VERSION ""

NS_ :

BS_:

BU_:IC_MMI GW AC AVM BCM DSM_D DSM_P FSCM PSR CWC
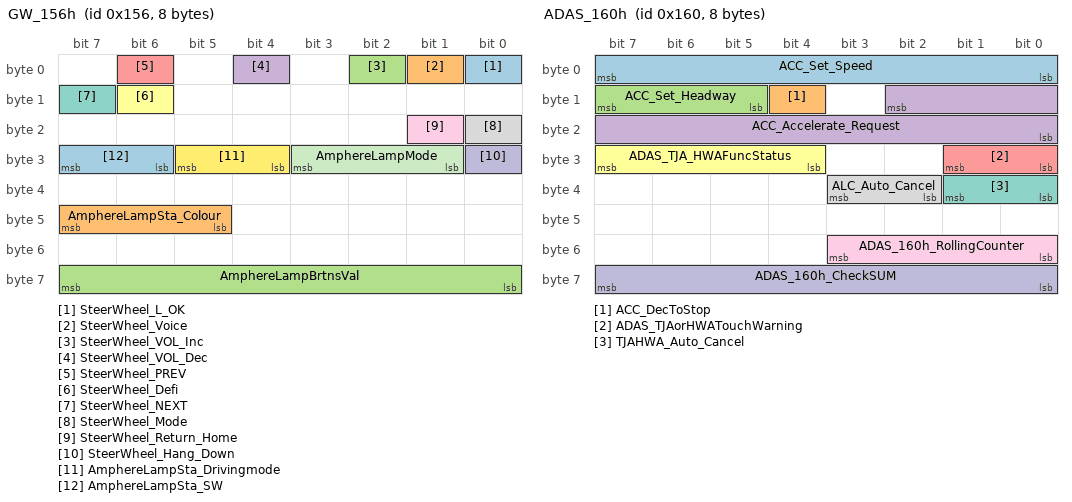
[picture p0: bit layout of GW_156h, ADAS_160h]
BO_ 342 GW_156h: 8 GW
 SG_ SteerWheel_L_OK : 0|1@0+ (1,0) [0|1] "" IC_MMI
 SG_ SteerWheel_Voice : 1|1@0+ (1,0) [0|1] "" IC_MMI
 SG_ SteerWheel_VOL_Inc : 2|1@0+ (1,0) [0|1] "" IC_MMI
 SG_ SteerWheel_VOL_Dec : 4|1@0+ (1,0) [0|1] "" IC_MMI
 SG_ SteerWheel_PREV : 6|1@0+ (1,0) [0|1] "" IC_MMI
 SG_ SteerWheel_Defi : 14|1@0+ (1,0) [0|1] "" IC_MMI
 SG_ SteerWheel_NEXT : 15|1@0+ (1,0) [0|1] "" IC_MMI
 SG_ SteerWheel_Mode : 16|1@0+ (1,0) [0|1] "" IC_MMI
 SG_ SteerWheel_Return_Home : 17|1@0+ (1,0) [0|1] "" IC_MMI
 SG_ SteerWheel_Hang_Down : 24|1@0+ (1,0) [0|1] "" IC_MMI
 SG_ AmphereLampMode : 27|3@0+ (1,0) [0|7] "" IC_MMI
 SG_ AmphereLampSta_Drivingmode : 29|2@0+ (1,0) [0|3] "" IC_MMI
 SG_ AmphereLampSta_SW : 31|2@0+ (1,0) [0|3] "" IC_MMI
 SG_ AmphereLampSta_Colour : 47|3@0+ (1,0) [0|7] "" IC_MMI
 SG_ AmphereLampBrtnsVal : 63|8@0+ (1,0) [0|100] "%" IC_MMI

BO_ 586 ACU_24Ah: 8 GW
 SG_ ACU_AirBagSysWrnLmpCmd : 4|1@0+ (1,0) [0|1] "" IC_MMI,BCM
 SG_ ACU_Crashinfo : 7|3@0+ (1,0) [0|7] "" IC_MMI,BCM
 SG_ ACU_24Ah_RollingCounter : 51|4@0+ (1,0) [0|15] "" IC_MMI,BCM
 SG_ ACU_24Ah_CheckSUM : 63|8@0+ (1,0) [0|255] "" IC_MMI,BCM

BO_ 352 ADAS_160h: 8 GW
 SG_ ACC_Set_Speed : 7|8@0+ (1,0) [0|255] "kph" IC_MMI
 SG_ ACC_DecToStop : 12|1@0+ (1,0) [0|1] "" Vector__XXX
 SG_ ACC_Set_Headway : 15|3@0+ (1,0) [0|7] "" IC_MMI
 SG_ ACC_Accelerate_Request : 10|11@0+ (0.005,-5) [-5|5] "m/s2" Vector__XXX
 SG_ ADAS_TJAorHWATouchWarning : 25|2@0+ (1,0) [0|3] "" IC_MMI
 SG_ ADAS_TJA_HWAFuncStatus : 31|4@0+ (1,0) [0|10] "" IC_MMI
 SG_ TJAHWA_Auto_Cancel : 33|2@0+ (1,0) [0|3] "" IC_MMI
 SG_ ALC_Auto_Cancel : 35|2@0+ (1,0) [0|3] "" IC_MMI
 SG_ ADAS_160h_RollingCounter : 51|4@0+ (1,0) [0|15] "" IC_MMI
 SG_ ADAS_160h_CheckSUM : 63|8@0+ (1,0) [0|255] "" IC_MMI

BO_ 354 ADAS_162h: 8 GW
 SG_ AEB_ABA_Level : 1|2@0+ (1,0) [0|3] "" AVM
 SG_ AEB_ABA_Req : 2|1@0+ (1,0) [0|1] "" AVM
 SG_ AEB_Prefill_Request : 3|1@0+ (1,0) [0|1] "" Vector__XXX
 SG_ AEB_AWB_Req : 4|1@0+ (1,0) [0|1] "" Vector__XXX
 SG_ AEB_State : 7|3@0+ (1,0) [0|7] "" IC_MMI
 SG_ AEB_DecCtlReq : 16|1@0+ (1,0) [0|1] "" AVM
 SG_ FCW_State : 19|3@0+ (1,0) [0|7] "" IC_MMI
 SG_ AEB_Decelerate_Request : 15|12@0+ (0.01,-20.47) [-20.47|20.47] "m/s2" Vector__XXX
 SG_ ACC_MinBraking : 24|1@0+ (1,0) [0|1] "" AVM
 SG_ ADAS_Sensorstatus : 27|3@0+ (1,0) [0|7] "" IC_MMI
 SG_ HW_Warning_Level : 29|2@0+ (1,0) [0|3] "" IC_MMI
 SG_ FCW_Warning_Level : 31|2@0+ (1,0) [0|3] "" IC_MMI
 SG_ ACC_CIPV_Indicator : 33|1@0+ (1,0) [0|1] "" IC_MMI
 SG_ ACC_Auto_Cancel : 35|2@0+ (1,0) [0|2] "" IC_MMI
 SG_ ACC_Driver_Cancel : 36|1@0+ (1,0) [0|1] "" IC_MMI
 SG_ ACC_ModeReq : 39|3@0+ (1,0) [0|7] "" IC_MMI,AVM
 SG_ AEB_AWB_Level : 41|2@0+ (1,0) [0|3] "" AVM
 SG_ ACC_ShutDownMode : 43|2@0+ (1,0) [0|3] "" AVM
 SG_ ACC_DriveOff : 44|1@0+ (1,0) [0|1] "" AVM
 SG_ ACC_BrkPreferred : 45|1@0+ (1,0) [0|1] "" AVM
 SG_ ACC_Go_Indicator : 46|1@0+ (1,0) [0|1] "" IC_MMI
 SG_ ACC_Takeover_Indicator : 47|1@0+ (1,0) [0|1] "" IC_MMI
 SG_ ADAS_162h_RollingCounter : 51|4@0+ (1,0) [0|15] "" IC_MMI,AVM
 SG_ ADAS_162h_CheckSUM : 63|8@0+ (1,0) [0|255] "" IC_MMI,AVM

BO_ 356 ADAS_164h: 8 GW
 SG_ TSR_State : 2|3@0+ (1,0) [0|4] "" IC_MMI
 SG_ DAS_TSR_Main_Switch : 3|1@0+ (1,0) [0|1] "" IC_MMI
 SG_ IHC_Mainbeam_Request : 4|1@0+ (1,0) [0|1] "" BCM
 SG_ IHC_State : 7|3@0+ (1,0) [0|7] "" IC_MMI,BCM
 SG_ LDW_Line_Detect_Status : 10|3@0+ (1,0) [0|3] "" IC_MMI
 SG_ LDW_Warning : 12|2@0+ (1,0) [0|3] "" IC_MMI
 SG_ LDW_State : 15|3@0+ (1,0) [0|4] "" IC_MMI
 SG_ TSR_Targetspeed_Request : 23|8@0+ (1,0) [0|254] "km/h" IC_MMI
 SG_ LKA_Takeover_Request : 27|1@0+ (1,0) [0|1] "" IC_MMI
 SG_ LKA_Torque_Request_Status : 28|1@0+ (1,0) [0|1] "" Vector__XXX
 SG_ LCK_State : 31|3@0+ (1,0) [0|7] "" IC_MMI
 SG_ LKA_Torque_Request : 26|11@0+ (0.01,-10.24) [-10.24|10.23] "Nm" Vector__XXX
 SG_ ADAS_164h_RollingCounter : 43|4@0+ (1,0) [0|15] "" Vector__XXX
 SG_ LKA_State : 46|3@0+ (1,0) [0|7] "" IC_MMI
 SG_ LKA_Hands_Off_Warning : 47|1@0+ (1,0) [0|1] "" IC_MMI
 SG_ DAS_LDW_Main_Switch : 48|1@0+ (1,0) [0|1] "" IC_MMI
 SG_ DAS_LDW_Sensitivity : 50|2@0+ (1,0) [0|3] "" IC_MMI
 SG_ DAS_FCW_Main_Switch : 51|1@0+ (1,0) [0|1] "" IC_MMI
 SG_ DAS_FCW_Sensitivity : 53|2@0+ (1,0) [0|3] "" IC_MMI
 SG_ DAS_AEB_Main_Switch : 54|1@0+ (1,0) [0|1] "" IC_MMI
 SG_ DAS_IHC_Main_Switch : 55|1@0+ (1,0) [0|1] "" IC_MMI
 SG_ ADAS_164h_CheckSUM : 63|8@0+ (1,0) [0|255] "" IC_MMI

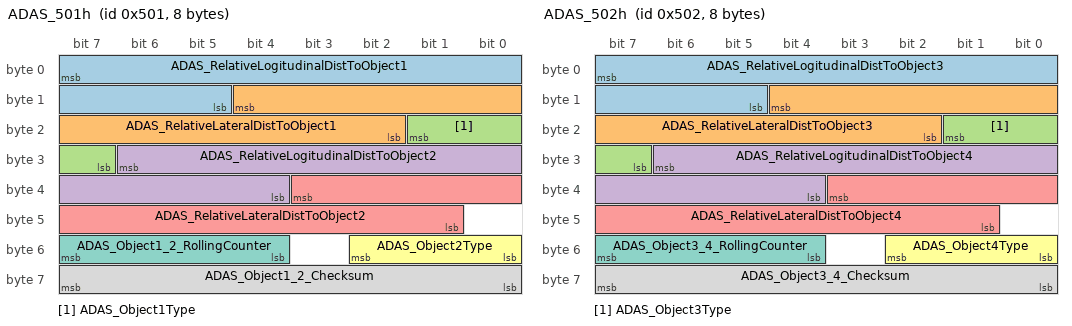
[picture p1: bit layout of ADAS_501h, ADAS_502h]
BO_ 1281 ADAS_501h: 8 GW
 SG_ ADAS_RelativeLogitudinalDistToObject1 : 7|11@0+ (0.1,0) [0|200] "m" IC_MMI
 SG_ ADAS_RelativeLateralDistToObject1 : 12|11@0+ (0.1,-102.4) [-102.4|102.2] "m" IC_MMI
 SG_ ADAS_Object1Type : 17|3@0+ (1,0) [0|7] "" IC_MMI
 SG_ ADAS_RelativeLogitudinalDistToObject2 : 30|11@0+ (0.1,0) [0|200] "m" IC_MMI
 SG_ ADAS_RelativeLateralDistToObject2 : 35|11@0+ (0.1,-102.4) [-102.4|102.2] "m" IC_MMI
 SG_ ADAS_Object2Type : 50|3@0+ (1,0) [0|7] "" IC_MMI
 SG_ ADAS_Object1_2_RollingCounter : 55|4@0+ (1,0) [0|15] "" IC_MMI
 SG_ ADAS_Object1_2_Checksum : 63|8@0+ (1,0) [0|255] "" IC_MMI

BO_ 1282 ADAS_502h: 8 GW
 SG_ ADAS_RelativeLogitudinalDistToObject3 : 7|11@0+ (0.1,0) [0|200] "m" IC_MMI
 SG_ ADAS_RelativeLateralDistToObject3 : 12|11@0+ (0.1,-102.4) [-102.4|102.2] "m" IC_MMI
 SG_ ADAS_Object3Type : 17|3@0+ (1,0) [0|7] "" IC_MMI
 SG_ ADAS_RelativeLogitudinalDistToObject4 : 30|11@0+ (0.1,0) [0|200] "m" IC_MMI
 SG_ ADAS_RelativeLateralDistToObject4 : 35|11@0+ (0.1,-102.4) [-102.4|102.2] "m" IC_MMI
 SG_ ADAS_Object4Type : 50|3@0+ (1,0) [0|7] "" IC_MMI
 SG_ ADAS_Object3_4_RollingCounter : 55|4@0+ (1,0) [0|15] "" IC_MMI
 SG_ ADAS_Object3_4_Checksum : 63|8@0+ (1,0) [0|255] "" IC_MMI

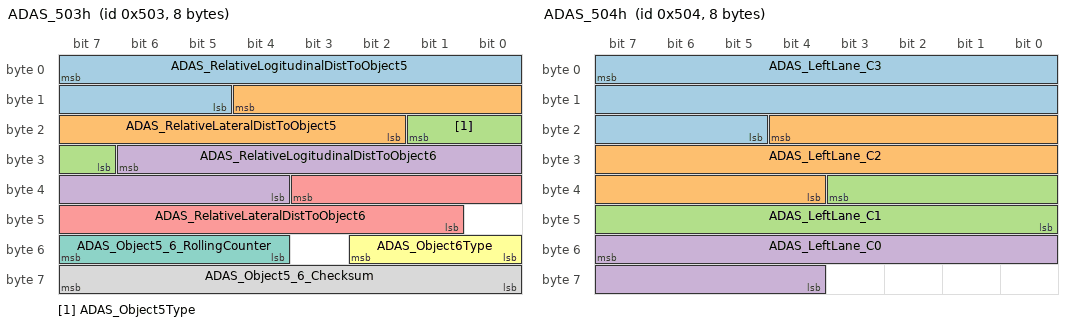
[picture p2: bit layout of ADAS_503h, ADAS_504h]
BO_ 1283 ADAS_503h: 8 GW
 SG_ ADAS_RelativeLogitudinalDistToObject5 : 7|11@0+ (0.1,0) [0|200] "m" IC_MMI
 SG_ ADAS_RelativeLateralDistToObject5 : 12|11@0+ (0.1,-102.4) [-102.4|102.2] "m" IC_MMI
 SG_ ADAS_Object5Type : 17|3@0+ (1,0) [0|7] "" IC_MMI
 SG_ ADAS_RelativeLogitudinalDistToObject6 : 30|11@0+ (0.1,0) [0|200] "m" IC_MMI
 SG_ ADAS_RelativeLateralDistToObject6 : 35|11@0+ (0.1,-102.4) [-102.4|102.2] "m" IC_MMI
 SG_ ADAS_Object6Type : 50|3@0+ (1,0) [0|7] "" IC_MMI
 SG_ ADAS_Object5_6_RollingCounter : 55|4@0+ (1,0) [0|15] "" IC_MMI
 SG_ ADAS_Object5_6_Checksum : 63|8@0+ (1,0) [0|255] "" IC_MMI

BO_ 1284 ADAS_504h: 8 GW
 SG_ ADAS_LeftLane_C3 : 7|19@0+ (5E-09,-0.001) [-0.001|0.001] "1/m2" IC_MMI
 SG_ ADAS_LeftLane_C2 : 20|17@0+ (0.000001,-0.05) [-0.05|0.05] "1/m" IC_MMI
 SG_ ADAS_LeftLane_C1 : 35|12@0+ (0.001,-1.1) [-1.1|1.1] "rad" IC_MMI
 SG_ ADAS_LeftLane_C0 : 55|12@0+ (0.01,-12) [-12|12] "m" IC_MMI

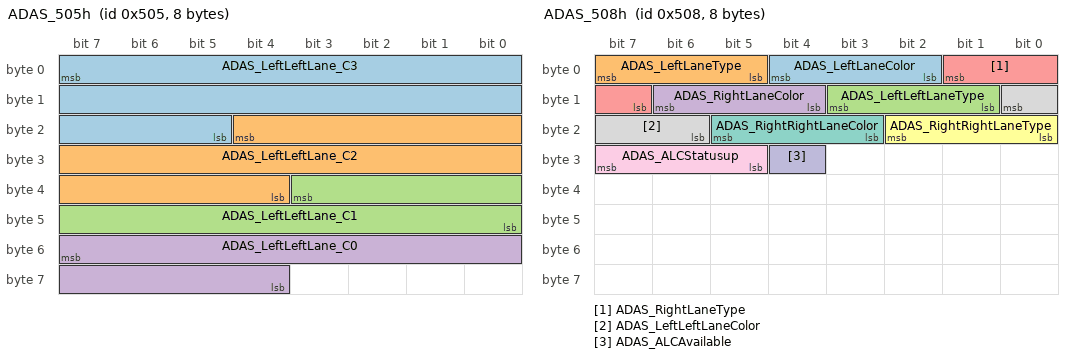
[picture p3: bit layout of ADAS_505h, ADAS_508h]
BO_ 1285 ADAS_505h: 8 GW
 SG_ ADAS_LeftLeftLane_C3 : 7|19@0+ (0.000000005,-0.001) [-0.001|0.001] "1/m2" IC_MMI
 SG_ ADAS_LeftLeftLane_C2 : 20|17@0+ (0.000001,-0.05) [-0.05|0.05] "1/m" IC_MMI
 SG_ ADAS_LeftLeftLane_C1 : 35|12@0+ (0.001,-1.1) [-1.1|1.1] "rad" IC_MMI
 SG_ ADAS_LeftLeftLane_C0 : 55|12@0+ (0.01,-12) [-12|12] "m" IC_MMI

BO_ 1286 ADAS_506h: 8 GW
 SG_ ADAS_RightLane_C3 : 7|19@0+ (0.000000005,-0.001) [-0.001|0.001] "1/m2" IC_MMI
 SG_ ADAS_RightLane_C2 : 20|17@0+ (0.000001,-0.05) [-0.05|0.05] "1/m" IC_MMI
 SG_ ADAS_RightLane_C1 : 35|12@0+ (0.001,-1.1) [-1.1|1.1] "rad" IC_MMI
 SG_ ADAS_RightLane_C0 : 55|12@0+ (0.01,-12) [-12|12] "m" IC_MMI

BO_ 1287 ADAS_507h: 8 GW
 SG_ ADAS_RightRightLane_C3 : 7|19@0+ (0.000000005,-0.001) [-0.001|0.001] "1/m2" IC_MMI
 SG_ ADAS_RightRightLane_C2 : 20|17@0+ (0.000001,-0.05) [-0.05|0.05] "1/m" IC_MMI
 SG_ ADAS_RightRightLane_C1 : 35|12@0+ (0.001,-1.1) [-1.1|1.1] "rad" IC_MMI
 SG_ ADAS_RightRightLane_C0 : 55|12@0+ (0.01,-12) [-12|12] "m" IC_MMI

BO_ 1288 ADAS_508h: 8 GW
 SG_ ADAS_LeftLaneColor : 4|3@0+ (1,0) [0|7] "" IC_MMI
 SG_ ADAS_LeftLaneType : 7|3@0+ (1,0) [0|7] "" IC_MMI
 SG_ ADAS_LeftLeftLaneType : 11|3@0+ (1,0) [0|7] "" IC_MMI
 SG_ ADAS_RightLaneColor : 14|3@0+ (1,0) [0|7] "" IC_MMI
 SG_ ADAS_RightLaneType : 1|3@0+ (1,0) [0|7] "" IC_MMI
 SG_ ADAS_RightRightLaneType : 18|3@0+ (1,0) [0|7] "" IC_MMI
 SG_ ADAS_RightRightLaneColor : 21|3@0+ (1,0) [0|7] "" IC_MMI
 SG_ ADAS_LeftLeftLaneColor : 8|3@0+ (1,0) [0|7] "" IC_MMI
 SG_ ADAS_ALCStatusup : 31|3@0+ (1,0) [0|7] "" IC_MMI
 SG_ ADAS_ALCAvailable : 28|1@0+ (1,0) [0|1] "" IC_MMI

BO_ 384 APA_180h: 8 GW
 SG_ APA_MMI_ConnectStatus : 3|4@0+ (1,0) [0|7] "" IC_MMI
 SG_ APA_MMI_EcuStatus : 7|4@0+ (1,0) [0|3] "" IC_MMI
 SG_ APA_MMI_VideoOutputStatus : 9|2@0+ (1,0) [0|3] "" IC_MMI
 SG_ APA_MMI_3DViewModeStatus : 13|4@0+ (1,0) [0|15] "" IC_MMI
 SG_ APA_MMI_AVM3DViewSwitch : 23|8@0+ (1,0) [0|255] "" IC_MMI
 SG_ APA_Status : 26|3@0+ (1,0) [0|7] "" IC_MMI
 SG_ PAS_APA_Mode : 30|3@0+ (1,0) [0|7] "" IC_MMI
 SG_ PSA_APA_SensorStsLR_RL : 32|1@0+ (1,0) [0|1] "" IC_MMI
 SG_ PSA_APA_SensorStsLR_RR : 33|1@0+ (1,0) [0|1] "" IC_MMI
 SG_ PSA_APA_SensorStsSR_RL : 34|1@0+ (1,0) [0|1] "" IC_MMI
 SG_ PSA_APA_SensorStsSR_RML : 35|1@0+ (1,0) [0|1] "" IC_MMI
 SG_ PAS_APA_SensorStsSR_RMR : 36|1@0+ (1,0) [0|1] "" IC_MMI
 SG_ PAS_APA_SensorStsSR_RR : 37|1@0+ (1,0) [0|1] "" IC_MMI
 SG_ PSA_APA_SensorStsLR_FL : 38|1@0+ (1,0) [0|1] "" IC_MMI
 SG_ PSA_APA_SensorStsLR_FR : 39|1@0+ (1,0) [0|1] "" IC_MMI
 SG_ PSA_APA_SensorStsSR_FL : 40|1@0+ (1,0) [0|1] "" IC_MMI
 SG_ PSA_APA_SensorStsSR_FML : 41|1@0+ (1,0) [0|1] "" IC_MMI
 SG_ PAS_APA_SensorStsSR_FMR : 42|1@0+ (1,0) [0|1] "" IC_MMI
 SG_ PAS_APA_SensorStsSR_FR : 43|1@0+ (1,0) [0|1] "" IC_MMI

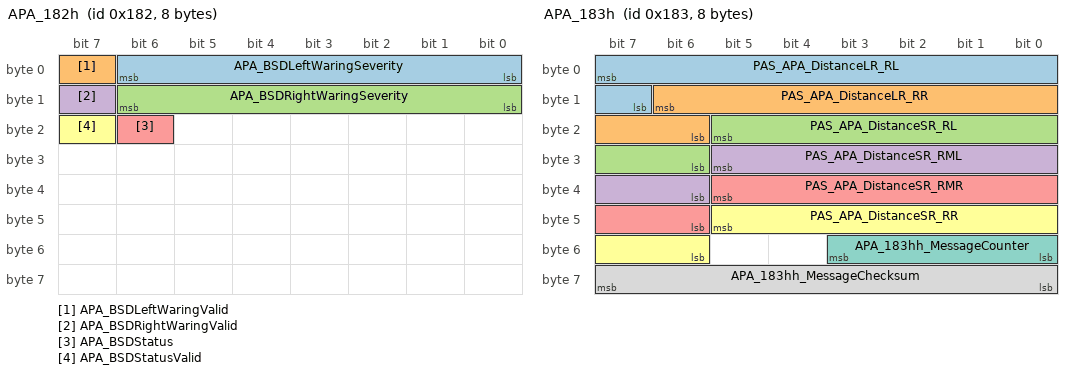
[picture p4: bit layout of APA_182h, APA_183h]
BO_ 386 APA_182h: 8 GW
 SG_ APA_BSDLeftWaringSeverity : 6|7@0+ (1,0) [0|126] "" IC_MMI
 SG_ APA_BSDLeftWaringValid : 7|1@0+ (1,0) [0|1] "" IC_MMI
 SG_ APA_BSDRightWaringSeverity : 14|7@0+ (1,0) [0|126] "" IC_MMI
 SG_ APA_BSDRightWaringValid : 15|1@0+ (1,0) [0|1] "" IC_MMI
 SG_ APA_BSDStatus : 22|1@0+ (1,0) [0|1] "" IC_MMI
 SG_ APA_BSDStatusValid : 23|1@0+ (1,0) [0|1] "" IC_MMI

BO_ 387 APA_183h: 8 GW
 SG_ PAS_APA_DistanceLR_RL : 7|9@0+ (0.01,0) [0|5] "m" IC_MMI
 SG_ PAS_APA_DistanceLR_RR : 14|9@0+ (0.01,0) [0|5] "m" IC_MMI
 SG_ PAS_APA_DistanceSR_RL : 21|8@0+ (0.01,0) [0|2.5] "m" IC_MMI
 SG_ PAS_APA_DistanceSR_RML : 29|8@0+ (0.01,0) [0|2.5] "m" IC_MMI
 SG_ PAS_APA_DistanceSR_RMR : 37|8@0+ (0.01,0) [0|2.5] "m" IC_MMI
 SG_ PAS_APA_DistanceSR_RR : 45|8@0+ (0.01,0) [0|2.5] "m" IC_MMI
 SG_ APA_183hh_MessageCounter : 51|4@0+ (1,0) [0|15] "" IC_MMI
 SG_ APA_183hh_MessageChecksum : 63|8@0+ (1,0) [0|255] "" IC_MMI

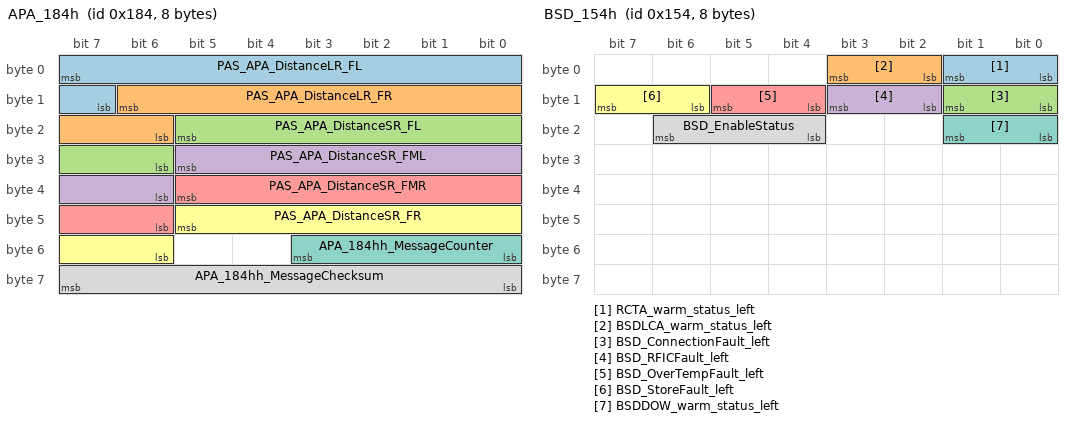
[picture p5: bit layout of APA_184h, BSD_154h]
BO_ 388 APA_184h: 8 GW
 SG_ PAS_APA_DistanceLR_FL : 7|9@0+ (0.01,0) [0|5] "m" IC_MMI
 SG_ PAS_APA_DistanceLR_FR : 14|9@0+ (0.01,0) [0|5] "m" IC_MMI
 SG_ PAS_APA_DistanceSR_FL : 21|8@0+ (0.01,0) [0|2.5] "m" IC_MMI
 SG_ PAS_APA_DistanceSR_FML : 29|8@0+ (0.01,0) [0|2.5] "m" IC_MMI
 SG_ PAS_APA_DistanceSR_FMR : 37|8@0+ (0.01,0) [0|2.5] "m" IC_MMI
 SG_ PAS_APA_DistanceSR_FR : 45|8@0+ (0.01,0) [0|2.5] "m" IC_MMI
 SG_ APA_184hh_MessageCounter : 51|4@0+ (1,0) [0|15] "" IC_MMI
 SG_ APA_184hh_MessageChecksum : 63|8@0+ (1,0) [0|255] "" IC_MMI

BO_ 784 APA_310h: 8 GW
 SG_ APA_AVM_MCU_Version : 15|24@0+ (1,0) [0|16777214] "" IC_MMI
 SG_ APA_AVM_BSP_Version : 39|24@0+ (1,0) [0|16777214] "" IC_MMI

BO_ 786 APA_312h: 8 GW
 SG_ APA_AVM_ZADAS_Version : 15|24@0+ (1,0) [0|16777214] "" IC_MMI
 SG_ APA_Avm3d_licenseStatus : 33|2@0+ (1,0) [0|3] "" IC_MMI
 SG_ APA_BSD_licenseStatus : 35|2@0+ (1,0) [0|3] "" IC_MMI

BO_ 512 BMS_200h: 8 GW
 SG_ BMS_Sys_SumVoltage : 7|16@0+ (0.1,0) [0|6000] "V" IC_MMI,AC
 SG_ BMS_Sys_SumCurrent : 23|16@0+ (0.1,-3000) [-3000|3000] "A" IC_MMI,AC
 SG_ BMS_battery_outside_Voltage : 39|16@0+ (0.1,0) [0|6000] "V" Vector__XXX

BO_ 514 BMS_202h: 8 GW
 SG_ BMS_Err_DischrgAnodeRelay : 1|2@0+ (1,0) [0|3] "" Vector__XXX
 SG_ BMS_DischargeAnodeRelay_status : 3|2@0+ (1,0) [0|3] "" Vector__XXX
 SG_ BMS_Boot_Detection : 4|1@0+ (1,0) [0|1] "" Vector__XXX
 SG_ BMS_A : 5|1@0+ (1,0) [0|1] "" Vector__XXX
 SG_ BMS_Relay_HEAT : 11|2@0+ (1,0) [0|3] "" Vector__XXX
 SG_ BMS_Err_PrechargeAnodeRelay : 13|2@0+ (1,0) [0|3] "" Vector__XXX
 SG_ BMS_Precharge_anode_Relay_status : 15|2@0+ (1,0) [0|3] "" Vector__XXX
 SG_ BMS_ChrgHeatColEnable : 26|3@0+ (1,0) [0|7] "" Vector__XXX
 SG_ BMS_Sys_ChgorDisChrgSts : 28|2@0+ (1,0) [0|3] "" IC_MMI,AC
 SG_ BMS_FastChrgSts : 31|3@0+ (1,0) [0|7] "" IC_MMI
 SG_ BMS_SlowChrgSts : 34|3@0+ (1,0) [0|7] "" IC_MMI
 SG_ BMS_ChrgCouplesSt : 38|2@0+ (1,0) [0|3] "" IC_MMI
 SG_ BMS_req_ConnectChargeRelay : 41|2@0+ (1,0) [0|3] "" Vector__XXX
 SG_ BMS_request_subscribe_allow : 47|1@0+ (1,0) [0|1] "" Vector__XXX
 SG_ BMS_CC2 : 52|3@0+ (1,0) [0|7] "" Vector__XXX
 SG_ BMS_PauseContinueChrgStus : 54|2@0+ (1,0) [0|3] "" IC_MMI
 SG_ BMS_AllowedChrgMaxPower : 62|7@0+ (1,0) [0|100] "%" IC_MMI

BO_ 518 BMS_206h: 8 GW
 SG_ BMS_battery_WaterTemp_in : 2|11@0+ (0.1,-40) [-40|100] "℃" AC
 SG_ BMS_battery_WaterTemp_out : 23|8@0+ (1,-40) [-40|100] "℃" AC
 SG_ BMS_FlowRateReq : 31|8@0+ (1,0) [0|100] "%" AC
 SG_ BMS_InletWaterTempTarget : 39|8@0+ (0.5,-40) [-40|87] "℃" AC
 SG_ BMS_ThermalManageReq : 43|2@0+ (1,0) [0|3] "" IC_MMI,AC

BO_ 524 BMS_20Ch: 8 GW
 SG_ BMS_Powertrain_System_fault : 1|2@0+ (1,0) [0|3] "" IC_MMI
 SG_ BMS_cell_Voltage_low : 5|2@0+ (1,0) [0|3] "" IC_MMI
 SG_ BMS_cell_Voltage_High : 7|2@0+ (1,0) [0|3] "" IC_MMI
 SG_ BMS_Battery_LowTemp_warning : 9|2@0+ (1,0) [0|3] "" IC_MMI
 SG_ BMS_Battery_HighTemp_warning : 11|2@0+ (1,0) [0|3] "" IC_MMI
 SG_ BMS_SOCHigh_Warning : 17|2@0+ (1,0) [0|3] "" IC_MMI
 SG_ BMS_SOCLow_Warning : 19|2@0+ (1,0) [0|3] "" IC_MMI
 SG_ BMS_Battery_SumVoltage_High : 21|2@0+ (1,0) [0|3] "" IC_MMI
 SG_ BMS_Battery_SumVoltage_Low : 23|2@0+ (1,0) [0|3] "" IC_MMI
 SG_ BMS_HVBatCellDiffFalt : 25|2@0+ (1,0) [0|3] "" IC_MMI
 SG_ BMS_SOCJump_Warning : 31|2@0+ (1,0) [0|3] "" IC_MMI
 SG_ BMS_BatNotMatchFlt : 39|2@0+ (1,0) [0|3] "" IC_MMI
 SG_ BMS_Err_ISO_LOW : 41|2@0+ (1,0) [0|3] "" IC_MMI
 SG_ BMS_Err_ChgCurrent_High : 43|2@0+ (1,0) [0|3] "" IC_MMI
 SG_ BMS_Err_DchCurrent_High : 45|2@0+ (1,0) [0|3] "" IC_MMI
 SG_ BMS_Err_DtT_High : 47|2@0+ (1,0) [0|3] "" IC_MMI
 SG_ ThermalManage_System_fault : 49|2@0+ (1,0) [0|3] "" Vector__XXX
 SG_ BMS_Err_comunicacion : 51|2@0+ (1,0) [0|3] "" IC_MMI
 SG_ BMS_Err_InterLock : 52|1@0+ (1,0) [0|1] "" IC_MMI
 SG_ BMS_Circuit_Protection : 53|1@0+ (1,0) [0|1] "" IC_MMI
 SG_ BMS_FeedFault : 55|2@0+ (1,0) [0|3] "" IC_MMI
 SG_ BMS_TotalErrNumber : 63|8@0+ (1,0) [0|254] "" IC_MMI

BO_ 528 BMS_210h: 8 GW
 SG_ BMS_Sys_MinCellV : 7|16@0+ (0.001,0) [0|5] "V" IC_MMI
 SG_ BMS_Sys_MaxCellV : 23|16@0+ (0.001,0) [0|5] "V" IC_MMI
 SG_ BMS_Sys_MinCellV_No : 39|8@0+ (1,0) [0|255] "" IC_MMI
 SG_ BMS_Sys_MaxCellV_No : 47|8@0+ (1,0) [0|255] "" IC_MMI

BO_ 530 BMS_212h: 8 GW
 SG_ BMS_Sys_MinCellT : 7|8@0+ (1,-50) [-50|204] "℃" IC_MMI
 SG_ BMS_Sys_MaxCellT : 15|8@0+ (1,-50) [-50|204] "℃" IC_MMI
 SG_ BMS_Sys_MinCellT_No : 23|8@0+ (1,0) [0|254] "℃" IC_MMI
 SG_ BMS_Sys_MaxCellT_No : 31|8@0+ (1,0) [0|254] "℃" IC_MMI
 SG_ BMS_FastChrgTemp : 39|8@0+ (1,-50) [-50|204] "℃" IC_MMI

BO_ 534 BMS_216h: 8 GW
 SG_ BMS_PosInsulationResistance : 7|16@0+ (1,0) [0|60000] "kΩ" Vector__XXX
 SG_ BMS_NegInsulationResistance : 23|16@0+ (1,0) [0|60000] "kΩ" Vector__XXX
 SG_ BMS_Sys_SOC : 39|8@0+ (1,0) [0|100] "%" IC_MMI
 SG_ BMS_Sys_SOH : 47|8@0+ (1,0) [0|100] "%" IC_MMI

BO_ 340 BSD_154h: 8 GW
 SG_ RCTA_warm_status_left : 1|2@0+ (1,0) [0|3] "" IC_MMI
 SG_ BSDLCA_warm_status_left : 3|2@0+ (1,0) [0|3] "" IC_MMI
 SG_ BSD_ConnectionFault_left : 9|2@0+ (1,0) [0|3] "" IC_MMI
 SG_ BSD_RFICFault_left : 11|2@0+ (1,0) [0|3] "" IC_MMI
 SG_ BSD_OverTempFault_left : 13|2@0+ (1,0) [0|3] "" IC_MMI
 SG_ BSD_StoreFault_left : 15|2@0+ (1,0) [0|3] "" IC_MMI
 SG_ BSDDOW_warm_status_left : 17|2@0+ (1,0) [0|3] "" IC_MMI
 SG_ BSD_EnableStatus : 22|3@0+ (1,0) [0|7] "" IC_MMI

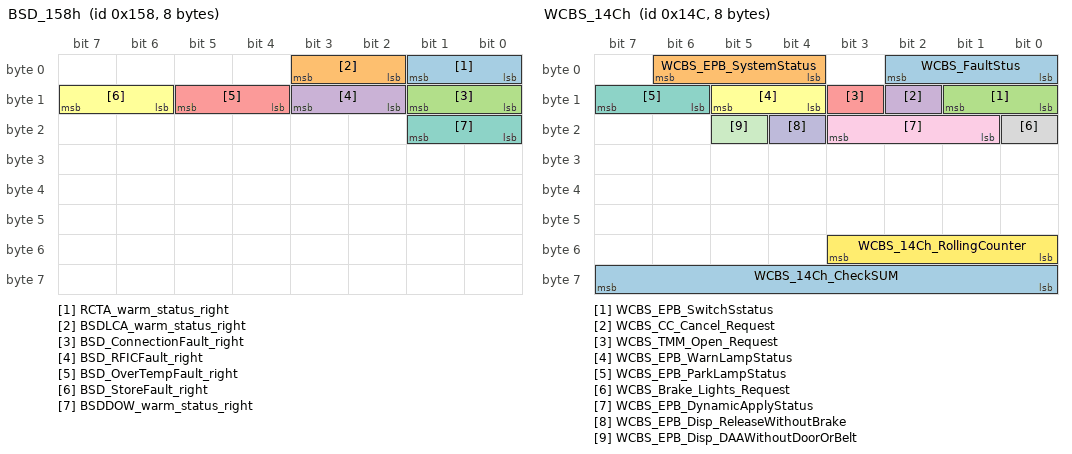
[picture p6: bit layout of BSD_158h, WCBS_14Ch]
BO_ 344 BSD_158h: 8 GW
 SG_ RCTA_warm_status_right : 1|2@0+ (1,0) [0|3] "" IC_MMI
 SG_ BSDLCA_warm_status_right : 3|2@0+ (1,0) [0|3] "" IC_MMI
 SG_ BSD_ConnectionFault_right : 9|2@0+ (1,0) [0|3] "" IC_MMI
 SG_ BSD_RFICFault_right : 11|2@0+ (1,0) [0|3] "" IC_MMI
 SG_ BSD_OverTempFault_right : 13|2@0+ (1,0) [0|3] "" IC_MMI
 SG_ BSD_StoreFault_right : 15|2@0+ (1,0) [0|3] "" IC_MMI
 SG_ BSDDOW_warm_status_right : 17|2@0+ (1,0) [0|3] "" IC_MMI

BO_ 332 WCBS_14Ch: 8 GW
 SG_ WCBS_FaultStus : 2|3@0+ (1,0) [0|7] "" IC_MMI
 SG_ WCBS_EPB_SystemStatus : 6|3@0+ (1,0) [0|7] "" IC_MMI
 SG_ WCBS_EPB_SwitchSstatus : 9|2@0+ (1,0) [0|3] "" IC_MMI
 SG_ WCBS_CC_Cancel_Request : 10|1@0+ (1,0) [0|1] "" Vector__XXX
 SG_ WCBS_TMM_Open_Request : 11|1@0+ (1,0) [0|1] "" Vector__XXX
 SG_ WCBS_EPB_WarnLampStatus : 13|2@0+ (1,0) [0|3] "" IC_MMI
 SG_ WCBS_EPB_ParkLampStatus : 15|2@0+ (1,0) [0|3] "" IC_MMI
 SG_ WCBS_Brake_Lights_Request : 16|1@0+ (1,0) [0|1] "" BCM
 SG_ WCBS_EPB_DynamicApplyStatus : 19|3@0+ (1,0) [0|7] "" Vector__XXX
 SG_ WCBS_EPB_Disp_ReleaseWithoutBrake : 20|1@0+ (1,0) [0|1] "" IC_MMI
 SG_ WCBS_EPB_Disp_DAAWithoutDoorOrBelt : 21|1@0+ (1,0) [0|1] "" IC_MMI
 SG_ WCBS_14Ch_RollingCounter : 51|4@0+ (1,0) [0|15] "" IC_MMI,BCM
 SG_ WCBS_14Ch_CheckSUM : 63|8@0+ (1,0) [0|255] "" IC_MMI,BCM

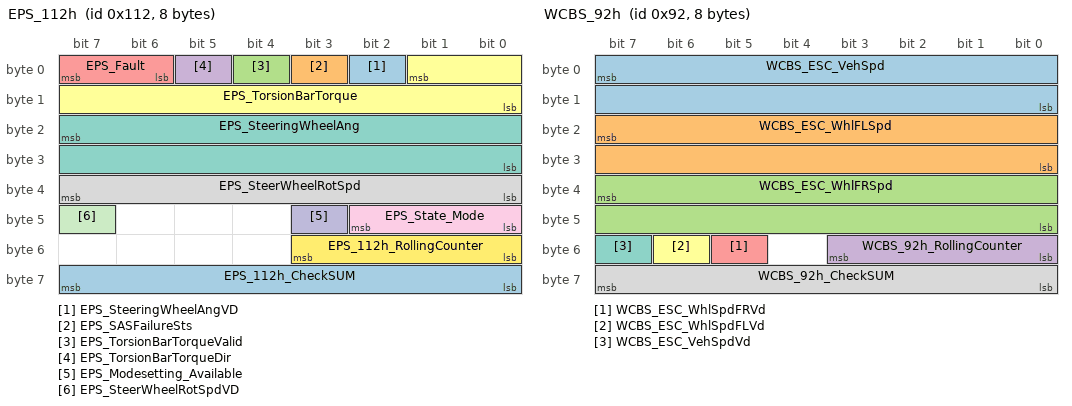
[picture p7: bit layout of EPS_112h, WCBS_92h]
BO_ 274 EPS_112h: 8 GW
 SG_ EPS_SteeringWheelAngVD : 2|1@0+ (1,0) [0|1] "" IC_MMI,AVM
 SG_ EPS_SASFailureSts : 3|1@0+ (1,0) [0|1] "" IC_MMI,AVM
 SG_ EPS_TorsionBarTorqueValid : 4|1@0+ (1,0) [0|1] "" Vector__XXX
 SG_ EPS_TorsionBarTorqueDir : 5|1@0+ (1,0) [0|1] "" Vector__XXX
 SG_ EPS_Fault : 7|2@0+ (1,0) [0|3] "" IC_MMI
 SG_ EPS_TorsionBarTorque : 1|10@0+ (0.01,0) [0|8] "Nm" Vector__XXX
 SG_ EPS_SteeringWheelAng : 23|16@0+ (0.1,-780) [-780|780] "degree" IC_MMI,AVM
 SG_ EPS_SteerWheelRotSpd : 39|8@0+ (4,0) [0|1016] "deg/s" IC_MMI
 SG_ EPS_State_Mode : 42|3@0+ (1,0) [0|7] "" IC_MMI
 SG_ EPS_Modesetting_Available : 43|1@0+ (1,0) [0|1] "" IC_MMI
 SG_ EPS_SteerWheelRotSpdVD : 47|1@0+ (1,0) [0|1] "" IC_MMI
 SG_ EPS_112h_RollingCounter : 51|4@0+ (1,0) [0|15] "" Vector__XXX
 SG_ EPS_112h_CheckSUM : 63|8@0+ (1,0) [0|255] "" Vector__XXX

BO_ 144 WCBS_90h: 8 GW
 SG_ WCBS_ESC_TCSActive : 0|1@0+ (1,0) [0|1] "" IC_MMI
 SG_ WCBS_ESC_HHC_Failure : 1|1@0+ (1,0) [0|1] "" IC_MMI
 SG_ WCBS_ESC_HHCActive : 2|1@0+ (1,0) [0|1] "" IC_MMI
 SG_ WCBS_ESC_EBDFailed : 3|1@0+ (1,0) [0|1] "" IC_MMI
 SG_ WCBS_ESC_EBDActive : 4|1@0+ (1,0) [0|1] "" IC_MMI
 SG_ WCBS_ESC_ABSFailed : 6|1@0+ (1,0) [0|1] "" IC_MMI
 SG_ WCBS_ESC_ABSActive : 7|1@0+ (1,0) [0|1] "" IC_MMI
 SG_ WCBS_ESC_AVH_Status : 9|2@0+ (1,0) [0|3] "" IC_MMI
 SG_ WCBS_ESC_CST_Active : 10|1@0+ (1,0) [0|1] "" Vector__XXX
 SG_ WCBS_ESC_Sw : 11|1@0+ (1,0) [0|1] "" IC_MMI
 SG_ WCBS_ESC_HBAActive : 12|1@0+ (1,0) [0|1] "" IC_MMI
 SG_ WCBS_ESC_VDCFailure : 13|1@0+ (1,0) [0|1] "" IC_MMI
 SG_ WCBS_ESC_VDCActive : 14|1@0+ (1,0) [0|1] "" IC_MMI
 SG_ WCBS_ESC_TCSFailure : 15|1@0+ (1,0) [0|1] "" IC_MMI
 SG_ WCBS_ESC_NoBrakeForce : 22|1@0+ (1,0) [0|1] "" Vector__XXX
 SG_ WCBS_ESC_VehicleStandStill : 23|1@0+ (1,0) [0|1] "" Vector__XXX
 SG_ WCBS_ESC_BrkPrs : 19|12@0+ (0.1,0) [0|190] "bar" Vector__XXX
 SG_ WCBS_ESC_ABP_Available : 32|1@0+ (1,0) [0|1] "" Vector__XXX
 SG_ WCBS_ESC_APB_Active : 33|1@0+ (1,0) [0|1] "" Vector__XXX
 SG_ WCBS_ESC_AEB_Available : 34|1@0+ (1,0) [0|1] "" Vector__XXX
 SG_ WCBS_ESC_AEB_Active : 35|1@0+ (1,0) [0|1] "" Vector__XXX
 SG_ WCBS_ESC_AWB_Available : 36|1@0+ (1,0) [0|1] "" Vector__XXX
 SG_ WCBS_ESC_AWB_Active : 37|1@0+ (1,0) [0|1] "" Vector__XXX
 SG_ WCBS_ESC_Brake_Light_Control : 38|1@0+ (1,0) [0|1] "" BCM
 SG_ WCBS_ESC_BrkPrsVd : 39|1@0+ (1,0) [0|1] "" Vector__XXX
 SG_ WCBS_ESC_AVH_Warning1 : 40|1@0+ (1,0) [0|1] "" IC_MMI
 SG_ WCBS_ESC_AVH_Warning2 : 41|1@0+ (1,0) [0|1] "" IC_MMI
 SG_ WCBS_ESC_AVH_Warning3 : 42|1@0+ (1,0) [0|1] "" IC_MMI
 SG_ WCBS_ESC_HazLightReq : 44|1@0+ (1,0) [0|1] "" BCM
 SG_ WCBS_ESC_HDC_CtlSts : 46|2@0+ (1,0) [0|3] "" IC_MMI
 SG_ WCBS_ESC_HDC_Available : 47|1@0+ (1,0) [0|1] "" IC_MMI
 SG_ WCBS_90h_RollingCounter : 51|4@0+ (1,0) [0|15] "" IC_MMI,BCM
 SG_ WCBS_ESC_ABA_Available : 52|1@0+ (1,0) [0|1] "" Vector__XXX
 SG_ WCBS_ESC_ABA_Active : 53|1@0+ (1,0) [0|1] "" Vector__XXX
 SG_ WCBS_90h_CheckSUM : 63|8@0+ (1,0) [0|255] "" IC_MMI,BCM

BO_ 146 WCBS_92h: 8 GW
 SG_ WCBS_ESC_VehSpd : 7|16@0+ (0.05625,0) [0|299.98125] "km/h" IC_MMI,AC,AVM,BCM,DSM_D,DSM_P
 SG_ WCBS_ESC_WhlFLSpd : 23|16@0+ (0.05625,0) [0|299.98125] "km/h" AVM,BCM
 SG_ WCBS_ESC_WhlFRSpd : 39|16@0+ (0.05625,0) [0|299.98125] "km/h" AVM,BCM
 SG_ WCBS_92h_RollingCounter : 51|4@0+ (1,0) [0|15] "" IC_MMI,AC,AVM,BCM,DSM_D,DSM_P
 SG_ WCBS_ESC_WhlSpdFRVd : 53|1@0+ (1,0) [0|1] "" AVM,BCM
 SG_ WCBS_ESC_WhlSpdFLVd : 54|1@0+ (1,0) [0|1] "" AVM,BCM
 SG_ WCBS_ESC_VehSpdVd : 55|1@0+ (1,0) [0|1] "" IC_MMI,AC,AVM,BCM,DSM_D,DSM_P
 SG_ WCBS_92h_CheckSUM : 63|8@0+ (1,0) [0|255] "" IC_MMI,AC,AVM,BCM,DSM_D,DSM_P

BO_ 594 MCU_F_252h: 8 GW
 SG_ MCU_F_FailureNum : 7|8@0+ (1,0) [0|255] "" Vector__XXX
 SG_ MCU_F_ResolverFault : 8|1@0+ (1,0) [0|1] "" IC_MMI
 SG_ MCU_F_Err_IGBT : 9|1@0+ (1,0) [0|1] "" IC_MMI
 SG_ MCU_F_CurrentOverload : 11|2@0+ (1,0) [0|3] "" IC_MMI
 SG_ MCU_F_Controllertemp_Status : 13|2@0+ (1,0) [0|3] "" IC_MMI
 SG_ MCU_F_stDischg : 15|2@0+ (1,0) [0|3] "" Vector__XXX
 SG_ MCU_F_SpeedOtLoopFalult : 18|1@0+ (1,0) [0|1] "" IC_MMI
 SG_ MCU_F_MdTepErr : 19|1@0+ (1,0) [0|1] "" IC_MMI
 SG_ MCU_F_ControllerOverVolt_Status : 21|2@0+ (1,0) [0|3] "" IC_MMI
 SG_ MCU_F_MotorTemp_Fault : 23|2@0+ (1,0) [0|3] "" IC_MMI
 SG_ MCU_F_MotorOverSpd : 25|1@0+ (1,0) [0|1] "" IC_MMI
 SG_ MCU_F_VCUCommErr : 26|1@0+ (1,0) [0|1] "" Vector__XXX
 SG_ MCU_F_ControllerLowUnderVolt_Status : 27|1@0+ (1,0) [0|1] "" IC_MMI
 SG_ MCU_F_ControllerUnderVolt_Status : 29|2@0+ (1,0) [0|3] "" IC_MMI
 SG_ MCU_F_ControllerFault : 17|3@0+ (1,0) [0|7] "" IC_MMI
 SG_ MCU_F_unload_status : 33|2@0+ (1,0) [0|3] "" Vector__XXX
 SG_ FMCU_HV_Interlock_Falult : 35|2@0+ (1,0) [0|3] "" IC_MMI
 SG_ FMCU_Uncap_Falult : 37|2@0+ (1,0) [0|3] "" IC_MMI
 SG_ MCU_F_MotTepErr : 39|1@0+ (1,0) [0|1] "" IC_MMI

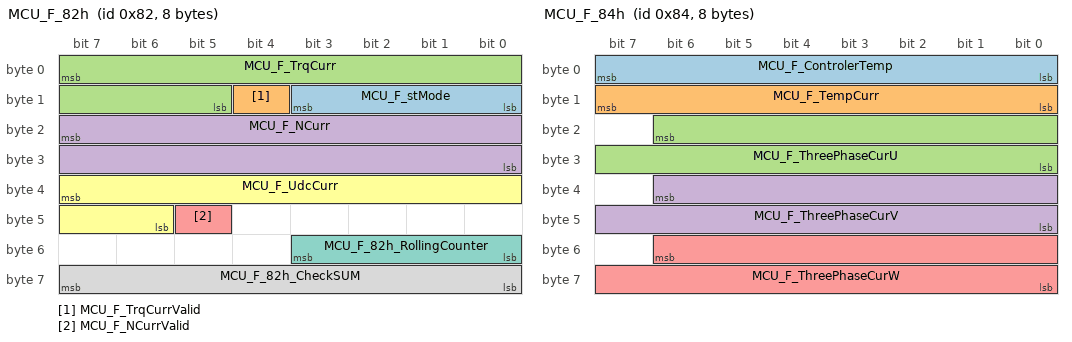
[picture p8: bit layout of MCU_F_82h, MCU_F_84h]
BO_ 130 MCU_F_82h: 8 GW
 SG_ MCU_F_stMode : 11|4@0+ (1,0) [0|15] "" Vector__XXX
 SG_ MCU_F_TrqCurrValid : 12|1@0+ (1,0) [0|1] "" Vector__XXX
 SG_ MCU_F_TrqCurr : 7|11@0+ (1,-1024) [-1024|1023] "Nm" Vector__XXX
 SG_ MCU_F_NCurr : 23|16@0+ (1,-32768) [-32768|32767] "1/min" IC_MMI,AVM,BCM
 SG_ MCU_F_NCurrValid : 45|1@0+ (1,0) [0|1] "" IC_MMI,AVM,BCM
 SG_ MCU_F_UdcCurr : 39|10@0+ (1,0) [0|1021] "V" Vector__XXX
 SG_ MCU_F_82h_RollingCounter : 51|4@0+ (1,0) [0|15] "" IC_MMI,AVM,BCM
 SG_ MCU_F_82h_CheckSUM : 63|8@0+ (1,0) [0|255] "" IC_MMI,AVM,BCM

BO_ 132 MCU_F_84h: 8 GW
 SG_ MCU_F_ControlerTemp : 7|8@0+ (1,-50) [-50|205] "℃" IC_MMI
 SG_ MCU_F_TempCurr : 15|8@0+ (1,-50) [-50|205] "℃" IC_MMI
 SG_ MCU_F_ThreePhaseCurU : 22|15@0+ (0.1,-1000) [-1000|1000] "A" Vector__XXX
 SG_ MCU_F_ThreePhaseCurV : 38|15@0+ (0.1,-1000) [-1000|1000] "A" Vector__XXX
 SG_ MCU_F_ThreePhaseCurW : 54|15@0+ (0.1,-1000) [-1000|1000] "A" Vector__XXX

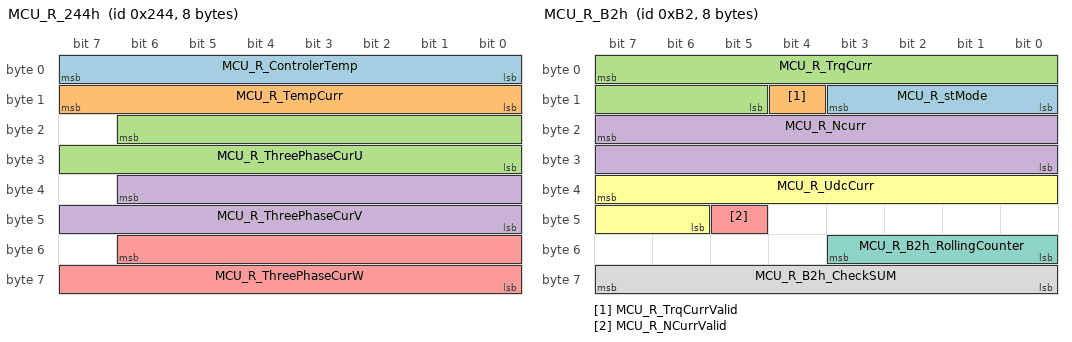
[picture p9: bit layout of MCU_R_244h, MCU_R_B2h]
BO_ 580 MCU_R_244h: 8 GW
 SG_ MCU_R_ControlerTemp : 7|8@0+ (1,-50) [-50|205] "℃" IC_MMI
 SG_ MCU_R_TempCurr : 15|8@0+ (1,-50) [-50|205] "℃" IC_MMI
 SG_ MCU_R_ThreePhaseCurU : 22|15@0+ (0.1,-1000) [-1000|1000] "A" Vector__XXX
 SG_ MCU_R_ThreePhaseCurV : 38|15@0+ (0.1,-1000) [-1000|1000] "A" Vector__XXX
 SG_ MCU_R_ThreePhaseCurW : 54|15@0+ (0.1,-1000) [-1000|1000] "A" Vector__XXX

BO_ 608 MCU_R_260h: 8 GW
 SG_ MCU_R_FailureNum : 7|8@0+ (1,0) [0|255] "" Vector__XXX
 SG_ MCU_R_ResolverFault : 8|1@0+ (1,0) [0|1] "" IC_MMI
 SG_ MCU_R_Err_IGBT : 9|1@0+ (1,0) [0|1] "" IC_MMI
 SG_ MCU_R_CurrentOverload : 11|2@0+ (1,0) [0|3] "" IC_MMI
 SG_ MCU_R_Controllertemp_Status : 13|2@0+ (1,0) [0|3] "" IC_MMI
 SG_ MCU_R_stDischg : 15|2@0+ (1,0) [0|3] "" Vector__XXX
 SG_ MCU_R_SpeedOtLoopFalult : 18|1@0+ (1,0) [0|1] "" IC_MMI
 SG_ MCU_R_MdTepErr : 19|1@0+ (1,0) [0|1] "" IC_MMI
 SG_ MCU_R_ControllerOverVolt_Status : 21|2@0+ (1,0) [0|3] "" IC_MMI
 SG_ MCU_R_MotorTemp_Fault : 23|2@0+ (1,0) [0|3] "" IC_MMI
 SG_ MCU_R_MotorOverSpd : 25|1@0+ (1,0) [0|1] "" IC_MMI
 SG_ MCU_R_VCUCommErr : 26|1@0+ (1,0) [0|1] "" Vector__XXX
 SG_ MCU_R_ControllerLowUnderVolt_Status : 27|1@0+ (1,0) [0|1] "" IC_MMI
 SG_ MCU_R_ControllerUnderVolt_Status : 29|2@0+ (1,0) [0|3] "" IC_MMI
 SG_ MCU_R_ControllerFault : 17|3@0+ (1,0) [0|7] "" IC_MMI
 SG_ MCU_R_unload_status : 33|2@0+ (1,0) [0|3] "" Vector__XXX
 SG_ RMCU_HV_Interlock_Falult : 35|2@0+ (1,0) [0|3] "" IC_MMI
 SG_ RMCU_Uncap_Falult : 37|2@0+ (1,0) [0|3] "" IC_MMI
 SG_ MCU_R_MotTepErr : 39|1@0+ (1,0) [0|1] "" IC_MMI

BO_ 178 MCU_R_B2h: 8 GW
 SG_ MCU_R_stMode : 11|4@0+ (1,0) [0|15] "" Vector__XXX
 SG_ MCU_R_TrqCurrValid : 12|1@0+ (1,0) [0|1] "" Vector__XXX
 SG_ MCU_R_TrqCurr : 7|11@0+ (1,-1024) [-1024|1023] "Nm" Vector__XXX
 SG_ MCU_R_Ncurr : 23|16@0+ (1,-32768) [-32768|32767] "1/min" IC_MMI,AVM,BCM
 SG_ MCU_R_NCurrValid : 45|1@0+ (1,0) [0|1] "" IC_MMI,AVM,BCM
 SG_ MCU_R_UdcCurr : 39|10@0+ (1,0) [0|1021] "V" Vector__XXX
 SG_ MCU_R_B2h_RollingCounter : 51|4@0+ (1,0) [0|15] "" IC_MMI,AVM,BCM
 SG_ MCU_R_B2h_CheckSUM : 63|8@0+ (1,0) [0|15] "" IC_MMI,AVM,BCM

BO_ 772 THREE_OBC_304h: 8 GW
 SG_ OBC_out_Cur_over_prot : 0|1@0+ (1,0) [0|1] "" Vector__XXX
 SG_ OBC_out_vol_Less_prot : 1|1@0+ (1,0) [0|1] "" Vector__XXX
 SG_ OBC_out_vol_over_prot : 2|1@0+ (1,0) [0|1] "" Vector__XXX
 SG_ OBC_In_Cur_over_prot : 3|1@0+ (1,0) [0|1] "" Vector__XXX
 SG_ OBC_ChargerInputVoltageLessFault : 4|1@0+ (1,0) [0|1] "" Vector__XXX
 SG_ OBC_ChargerInputVoltageOverFault : 5|1@0+ (1,0) [0|1] "" Vector__XXX
 SG_ ChargeInterfaceOverTemp : 6|1@0+ (1,0) [0|1] "" Vector__XXX
 SG_ ChargeInterfacetemperature : 15|8@0+ (1,0) [0|255] "℃" IC_MMI
 SG_ OBC_ControllerTemp : 23|8@0+ (1,0) [0|255] "℃" IC_MMI
 SG_ OBC_ChargerOTP : 25|2@0+ (1,0) [0|3] "" Vector__XXX
 SG_ OBC_ChargerCoolingRequest : 26|1@0+ (1,0) [0|1] "" Vector__XXX
 SG_ OBC_ChargerHardwareFault : 27|1@0+ (1,0) [0|1] "" Vector__XXX
 SG_ OBC_Charger_CAN_Fault : 28|1@0+ (1,0) [0|1] "" Vector__XXX
 SG_ OBC_Charger_Fail_State : 29|1@0+ (1,0) [0|1] "" IC_MMI
 SG_ OBC_Charger_NoBatt : 31|2@0+ (1,0) [0|3] "" Vector__XXX
 SG_ OBC_CP_DutyCycleValue : 39|8@0+ (1,0) [0|100] "%" Vector__XXX
 SG_ OBC_CP_Rsv : 40|1@0+ (1,0) [0|1] "" Vector__XXX
 SG_ OBC_CC_Resistance : 43|3@0+ (1,0) [0|7] "" IC_MMI
 SG_ OBC_ChargerStatus : 46|3@0+ (1,0) [0|7] "" Vector__XXX
 SG_ KL30_UnderVolt : 49|2@0+ (1,0) [0|3] "" IC_MMI
 SG_ ElectronicLockSts : 50|1@0+ (1,0) [0|1] "" IC_MMI
 SG_ ElectronicLockFault : 52|2@0+ (1,0) [0|3] "" IC_MMI
 SG_ OBC_Charger_Instructions : 53|1@0+ (1,0) [0|1] "" IC_MMI
 SG_ OBC_Charger_Request : 54|1@0+ (1,0) [0|1] "" Vector__XXX

BO_ 770 THREE_DCDC_302h: 8 GW
 SG_ DCDC_Voltage_Input : 7|16@0+ (0.1,0) [0|500] "V" Vector__XXX
 SG_ DCDC_Voltage_Output : 23|8@0+ (0.1,0) [0|20] "A" IC_MMI
 SG_ DCDC_Current_Input : 31|10@0+ (0.1,0) [0|60] "V" Vector__XXX
 SG_ DCDC_Current_Output : 37|12@0+ (0.1,0) [0|400] "A" IC_MMI

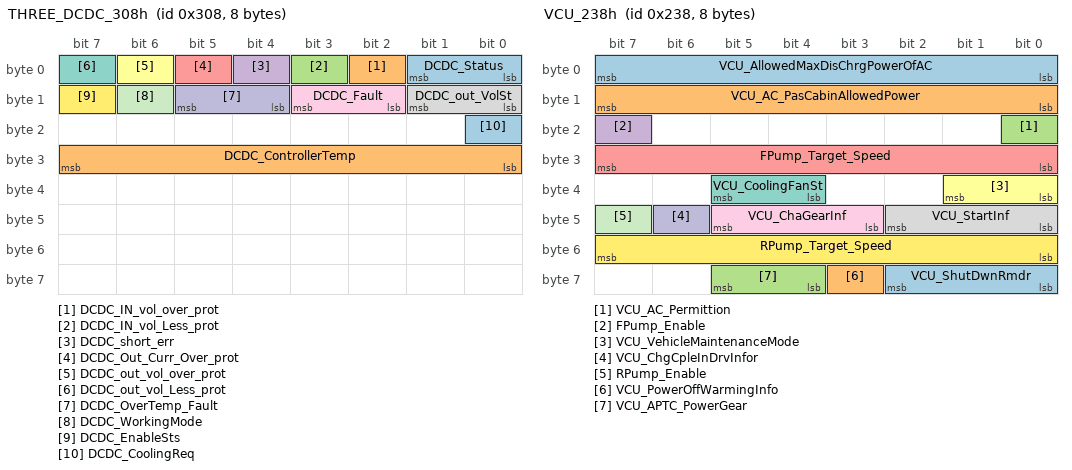
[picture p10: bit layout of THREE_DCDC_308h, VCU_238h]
BO_ 776 THREE_DCDC_308h: 8 GW
 SG_ DCDC_Status : 1|2@0+ (1,0) [0|3] "" IC_MMI
 SG_ DCDC_IN_vol_over_prot : 2|1@0+ (1,0) [0|1] "" Vector__XXX
 SG_ DCDC_IN_vol_Less_prot : 3|1@0+ (1,0) [0|1] "" Vector__XXX
 SG_ DCDC_short_err : 4|1@0+ (1,0) [0|1] "" Vector__XXX
 SG_ DCDC_Out_Curr_Over_prot : 5|1@0+ (1,0) [0|1] "" Vector__XXX
 SG_ DCDC_out_vol_over_prot : 6|1@0+ (1,0) [0|1] "" Vector__XXX
 SG_ DCDC_out_vol_Less_prot : 7|1@0+ (1,0) [0|1] "" Vector__XXX
 SG_ DCDC_out_VolSt : 9|2@0+ (1,0) [0|3] "" Vector__XXX
 SG_ DCDC_Fault : 11|2@0+ (1,0) [0|3] "" IC_MMI
 SG_ DCDC_OverTemp_Fault : 13|2@0+ (1,0) [0|3] "" IC_MMI
 SG_ DCDC_WorkingMode : 14|1@0+ (1,0) [0|1] "" Vector__XXX
 SG_ DCDC_EnableSts : 15|1@0+ (1,0) [0|1] "" Vector__XXX
 SG_ DCDC_CoolingReq : 16|1@0+ (1,0) [0|1] "" Vector__XXX
 SG_ DCDC_ControllerTemp : 31|8@0+ (1,0) [0|255] "℃" IC_MMI

BO_ 880 THREE_PDU_370h: 8 GW
 SG_ PDU_AirPTC_WorkStus : 39|2@0+ (1,0) [0|3] "" IC_MMI,AC

BO_ 372 VCU_174h: 8 GW
 SG_ VCU_Err_AccPedal : 2|1@0+ (1,0) [0|1] "" IC_MMI
 SG_ VCU_InsuldDetcCtrl : 3|1@0+ (1,0) [0|1] "" Vector__XXX
 SG_ VCU_GearPosition : 7|4@0+ (1,0) [0|15] "" IC_MMI,AVM,BCM,FSCM
 SG_ VCU_PrechrgAnodeRelay_Status : 9|2@0+ (1,0) [0|3] "" Vector__XXX
 SG_ VCU_DischrgAnodeRelay_Control : 11|1@0+ (1,0) [0|1] "" Vector__XXX
 SG_ VCU_DischrgAnodeRelay_Status : 14|2@0+ (1,0) [0|3] "" Vector__XXX
 SG_ VCU_DischrgCathodeRelay_Control : 17|1@0+ (1,0) [0|1] "" Vector__XXX
 SG_ VCU_DischrgCathodeRelay_status : 19|2@0+ (1,0) [0|3] "" Vector__XXX
 SG_ VCU_PrechrgAnodeRelay_Control : 21|1@0+ (1,0) [0|1] "" Vector__XXX
 SG_ VCU_PTSystem_Satus : 23|2@0+ (1,0) [0|3] "" IC_MMI,AVM
 SG_ VCU_VehSysStatus : 28|5@0+ (1,0) [0|31] "" IC_MMI,AC,AVM,BCM
 SG_ VCU_ChrgRelay_Control : 29|1@0+ (1,0) [0|1] "" Vector__XXX
 SG_ VCU_GearCtrlSts : 31|2@0+ (1,0) [0|1] "" Vector__XXX
 SG_ VCU_Cruise_MainSwitch : 32|1@0+ (1,0) [0|1] "" IC_MMI
 SG_ VCU_OperationMode : 34|2@0+ (1,0) [0|3] "" IC_MMI,AC
 SG_ VCU_DrivingMode : 36|2@0+ (1,0) [0|1] "" IC_MMI
 SG_ VCU_FMCU_unloadReq : 37|1@0+ (1,0) [0|1] "" Vector__XXX
 SG_ VCU_RMCU_unloadReq : 38|1@0+ (1,0) [0|1] "" Vector__XXX
 SG_ VCU_AC_unloadReq : 39|1@0+ (1,0) [0|1] "" AC
 SG_ VCU_TortoiseIndicator : 44|1@0+ (1,0) [0|1] "" IC_MMI
 SG_ VCU_ActiveDischargeOrder : 46|1@0+ (1,0) [0|1] "" Vector__XXX
 SG_ VCU_Cruise_Enable : 47|1@0+ (1,0) [0|1] "" IC_MMI
 SG_ VCU_174h_RollingCounter : 51|4@0+ (1,0) [0|15] "" IC_MMI,AC,AVM,BCM,FSCM
 SG_ VCU_UnlockSts : 54|2@0+ (1,0) [0|3] "" BCM
 SG_ VCU_StartAllow : 55|1@0+ (1,0) [0|1] "" BCM
 SG_ VCU_174h_CheckSUM : 63|8@0+ (1,0) [0|255] "" IC_MMI,AC,AVM,BCM,FSCM

BO_ 568 VCU_238h: 8 GW
 SG_ VCU_AllowedMaxDisChrgPowerOfAC : 7|8@0+ (0.1,0) [0|20] "kw" AC
 SG_ VCU_AC_PasCabinAllowedPower : 15|8@0+ (0.1,0) [0|20] "kw" AC
 SG_ VCU_AC_Permittion : 16|1@0+ (1,0) [0|1] "" AC
 SG_ FPump_Enable : 23|1@0+ (1,0) [0|1] "" Vector__XXX
 SG_ FPump_Target_Speed : 31|8@0+ (1,0) [0|100] "%" Vector__XXX
 SG_ VCU_VehicleMaintenanceMode : 33|2@0+ (1,0) [0|3] "" AC
 SG_ VCU_CoolingFanSt : 37|2@0+ (1,0) [0|3] "" IC_MMI,AC
 SG_ VCU_StartInf : 42|3@0+ (1,0) [0|7] "" IC_MMI
 SG_ VCU_ChaGearInf : 45|3@0+ (1,0) [0|7] "" IC_MMI
 SG_ VCU_ChgCpleInDrvInfor : 46|1@0+ (1,0) [0|1] "" IC_MMI
 SG_ RPump_Enable : 47|1@0+ (1,0) [0|1] "" Vector__XXX
 SG_ RPump_Target_Speed : 55|8@0+ (1,0) [0|100] "%" Vector__XXX
 SG_ VCU_ShutDwnRmdr : 58|3@0+ (1,0) [0|7] "" IC_MMI
 SG_ VCU_PowerOffWarmingInfo : 59|1@0+ (1,0) [0|1] "" IC_MMI
 SG_ VCU_APTC_PowerGear : 61|2@0+ (1,0) [0|3] "" IC_MMI

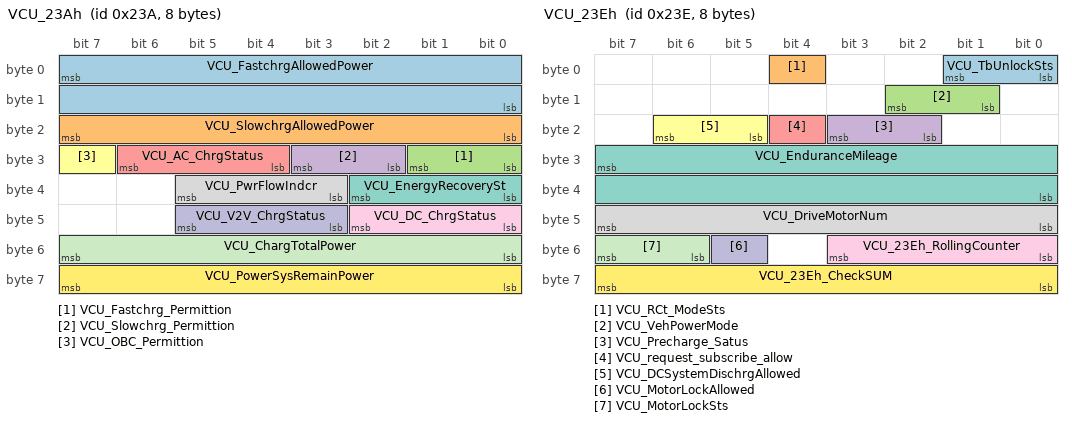
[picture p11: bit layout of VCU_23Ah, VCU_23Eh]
BO_ 570 VCU_23Ah: 8 GW
 SG_ VCU_FastchrgAllowedPower : 7|16@0+ (0.1,0) [0|100] "kw" Vector__XXX
 SG_ VCU_SlowchrgAllowedPower : 23|8@0+ (0.1,0) [0|20] "kw" Vector__XXX
 SG_ VCU_Fastchrg_Permittion : 25|2@0+ (1,0) [0|3] "" Vector__XXX
 SG_ VCU_Slowchrg_Permittion : 27|2@0+ (1,0) [0|3] "" Vector__XXX
 SG_ VCU_AC_ChrgStatus : 30|3@0+ (1,0) [0|7] "" IC_MMI
 SG_ VCU_OBC_Permittion : 31|1@0+ (1,0) [0|1] "" Vector__XXX
 SG_ VCU_EnergyRecoverySt : 34|3@0+ (1,0) [0|7] "" IC_MMI
 SG_ VCU_PwrFlowIndcr : 37|3@0+ (1,0) [0|7] "" IC_MMI
 SG_ VCU_DC_ChrgStatus : 42|3@0+ (1,0) [0|7] "" IC_MMI
 SG_ VCU_V2V_ChrgStatus : 45|3@0+ (1,0) [0|7] "" IC_MMI
 SG_ VCU_ChargTotalPower : 55|8@0+ (0.1,0) [0|20] "kw" Vector__XXX
 SG_ VCU_PowerSysRemainPower : 63|8@0+ (1,0) [0|200] "kw" IC_MMI

BO_ 574 VCU_23Eh: 8 GW
 SG_ VCU_TbUnlockSts : 1|2@0+ (1,0) [0|3] "" BCM
 SG_ VCU_RCt_ModeSts : 4|1@0+ (1,0) [0|1] "" Vector__XXX
 SG_ VCU_VehPowerMode : 10|2@0+ (1,0) [0|3] "" Vector__XXX
 SG_ VCU_Precharge_Satus : 19|2@0+ (1,0) [0|3] "" Vector__XXX
 SG_ VCU_request_subscribe_allow : 20|1@0+ (1,0) [0|1] "" Vector__XXX
 SG_ VCU_DCSystemDischrgAllowed : 22|2@0+ (1,0) [0|3] "" Vector__XXX
 SG_ VCU_EnduranceMileage : 31|16@0+ (0.1,0) [0|800] "km" IC_MMI
 SG_ VCU_DriveMotorNum : 47|8@0+ (1,0) [1|254] "" Vector__XXX
 SG_ VCU_23Eh_RollingCounter : 51|4@0+ (1,0) [0|15] "" IC_MMI
 SG_ VCU_MotorLockAllowed : 53|1@0+ (1,0) [0|1] "" Vector__XXX
 SG_ VCU_MotorLockSts : 55|2@0+ (1,0) [0|3] "" Vector__XXX
 SG_ VCU_23Eh_CheckSUM : 63|8@0+ (1,0) [0|255] "" IC_MMI

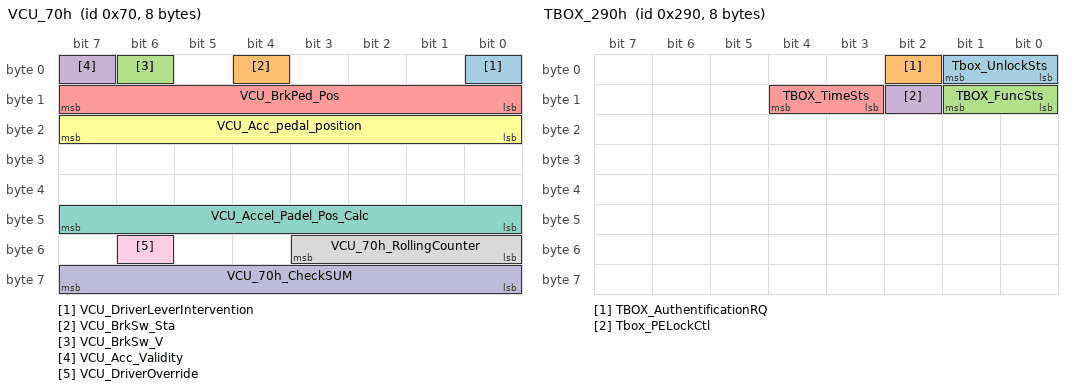
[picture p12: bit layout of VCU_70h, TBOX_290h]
BO_ 112 VCU_70h: 8 GW
 SG_ VCU_DriverLeverIntervention : 0|1@0+ (1,0) [0|1] "" Vector__XXX
 SG_ VCU_BrkSw_Sta : 4|1@0+ (1,0) [0|1] "" IC_MMI,AVM,BCM
 SG_ VCU_BrkSw_V : 6|1@0+ (1,0) [0|1] "" IC_MMI,AVM,BCM
 SG_ VCU_Acc_Validity : 7|1@0+ (1,0) [0|1] "" IC_MMI,AVM
 SG_ VCU_BrkPed_Pos : 15|8@0+ (0.5,0) [0|100] "%" Vector__XXX
 SG_ VCU_Acc_pedal_position : 23|8@0+ (0.5,0) [0|100] "%" IC_MMI,AVM
 SG_ VCU_Accel_Padel_Pos_Calc : 47|8@0+ (0.5,0) [0|100] "%" Vector__XXX
 SG_ VCU_70h_RollingCounter : 51|4@0+ (1,0) [0|15] "" IC_MMI,AVM,BCM
 SG_ VCU_DriverOverride : 54|1@0+ (1,0) [0|1] "" Vector__XXX
 SG_ VCU_70h_CheckSUM : 63|8@0+ (1,0) [0|255] "" IC_MMI

BO_ 913 VSP_391h: 8 GW
 SG_ VSP_PermanentStsFeedback : 2|2@0+ (1,0) [0|3] "" IC_MMI
 SG_ VSP_ShorterStsFeedback : 4|2@0+ (1,0) [0|3] "" IC_MMI
 SG_ VSP_StopModeStsFeedback : 7|1@0+ (1,0) [0|1] "" IC_MMI
 SG_ VSP_VoiceSourceStateFeedback : 10|3@0+ (1,0) [0|7] "" IC_MMI

BO_ 656 TBOX_290h: 8 GW
 SG_ Tbox_UnlockSts : 1|2@0+ (1,0) [0|3] "" BCM
 SG_ TBOX_AuthentificationRQ : 2|1@0+ (1,0) [0|1] "" BCM
 SG_ TBOX_FuncSts : 9|2@0+ (1,0) [0|3] "" Vector__XXX
 SG_ Tbox_PELockCtl : 10|1@0+ (1,0) [0|1] "" BCM
 SG_ TBOX_TimeSts : 12|2@0+ (1,0) [0|3] "" Vector__XXX

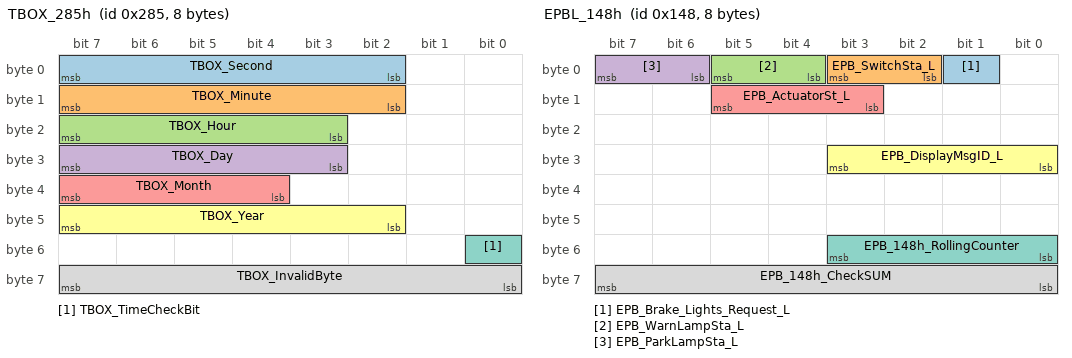
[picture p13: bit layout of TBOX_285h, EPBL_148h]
BO_ 645 TBOX_285h: 8 GW
 SG_ TBOX_Second : 7|6@0+ (1,0) [0|59] "s" IC_MMI,AC,AVM
 SG_ TBOX_Minute : 15|6@0+ (1,0) [0|59] "m" IC_MMI,AC,AVM
 SG_ TBOX_Hour : 23|5@0+ (1,0) [0|23] "h" IC_MMI,AC,AVM
 SG_ TBOX_Day : 31|5@0+ (1,0) [1|31] "d" IC_MMI,AC,AVM
 SG_ TBOX_Month : 39|4@0+ (1,0) [1|12] "m" IC_MMI,AC,AVM
 SG_ TBOX_Year : 47|6@0+ (1,2010) [2010|2072] "y" IC_MMI,AC,AVM
 SG_ TBOX_TimeCheckBit : 48|1@0+ (1,0) [0|1] "" IC_MMI,AC,AVM
 SG_ TBOX_InvalidByte : 63|8@0+ (1,0) [0|255] "" IC_MMI,AC,AVM

BO_ 662 TBOX_296h: 8 GW
 SG_ TBOX_VehiclePosition_longitude : 7|32@0+ (0.0000001,-180) [-180|180] "" IC_MMI,AC
 SG_ TBOX_VehiclePosition_latitude : 39|32@0+ (0.0000001,-90) [-90|90] "" IC_MMI,AC

BO_ 664 TBOX_298h: 8 GW
 SG_ Tbox_VehiclePosition_gradient : 7|8@0+ (1,-90) [-90|90] "" IC_MMI,AC
 SG_ Tbox_VehiclePosition_altitude : 15|16@0+ (0.1,-53.4) [-53.4|6500] "" IC_MMI,AC
 SG_ Tbox_VehiclePosition_headDirection : 31|16@0+ (1,0) [0|359] "" IC_MMI,AC
 SG_ Tbox_MMI_GPS_Country_Code : 47|8@0+ (1,0) [0|255] "" Vector__XXX
 SG_ Tbox_MMI_FICM_Available : 55|1@0+ (1,0) [0|1] "" Vector__XXX

BO_ 148 EHB_94h: 8 GW
 SG_ EHB_FaultSt : 7|3@0+ (1,0) [0|7] "" IC_MMI

BO_ 328 EPBL_148h: 8 GW
 SG_ EPB_Brake_Lights_Request_L : 1|1@0+ (1,0) [0|1] "" IC_MMI
 SG_ EPB_SwitchSta_L : 3|2@0+ (1,0) [0|3] "" IC_MMI
 SG_ EPB_WarnLampSta_L : 5|2@0+ (1,0) [0|3] "" IC_MMI
 SG_ EPB_ParkLampSta_L : 7|2@0+ (1,0) [0|3] "" IC_MMI
 SG_ EPB_ActuatorSt_L : 13|3@0+ (1,0) [0|7] "" IC_MMI
 SG_ EPB_DisplayMsgID_L : 27|4@0+ (1,0) [0|15] "" IC_MMI
 SG_ EPB_148h_RollingCounter : 51|4@0+ (1,0) [0|15] "" IC_MMI
 SG_ EPB_148h_CheckSUM : 63|8@0+ (1,0) [0|255] "" IC_MMI

BO_ 336 EPBR_150h: 8 GW
 SG_ EPB_Brake_Lights_Request_R : 1|1@0+ (1,0) [0|1] "" IC_MMI
 SG_ EPB_SwitchSta_R : 3|2@0+ (1,0) [0|3] "" IC_MMI
 SG_ EPB_WarnLampSta_R : 5|2@0+ (1,0) [0|3] "" IC_MMI
 SG_ EPB_ParkLampSta_R : 7|2@0+ (1,0) [0|3] "" IC_MMI
 SG_ EPB_ActuatorSt_R : 13|3@0+ (1,0) [0|7] "" IC_MMI
 SG_ EPB_DisplayMsgID_R : 27|4@0+ (1,0) [0|15] "" IC_MMI
 SG_ EPB_150h_RollingCounter : 51|4@0+ (1,0) [0|15] "" IC_MMI
 SG_ EPB_150h_CheckSUM : 63|8@0+ (1,0) [0|255] "" IC_MMI
 SG_ ESC_VehSpd : 7|16@0+ (0.05625,0) [0|299.98125] "km/h" IC_MMI
 SG_ ESC_92h_RollingCounter : 51|4@0+ (1,0) [0|15] "" IC_MMI
 SG_ ESC_VehSpdVd : 55|1@0+ (1,0) [0|1] "" IC_MMI
 SG_ ESC_92h_CheckSUM : 63|8@0+ (1,0) [0|255] "" IC_MMI

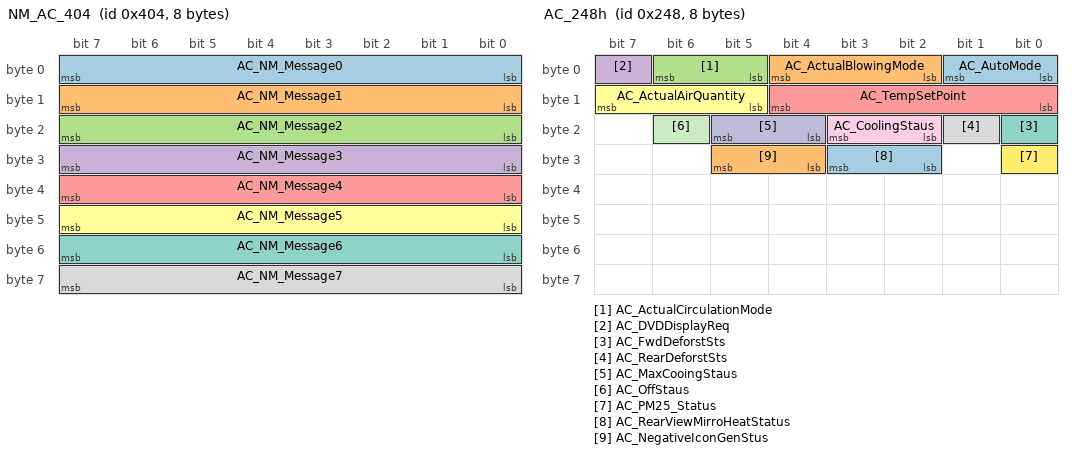
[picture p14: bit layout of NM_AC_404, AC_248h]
BO_ 1028 NM_AC_404: 8 AC
 SG_ AC_NM_Message0 : 7|8@0+ (1,0) [0|255] "" IC_MMI,GW,BCM
 SG_ AC_NM_Message1 : 15|8@0+ (1,0) [0|255] "" IC_MMI,GW,BCM
 SG_ AC_NM_Message2 : 23|8@0+ (1,0) [0|255] "" IC_MMI,GW,BCM
 SG_ AC_NM_Message3 : 31|8@0+ (1,0) [0|255] "" IC_MMI,GW,BCM
 SG_ AC_NM_Message4 : 39|8@0+ (1,0) [0|255] "" IC_MMI,GW,BCM
 SG_ AC_NM_Message5 : 47|8@0+ (1,0) [0|255] "" IC_MMI,GW,BCM
 SG_ AC_NM_Message6 : 55|8@0+ (1,0) [0|255] "" IC_MMI,GW,BCM
 SG_ AC_NM_Message7 : 63|8@0+ (1,0) [0|255] "" IC_MMI,GW,BCM

BO_ 584 AC_248h: 8 AC
 SG_ AC_AutoMode : 1|2@0+ (1,0) [0|3] "" IC_MMI,GW
 SG_ AC_ActualBlowingMode : 4|3@0+ (1,0) [0|7] "" IC_MMI,GW
 SG_ AC_ActualCirculationMode : 6|2@0+ (1,0) [0|3] "" IC_MMI,GW
 SG_ AC_DVDDisplayReq : 7|1@0+ (1,0) [0|1] "" IC_MMI,GW
 SG_ AC_TempSetPoint : 12|5@0+ (0.5,18) [18|32] "℃" IC_MMI,GW
 SG_ AC_ActualAirQuantity : 15|3@0+ (1,0) [0|7] "" IC_MMI,GW
 SG_ AC_FwdDeforstSts : 16|1@0+ (1,0) [0|1] "" IC_MMI,GW
 SG_ AC_RearDeforstSts : 17|1@0+ (1,0) [0|1] "" IC_MMI,GW
 SG_ AC_CoolingStaus : 19|2@0+ (1,0) [0|3] "" IC_MMI,GW
 SG_ AC_MaxCooingStaus : 21|2@0+ (1,0) [0|3] "" IC_MMI,GW
 SG_ AC_OffStaus : 22|1@0+ (1,0) [0|1] "" IC_MMI,GW
 SG_ AC_PM25_Status : 24|1@0+ (1,0) [0|1] "" IC_MMI,GW
 SG_ AC_RearViewMirroHeatStatus : 27|2@0+ (1,0) [0|3] "" IC_MMI,GW
 SG_ AC_NegativeIconGenStus : 29|2@0+ (1,0) [0|3] "" IC_MMI,GW

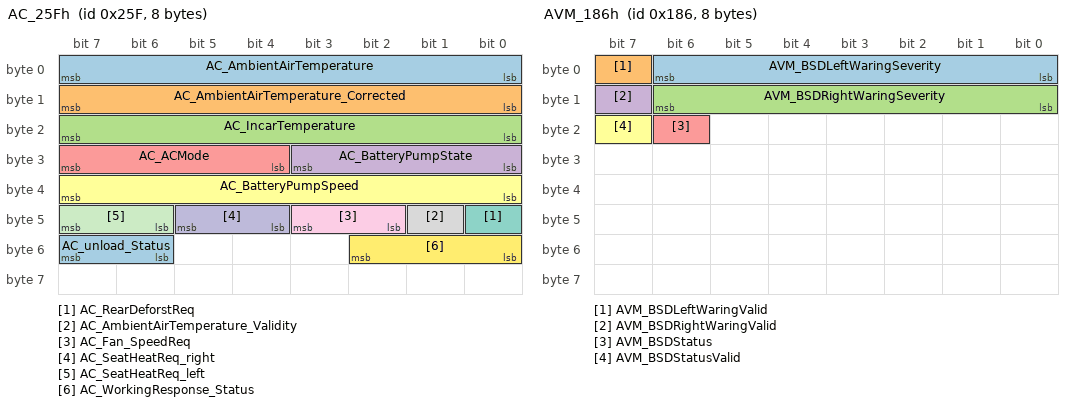
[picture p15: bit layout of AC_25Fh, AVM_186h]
BO_ 607 AC_25Fh: 8 AC
 SG_ AC_AmbientAirTemperature : 7|8@0+ (0.5,-40) [-40|87.5] "℃" GW,PSR
 SG_ AC_AmbientAirTemperature_Corrected : 15|8@0+ (0.5,-40) [-40|87.5] "℃" IC_MMI,GW,AVM
 SG_ AC_IncarTemperature : 23|8@0+ (0.5,-40) [-40|87.5] "℃" IC_MMI,GW
 SG_ AC_BatteryPumpState : 27|4@0+ (1,0) [0|15] "" GW
 SG_ AC_ACMode : 31|4@0+ (1,0) [0|15] "" IC_MMI,GW
 SG_ AC_BatteryPumpSpeed : 39|8@0+ (1,0) [0|100] "%" GW
 SG_ AC_RearDeforstReq : 40|1@0+ (1,0) [0|1] "" GW,BCM
 SG_ AC_AmbientAirTemperature_Validity : 41|1@0+ (1,0) [0|1] "" IC_MMI,GW,AVM
 SG_ AC_Fan_SpeedReq : 43|2@0+ (1,0) [0|3] "" GW
 SG_ AC_SeatHeatReq_right : 45|2@0+ (1,0) [0|3] "" GW
 SG_ AC_SeatHeatReq_left : 47|2@0+ (1,0) [0|3] "" GW
 SG_ AC_WorkingResponse_Status : 50|3@0+ (1,0) [0|7] "" GW
 SG_ AC_unload_Status : 55|2@0+ (1,0) [0|3] "" GW

BO_ 390 AVM_186h: 8 AVM
 SG_ AVM_BSDLeftWaringSeverity : 6|7@0+ (1,0) [0|126] "" IC_MMI
 SG_ AVM_BSDLeftWaringValid : 7|1@0+ (1,0) [0|1] "" IC_MMI
 SG_ AVM_BSDRightWaringSeverity : 14|7@0+ (1,0) [0|126] "" IC_MMI
 SG_ AVM_BSDRightWaringValid : 15|1@0+ (1,0) [0|1] "" IC_MMI
 SG_ AVM_BSDStatus : 22|1@0+ (1,0) [0|1] "" IC_MMI
 SG_ AVM_BSDStatusValid : 23|1@0+ (1,0) [0|1] "" IC_MMI

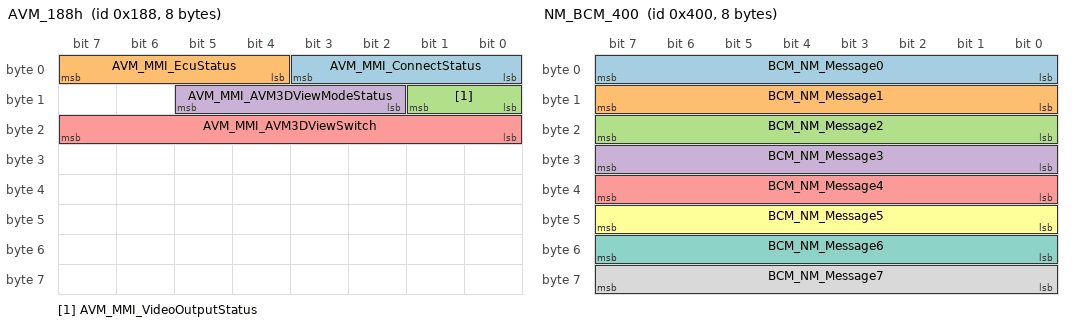
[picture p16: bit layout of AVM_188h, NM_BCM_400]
BO_ 392 AVM_188h: 8 AVM
 SG_ AVM_MMI_ConnectStatus : 3|4@0+ (1,0) [0|7] "" IC_MMI
 SG_ AVM_MMI_EcuStatus : 7|4@0+ (1,0) [0|3] "" IC_MMI
 SG_ AVM_MMI_VideoOutputStatus : 9|2@0+ (1,0) [0|3] "" IC_MMI
 SG_ AVM_MMI_AVM3DViewModeStatus : 13|4@0+ (1,0) [0|15] "" IC_MMI
 SG_ AVM_MMI_AVM3DViewSwitch : 23|8@0+ (1,0) [0|255] "" IC_MMI

BO_ 788 AVM_314h: 8 AVM
 SG_ AVM_MCU_Version : 15|24@0+ (1,0) [0|16777214] "" IC_MMI
 SG_ AVM_BSP_Version : 39|24@0+ (1,0) [0|16777214] "" IC_MMI

BO_ 790 AVM_316h: 8 AVM
 SG_ AVM_ZADAS_Version : 15|24@0+ (1,0) [0|16777214] "" IC_MMI
 SG_ Avm3d_licenseStatus : 33|2@0+ (1,0) [0|3] "" IC_MMI
 SG_ BSD_licenseStatus : 35|2@0+ (1,0) [0|3] "" IC_MMI

BO_ 1024 NM_BCM_400: 8 BCM
 SG_ BCM_NM_Message0 : 7|8@0+ (1,0) [0|255] "" IC_MMI,GW,AC
 SG_ BCM_NM_Message1 : 15|8@0+ (1,0) [0|255] "" IC_MMI,GW,AC
 SG_ BCM_NM_Message2 : 23|8@0+ (1,0) [0|255] "" IC_MMI,GW,AC
 SG_ BCM_NM_Message3 : 31|8@0+ (1,0) [0|255] "" IC_MMI,GW,AC
 SG_ BCM_NM_Message4 : 39|8@0+ (1,0) [0|255] "" IC_MMI,GW,AC
 SG_ BCM_NM_Message5 : 47|8@0+ (1,0) [0|255] "" IC_MMI,GW,AC
 SG_ BCM_NM_Message6 : 55|8@0+ (1,0) [0|255] "" IC_MMI,GW,AC
 SG_ BCM_NM_Message7 : 63|8@0+ (1,0) [0|255] "" IC_MMI,GW,AC

BO_ 338 BCM_152h: 8 BCM
 SG_ BCM_RFDoorSwitchSt : 0|1@0+ (1,0) [0|1] "" IC_MMI,GW,AVM,CWC
 SG_ BCM_LFDoorSwitchSt : 1|1@0+ (1,0) [0|1] "" IC_MMI,GW,AVM,DSM_D,DSM_P,CWC
 SG_ BCM_PositionLampSt : 2|1@0+ (1,0) [0|1] "" IC_MMI,GW
 SG_ BCM_FrontFogligthSt : 3|1@0+ (1,0) [0|1] "" IC_MMI,GW
 SG_ BCM_BackFogligthSt : 4|1@0+ (1,0) [0|1] "" IC_MMI,GW
 SG_ BCM_HighBeamStatus : 5|1@0+ (1,0) [0|1] "" IC_MMI,GW
 SG_ BCM_LowBeamStatus : 6|1@0+ (1,0) [0|1] "" IC_MMI,GW
 SG_ BCM_TrunkSt : 7|1@0+ (1,0) [0|1] "" IC_MMI,GW,AVM
 SG_ BCM_TurnLeverLoc : 9|2@0+ (1,0) [0|3] "" IC_MMI,GW,AVM
 SG_ BCM_RightligthFaultSt : 10|1@0+ (1,0) [0|1] "" IC_MMI,GW,AVM
 SG_ BCM_RightligthSt : 11|1@0+ (1,0) [0|1] "" IC_MMI,GW,AVM
 SG_ BCM_LetfligthFaultSt : 12|1@0+ (1,0) [0|1] "" IC_MMI,GW,AVM
 SG_ BCM_LetfligthSt : 13|1@0+ (1,0) [0|1] "" IC_MMI,GW,AVM
 SG_ BCM_LRDoorSwitchSt : 14|1@0+ (1,0) [0|1] "" IC_MMI,GW,AVM
 SG_ BCM_RRDoorSwitchSt : 15|1@0+ (1,0) [0|1] "" IC_MMI,GW,AVM
 SG_ BCM_CentralLockSt : 16|1@0+ (1,0) [0|1] "" IC_MMI,GW
 SG_ BCM_Reverse_Light : 17|1@0+ (1,0) [0|1] "" IC_MMI,GW
 SG_ Bcm_OutSwitchPressCmd : 19|1@0+ (1,0) [0|1] "" GW
 SG_ BCM_HazardwarnLampSt : 20|1@0+ (1,0) [0|1] "" IC_MMI,GW,AVM
 SG_ BCM_PassSeatbeltBucklestatus : 21|1@0+ (1,0) [0|1] "" IC_MMI,GW,AVM
 SG_ BCM_DrvSeatbeltBucklestatus : 22|1@0+ (1,0) [0|1] "" IC_MMI,GW,AVM
 SG_ BCM_FrontCoverSt : 23|1@0+ (1,0) [0|1] "" IC_MMI,GW,AVM
 SG_ BCM_WiperMaintainFuncCtrStus : 25|2@0+ (1,0) [0|3] "" IC_MMI,GW
 SG_ BCM_HornStus : 26|1@0+ (1,0) [0|1] "" IC_MMI,GW
 SG_ BCM_PositionLampOpenWarm : 27|1@0+ (1,0) [0|1] "" IC_MMI,GW
 SG_ BCM_Auto_LightSwitch : 32|1@0+ (1,0) [0|1] "" IC_MMI,GW
 SG_ BCM_Brake_Light : 33|1@0+ (1,0) [0|1] "" IC_MMI,GW
 SG_ BCM_RearViewMirrorAutoFoldFucFeedback : 35|2@0+ (1,0) [0|3] "" IC_MMI,GW
 SG_ BCM_Rain_Sensor : 37|2@0+ (1,0) [0|3] "" IC_MMI,GW,AC
 SG_ BCM_DrvSeatbeltBucklevalidity : 38|1@0+ (1,0) [0|1] "" IC_MMI,GW,AVM
 SG_ BCM_PassSeatbeltBucklevalidity : 39|1@0+ (1,0) [0|1] "" IC_MMI,GW,AVM
 SG_ BCM_PowerMode : 42|3@0+ (1,0) [0|3] "" IC_MMI,GW,DSM_D,DSM_P,FSCM,CWC
 SG_ BCM_RearViewMirror : 45|2@0+ (1,0) [0|3] "" IC_MMI,GW
 SG_ BCM_ChargeCoverLockStatus : 46|1@0+ (1,0) [0|1] "" IC_MMI,GW
 SG_ BCM_RearDeforstSts : 47|1@0+ (1,0) [0|1] "" IC_MMI,GW,AC
 SG_ BCM_BkSeat_1_beltBucklevalidity : 48|1@0+ (1,0) [0|1] "" IC_MMI,GW
 SG_ BCM_BkSeat_1_beltBucklestatus : 49|1@0+ (1,0) [0|1] "" IC_MMI,GW
 SG_ BCM_BkSeat_2_beltBucklevalidity : 50|1@0+ (1,0) [0|1] "" IC_MMI,GW
 SG_ BCM_BkSeat_2_beltBucklestatus : 51|1@0+ (1,0) [0|1] "" IC_MMI,GW
 SG_ BCM_BkSeat_3_beltBucklevalidity : 52|1@0+ (1,0) [0|1] "" IC_MMI,GW
 SG_ BCM_BkSeat_3_beltBucklestatus : 53|1@0+ (1,0) [0|1] "" IC_MMI,GW
 SG_ BCM_RainAutoClsWindowFuncStus : 55|2@0+ (1,0) [0|3] "" IC_MMI
 SG_ BCM_LockVehicleWarmingTipStus : 57|2@0+ (1,0) [0|3] "" IC_MMI
 SG_ BCM_CourtesyLampStus : 58|1@0+ (1,0) [0|1] "" IC_MMI
 SG_ BCM_VehicleCourtesyLampFuncStus : 61|2@0+ (1,0) [0|3] "" IC_MMI
 SG_ BCM_AccLampSetStus : 63|2@0+ (1,0) [0|3] "" IC_MMI

BO_ 588 BCM_24Ch: 8 BCM
 SG_ PEPS_KeyInCarWarning : 0|1@0+ (1,0) [0|1] "" IC_MMI,GW
 SG_ ReminderPutInP_Nposition_OFF : 1|1@0+ (1,0) [0|1] "" IC_MMI,GW
 SG_ ReminderPutInP_Nposition_Lock : 2|1@0+ (1,0) [0|1] "" IC_MMI,GW
 SG_ PEPS_KeyNotInWarning : 3|1@0+ (1,0) [0|1] "" IC_MMI,GW
 SG_ BCM_FrontWiperSt : 5|2@0+ (1,0) [0|3] "" IC_MMI,GW
 SG_ PEPS_PutKeyInIMMOSocket : 8|1@0+ (1,0) [0|1] "" IC_MMI,GW
 SG_ PEPS_PowerRelayFault : 9|1@0+ (1,0) [0|1] "" IC_MMI,GW
 SG_ PEPS_RemoteLowVoltage : 14|1@0+ (1,0) [0|1] "" IC_MMI,GW
 SG_ WashStatus : 16|1@0+ (1,0) [0|1] "" Vector__XXX
 SG_ WipeReset : 17|1@0+ (1,0) [0|1] "" Vector__XXX
 SG_ PEPS_ESCLFault : 19|1@0+ (1,0) [0|1] "" Vector__XXX
 SG_ PEPS_ESCLUnlockFailed : 20|1@0+ (1,0) [0|1] "" Vector__XXX
 SG_ BCM_SenyClass : 23|3@0+ (1,0) [0|7] "" Vector__XXX
 SG_ FLWS_POS_VIT_FL : 30|7@0+ (1,0) [0|100] "%" IC_MMI,GW
 SG_ FRWS_POS_VIT_FL : 38|7@0+ (1,0) [0|100] "%" IC_MMI,GW
 SG_ RLWS_POS_VIT_FL : 46|7@0+ (1,0) [0|100] "%" IC_MMI,GW
 SG_ RRWS_POS_VIT_FL : 54|7@0+ (1,0) [0|100] "%" IC_MMI,GW
 SG_ BCM_OpenDoorWarning : 57|1@0+ (1,0) [0|1] "" IC_MMI,GW

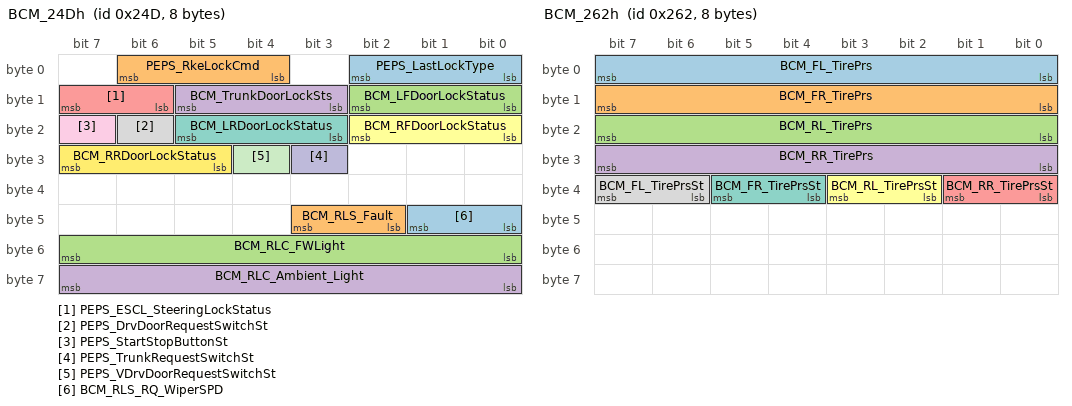
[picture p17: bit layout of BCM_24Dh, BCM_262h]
BO_ 589 BCM_24Dh: 8 BCM
 SG_ PEPS_LastLockType : 2|3@0+ (1,0) [0|7] "" IC_MMI,GW
 SG_ PEPS_RkeLockCmd : 6|3@0+ (1,0) [0|7] "" CWC
 SG_ BCM_LFDoorLockStatus : 10|3@0+ (1,0) [0|7] "" IC_MMI,GW
 SG_ BCM_TrunkDoorLockSts : 13|3@0+ (1,0) [0|7] "" IC_MMI,GW
 SG_ PEPS_ESCL_SteeringLockStatus : 15|2@0+ (1,0) [0|3] "" GW
 SG_ BCM_RFDoorLockStatus : 18|3@0+ (1,0) [0|7] "" IC_MMI,GW
 SG_ BCM_LRDoorLockStatus : 21|3@0+ (1,0) [0|7] "" IC_MMI,GW
 SG_ PEPS_DrvDoorRequestSwitchSt : 22|1@0+ (1,0) [0|1] "" GW
 SG_ PEPS_StartStopButtonSt : 23|1@0+ (1,0) [0|1] "" GW
 SG_ PEPS_TrunkRequestSwitchSt : 27|1@0+ (1,0) [0|1] "" GW
 SG_ PEPS_VDrvDoorRequestSwitchSt : 28|1@0+ (1,0) [0|1] "" GW
 SG_ BCM_RRDoorLockStatus : 31|3@0+ (1,0) [0|7] "" IC_MMI,GW
 SG_ BCM_RLS_RQ_WiperSPD : 41|2@0+ (1,0) [0|3] "" IC_MMI,GW
 SG_ BCM_RLS_Fault : 43|2@0+ (1,0) [0|3] "" IC_MMI,GW,AC
 SG_ BCM_RLC_FWLight : 55|8@0+ (1,0) [0|255] "" IC_MMI,AC
 SG_ BCM_RLC_Ambient_Light : 63|8@0+ (1,0) [0|255] "" IC_MMI

BO_ 610 BCM_262h: 8 BCM
 SG_ BCM_FL_TirePrs : 7|8@0+ (1.373,0) [0|348.742] "Kpa" IC_MMI,GW
 SG_ BCM_FR_TirePrs : 15|8@0+ (1.373,0) [0|348.742] "Kpa" IC_MMI,GW
 SG_ BCM_RL_TirePrs : 23|8@0+ (1.373,0) [0|348.742] "Kpa" IC_MMI,GW
 SG_ BCM_RR_TirePrs : 31|8@0+ (1.373,0) [0|348.742] "Kpa" IC_MMI,GW
 SG_ BCM_RR_TirePrsSt : 33|2@0+ (1,0) [0|3] "" IC_MMI,GW,AVM
 SG_ BCM_RL_TirePrsSt : 35|2@0+ (1,0) [0|3] "" IC_MMI,GW,AVM
 SG_ BCM_FR_TirePrsSt : 37|2@0+ (1,0) [0|3] "" IC_MMI,GW,AVM
 SG_ BCM_FL_TirePrsSt : 39|2@0+ (1,0) [0|3] "" IC_MMI,GW,AVM

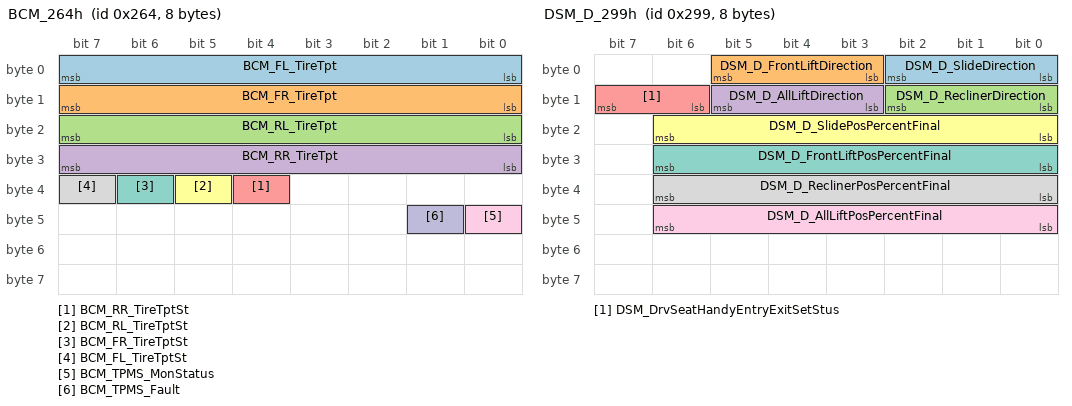
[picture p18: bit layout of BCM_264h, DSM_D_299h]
BO_ 612 BCM_264h: 8 BCM
 SG_ BCM_FL_TireTpt : 7|8@0+ (1,-50) [-50|204] "" IC_MMI,GW
 SG_ BCM_FR_TireTpt : 15|8@0+ (1,-50) [-50|204] "" IC_MMI,GW
 SG_ BCM_RL_TireTpt : 23|8@0+ (1,-50) [-50|204] "" IC_MMI,GW
 SG_ BCM_RR_TireTpt : 31|8@0+ (1,-50) [-50|204] "" IC_MMI,GW
 SG_ BCM_RR_TireTptSt : 36|1@0+ (1,0) [0|1] "" IC_MMI,GW
 SG_ BCM_RL_TireTptSt : 37|1@0+ (1,0) [0|1] "" IC_MMI,GW
 SG_ BCM_FR_TireTptSt : 38|1@0+ (1,0) [0|1] "" IC_MMI,GW
 SG_ BCM_FL_TireTptSt : 39|1@0+ (1,0) [0|1] "" IC_MMI,GW
 SG_ BCM_TPMS_MonStatus : 40|1@0+ (1,0) [0|1] "" IC_MMI,GW
 SG_ BCM_TPMS_Fault : 41|1@0+ (1,0) [0|1] "" IC_MMI,GW

BO_ 613 BCM_265h: 8 BCM
 SG_ BCM_RR_TireLose : 0|1@0+ (1,0) [0|1] "" IC_MMI,GW
 SG_ BCM_RL_TireLose : 1|1@0+ (1,0) [0|1] "" IC_MMI,GW
 SG_ BCM_FR_TireLose : 2|1@0+ (1,0) [0|1] "" IC_MMI,GW
 SG_ BCM_FL_TireLose : 3|1@0+ (1,0) [0|1] "" IC_MMI,GW
 SG_ BCM_RR_TireLowVol : 4|1@0+ (1,0) [0|1] "" IC_MMI,GW
 SG_ BCM_RL_TireLowVol : 5|1@0+ (1,0) [0|1] "" IC_MMI,GW
 SG_ BCM_FR_TireLowVol : 6|1@0+ (1,0) [0|1] "" IC_MMI,GW
 SG_ BCM_FL_TireLowVol : 7|1@0+ (1,0) [0|1] "" IC_MMI,GW
 SG_ BCM_RR_TestSt : 9|1@0+ (1,0) [0|1] "" IC_MMI,GW,AVM
 SG_ BCM_RL_TestSt : 10|1@0+ (1,0) [0|1] "" IC_MMI,GW,AVM
 SG_ BCM_FR_TestSt : 11|1@0+ (1,0) [0|1] "" IC_MMI,GW,AVM
 SG_ BCM_FL_TestSt : 12|1@0+ (1,0) [0|1] "" IC_MMI,GW,AVM
 SG_ BCM_BatVol_ErrFlag : 13|1@0+ (1,0) [0|1] "" IC_MMI,GW
 SG_ BCM_TPMS_TestSt : 15|2@0+ (1,0) [0|3] "" IC_MMI,GW,AVM
 SG_ BCM_RR_Quikleakage : 20|1@0+ (1,0) [0|1] "" IC_MMI,GW,AVM
 SG_ BCM_RL_Quikleakage : 21|1@0+ (1,0) [0|1] "" IC_MMI,GW,AVM
 SG_ BCM_FR_Quikleakage : 22|1@0+ (1,0) [0|1] "" IC_MMI,GW,AVM
 SG_ BCM_FL_Quikleakage : 23|1@0+ (1,0) [0|1] "" IC_MMI,GW,AVM

BO_ 665 DSM_D_299h: 8 DSM_D
 SG_ DSM_D_SlideDirection : 2|3@0+ (1,0) [0|3] "" IC_MMI
 SG_ DSM_D_FrontLiftDirection : 5|3@0+ (1,0) [0|3] "" IC_MMI
 SG_ DSM_D_ReclinerDirection : 10|3@0+ (1,0) [0|3] "" IC_MMI
 SG_ DSM_D_AllLiftDirection : 13|3@0+ (1,0) [0|3] "" IC_MMI
 SG_ DSM_DrvSeatHandyEntryExitSetStus : 15|2@0+ (1,0) [0|3] "" IC_MMI
 SG_ DSM_D_SlidePosPercentFinal : 22|7@0+ (1,0) [0|100] "%" IC_MMI
 SG_ DSM_D_FrontLiftPosPercentFinal : 30|7@0+ (1,0) [0|100] "%" IC_MMI
 SG_ DSM_D_ReclinerPosPercentFinal : 38|7@0+ (1,0) [0|100] "%" IC_MMI
 SG_ DSM_D_AllLiftPosPercentFinal : 46|7@0+ (1,0) [0|100] "%" IC_MMI

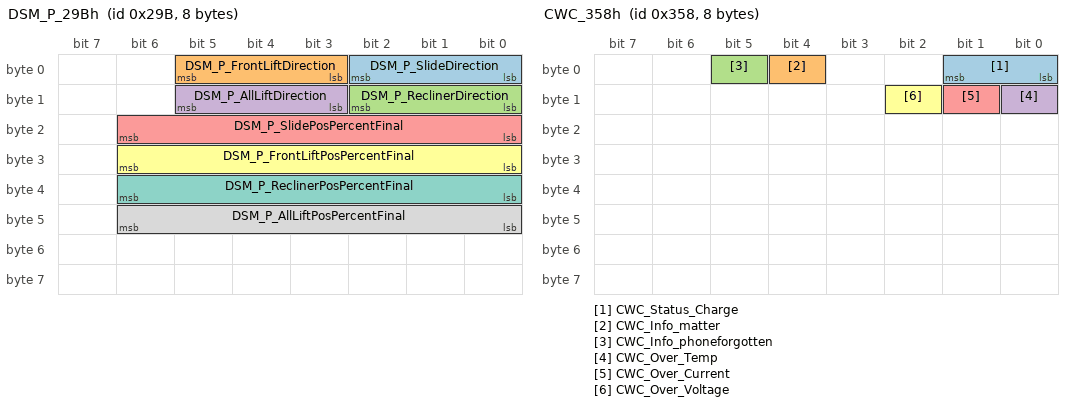
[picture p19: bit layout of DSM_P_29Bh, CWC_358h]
BO_ 667 DSM_P_29Bh: 8 DSM_P
 SG_ DSM_P_SlideDirection : 2|3@0+ (1,0) [0|3] "" IC_MMI
 SG_ DSM_P_FrontLiftDirection : 5|3@0+ (1,0) [0|3] "" IC_MMI
 SG_ DSM_P_ReclinerDirection : 10|3@0+ (1,0) [0|3] "" IC_MMI
 SG_ DSM_P_AllLiftDirection : 13|3@0+ (1,0) [0|3] "" IC_MMI
 SG_ DSM_P_SlidePosPercentFinal : 22|7@0+ (1,0) [0|100] "%" IC_MMI
 SG_ DSM_P_FrontLiftPosPercentFinal : 30|7@0+ (1,0) [0|100] "%" IC_MMI
 SG_ DSM_P_ReclinerPosPercentFinal : 38|7@0+ (1,0) [0|100] "%" IC_MMI
 SG_ DSM_P_AllLiftPosPercentFinal : 46|7@0+ (1,0) [0|100] "%" IC_MMI

BO_ 659 FSCM_293h: 8 FSCM
 SG_ FSCM_DrvSeatHeat_Sts : 2|3@0+ (1,0) [0|7] "" IC_MMI,GW
 SG_ FSCM_DrvSeatVentilation_Sts : 6|3@0+ (1,0) [0|7] "" IC_MMI,GW
 SG_ FSCM_PassSeatHeat_Sts : 10|3@0+ (1,0) [0|7] "" IC_MMI,GW
 SG_ FSCM_PassSeatVentilation_Sts : 14|3@0+ (1,0) [0|7] "" IC_MMI,GW

BO_ 853 PSR_355h: 8 PSR
 SG_ PSR_FaultStatus : 2|1@0+ (1,0) [0|1] "" IC_MMI
 SG_ PSR_PlatfondPellucidityStus : 14|7@0+ (1,0) [0|100] "%" IC_MMI

BO_ 856 CWC_358h: 8 CWC
 SG_ CWC_Status_Charge : 1|2@0+ (1,0) [0|3] "" IC_MMI
 SG_ CWC_Info_matter : 4|1@0+ (1,0) [0|1] "" IC_MMI
 SG_ CWC_Info_phoneforgotten : 5|1@0+ (1,0) [0|1] "" IC_MMI
 SG_ CWC_Over_Temp : 8|1@0+ (1,0) [0|1] "" IC_MMI
 SG_ CWC_Over_Current : 9|1@0+ (1,0) [0|1] "" IC_MMI
 SG_ CWC_Over_Voltage : 10|1@0+ (1,0) [0|1] "" IC_MMI

CM_ SG_ 342 SteerWheel_L_OK "左确认键";
CM_ SG_ 342 SteerWheel_Voice "语音";
CM_ SG_ 342 SteerWheel_VOL_Inc "音量+";
CM_ SG_ 342 SteerWheel_VOL_Dec "音量-/静音";
CM_ SG_ 342 SteerWheel_PREV "上一曲/上一页";
CM_ SG_ 342 SteerWheel_Defi "自定义开关";
CM_ SG_ 342 SteerWheel_NEXT "下一曲/下一页";
CM_ SG_ 342 SteerWheel_Mode "MODE开关(MENU)";
CM_ SG_ 342 SteerWheel_Return_Home "返回/主页开关";
CM_ SG_ 342 SteerWheel_Hang_Down "接/挂电话";
CM_ SG_ 342 AmphereLampMode "氛围灯呼吸模式";
CM_ SG_ 342 AmphereLampSta_Drivingmode "氛围灯驾驶模式";
CM_ SG_ 342 AmphereLampSta_SW "氛围灯开关状态";
CM_ SG_ 342 AmphereLampSta_Colour "氛围灯颜色状态";
CM_ SG_ 342 AmphereLampBrtnsVal "氛围灯亮度值（0-100%）";
CM_ SG_ 586 ACU_AirBagSysWrnLmpCmd "Airbag system warning lamp request";
CM_ SG_ 586 ACU_Crashinfo "crash signal
无碰撞时100ms 有碰撞时20ms连续发10次";
CM_ SG_ 586 ACU_24Ah_RollingCounter "循环计数器";
CM_ SG_ 586 ACU_24Ah_CheckSUM "校检和 checksum = (Byte0+Byte1 …+ Byte6) XOR 0xFF";
CM_ SG_ 352 ACC_Set_Speed "driver selected cruise speed
驾驶员选择的巡航速度";
CM_ SG_ 352 ACC_DecToStop "decelerate to stop
减速停车";
CM_ SG_ 352 ACC_Set_Headway "driver selected follow headway
驾驶员选择的跟车距离";
CM_ SG_ 352 ACC_Accelerate_Request "acelarate request value
ACC请求加速度信号值";
CM_ SG_ 352 ADAS_TJAorHWATouchWarning "TJAorHWATouchWarning
TJAorHWA过程中脱手警报";
CM_ SG_ 352 ADAS_TJA_HWAFuncStatus "ADAS_TJA_HWAFuncStatus";
CM_ SG_ 352 TJAHWA_Auto_Cancel "indicate auto cancel 
指示系统自动取消了TJAHWA功能";
CM_ SG_ 352 ALC_Auto_Cancel "indicate auto cancel 
指示系统自动取消了ALC功能";
CM_ SG_ 352 ADAS_160h_RollingCounter "循环计数器";
CM_ SG_ 352 ADAS_160h_CheckSUM "校检和 checksum = (Byte0+Byte1 …+ Byte6) XOR 0xFF";
CM_ SG_ 354 AEB_ABA_Level "Hydaulic Brake Assist Level
液压制动辅助级别";
CM_ SG_ 354 AEB_ABA_Req "Hydaulic Brake Assist Request
制动辅助请求";
CM_ SG_ 354 AEB_Prefill_Request "prefill request
AEB制动预充请求";
CM_ SG_ 354 AEB_AWB_Req "Warning Brake Request
警告制动请求";
CM_ SG_ 354 AEB_State "indicate system working state
指示AEB系统状态";
CM_ SG_ 354 AEB_DecCtlReq "Emergency Brake Decelerate Control Request
减速控制请求";
CM_ SG_ 354 FCW_State "indicate system working state
指示FCW工作状态";
CM_ SG_ 354 AEB_Decelerate_Request "decelerate request value
AEB请求的减速值";
CM_ SG_ 354 ACC_MinBraking "Minimum Brake Request
轻微制动请求";
CM_ SG_ 354 ADAS_Sensorstatus "Sensor Fault Status
传感器故障状态";
CM_ SG_ 354 HW_Warning_Level "indicate the current warning level
指示HW当前报警等级";
CM_ SG_ 354 FCW_Warning_Level "indicate the current warning level
指示FCW报警等级";
CM_ SG_ 354 ACC_CIPV_Indicator "indicate CIPV detection status
指示最近在径前车状态";
CM_ SG_ 354 ACC_Auto_Cancel "indicate auto cancel 
指示系统自动取消了ACC功能";
CM_ SG_ 354 ACC_Driver_Cancel "indicate driver cancel operation
指示驾驶员取消ACC";
CM_ SG_ 354 ACC_ModeReq "Adaptive Cruise Control Operation Mode Request
自适应巡航工作模式请求";
CM_ SG_ 354 AEB_AWB_Level "Warning Brake Level
警告制动级别";
CM_ SG_ 354 ACC_ShutDownMode "Shut Down Mode
退出模式";
CM_ SG_ 354 ACC_DriveOff "Vehicle Diver Off
车辆起步";
CM_ SG_ 354 ACC_BrkPreferred "Brake Preferred
制动优先";
CM_ SG_ 354 ACC_Go_Indicator "GO' notifier for stop & go function
 stop & go功能的前进指示";
CM_ SG_ 354 ACC_Takeover_Indicator "indicate driver takeover operation
请求驾驶员接管";
CM_ SG_ 354 ADAS_162h_RollingCounter "循环计数器";
CM_ SG_ 354 ADAS_162h_CheckSUM "校检和 checksum = (Byte0+Byte1 …+ Byte6) XOR 0xFF";
CM_ SG_ 356 TSR_State "indicate system working state
指示TSR系统工作状态";
CM_ SG_ 356 DAS_TSR_Main_Switch "Trafic Signal Recognise switch feedback status                  
 交通信号灯识别开关回馈状态";
CM_ SG_ 356 IHC_Mainbeam_Request "turn on or shut down high beam request
请求打开或关闭远光灯";
CM_ SG_ 356 IHC_State "indicate system working state
指示IHC工作状态";
CM_ SG_ 356 LDW_Line_Detect_Status "indicate system lane mark detection status
指示车道线检测状态";
CM_ SG_ 356 LDW_Warning "indicate the current warning direction
指示当前LDW报警等级";
CM_ SG_ 356 LDW_State "indicate system working state
指示LDW工作状态";
CM_ SG_ 356 TSR_Targetspeed_Request "Indicates the current identified speed limit
指示当前识别到的限速值";
CM_ SG_ 356 LKA_Takeover_Request "warning when system detect current situation beyond system limit
LKA请求驾驶员接管";
CM_ SG_ 356 LKA_Torque_Request_Status "indicate if there is a steering wheel torque request
指示是否有转向扭矩请求";
CM_ SG_ 356 LCK_State "indicate system working state
指示LCK系统状态";
CM_ SG_ 356 LKA_Torque_Request "steering wheel torque request value
LKA系统请求的转向扭矩值";
CM_ SG_ 356 ADAS_164h_RollingCounter "循环计数器";
CM_ SG_ 356 LKA_State "indicate system working state
指示LKA系统状态";
CM_ SG_ 356 LKA_Hands_Off_Warning "warning when hands off detected
驾驶员手离开方向盘警告";
CM_ SG_ 356 DAS_LDW_Main_Switch "Lan Departure Warming switch feedback status                                                                 道路偏离预警开关回馈状态";
CM_ SG_ 356 DAS_LDW_Sensitivity "Lan Departure Warming Sensitivity feedback status                                                             道路偏离预警灵敏度回馈状态";
CM_ SG_ 356 DAS_FCW_Main_Switch "Forward Collision switch feedback status                   前碰预警开关回馈状态";
CM_ SG_ 356 DAS_FCW_Sensitivity "Forward Collision sensitivity feedback status                                                                   前碰预警开关灵敏度回馈状态";
CM_ SG_ 356 DAS_AEB_Main_Switch "Auto Emergency Break switch feedback status                                                                            自动紧急制动主开关回馈状态";
CM_ SG_ 356 DAS_IHC_Main_Switch "Intergrade HeadLingt Control Main switch feedback status                                                                      自动大灯开关回馈状态";
CM_ SG_ 356 ADAS_164h_CheckSUM "校检和 checksum = (Byte0+Byte1 …+ Byte6) XOR 0xFF";
CM_ BO_ 1281 "ADAS_Object1_2 目标1、2位置、类型";
CM_ SG_ 1281 ADAS_RelativeLogitudinalDistToObject1 "Relative Distance To Object1
与目标1的纵向距离";
CM_ SG_ 1281 ADAS_RelativeLateralDistToObject1 "Relative Distance To Object1
与目标1的侧向距离";
CM_ SG_ 1281 ADAS_Object1Type "Object1 Type
目标1类型";
CM_ SG_ 1281 ADAS_RelativeLogitudinalDistToObject2 "Relative Distance To Object2
与目标2的纵向距离";
CM_ SG_ 1281 ADAS_RelativeLateralDistToObject2 "Relative Distance To Object2
与目标2的侧向距离";
CM_ SG_ 1281 ADAS_Object2Type "Object2 Type
目标2类型";
CM_ SG_ 1281 ADAS_Object1_2_RollingCounter "RollingCounter
消息计数器";
CM_ SG_ 1281 ADAS_Object1_2_Checksum "Checksum
消息校验和";
CM_ BO_ 1282 "ADAS_Object3_4 目标3、4位置、类型";
CM_ SG_ 1282 ADAS_RelativeLogitudinalDistToObject3 "Relative Distance To Object3
与目标3的纵向距离";
CM_ SG_ 1282 ADAS_RelativeLateralDistToObject3 "Relative Distance To Object3
与目标3的侧向距离";
CM_ SG_ 1282 ADAS_Object3Type "Object3 Type
目标3类型";
CM_ SG_ 1282 ADAS_RelativeLogitudinalDistToObject4 "Relative Distance To Object4
与目标4的纵向距离";
CM_ SG_ 1282 ADAS_RelativeLateralDistToObject4 "Relative Distance To Object4
与目标4的侧向距离";
CM_ SG_ 1282 ADAS_Object4Type "Object4 Type
目标4类型";
CM_ SG_ 1282 ADAS_Object3_4_RollingCounter "RollingCounter
消息计数器";
CM_ SG_ 1282 ADAS_Object3_4_Checksum "Checksum
消息校验和";
CM_ BO_ 1283 "ADAS_Object5_6 目标5、6位置、类型";
CM_ SG_ 1283 ADAS_RelativeLogitudinalDistToObject5 "Relative Distance To Object5
与目标5的纵向距离";
CM_ SG_ 1283 ADAS_RelativeLateralDistToObject5 "Relative Distance To Object5
与目标5的侧向距离";
CM_ SG_ 1283 ADAS_Object5Type "Object5 Type
目标5类型";
CM_ SG_ 1283 ADAS_RelativeLogitudinalDistToObject6 "Relative Distance To Object6
与目标6的纵向距离";
CM_ SG_ 1283 ADAS_RelativeLateralDistToObject6 "Relative Distance To Object6
与目标6的侧向距离";
CM_ SG_ 1283 ADAS_Object6Type "Object6Type
目标6类型";
CM_ SG_ 1283 ADAS_Object5_6_RollingCounter "Rolling Counter
消息计数器";
CM_ SG_ 1283 ADAS_Object5_6_Checksum "Checksum
消息校验和";
CM_ BO_ 1284 "ADAS_LeftLaneEquation 左侧车道线位置";
CM_ SG_ 1284 ADAS_LeftLane_C3 "Cubic Term of Left Lane Equation
摄像头识别的左侧车道线方程的三次项";
CM_ SG_ 1284 ADAS_LeftLane_C2 "Quadratic Term of Left Lane Equation
摄像头识别的左侧车道线方程的二次项";
CM_ SG_ 1284 ADAS_LeftLane_C1 "LnRGDP of Left Lane Equation
摄像头识别的左侧车道线方程的一次项";
CM_ SG_ 1284 ADAS_LeftLane_C0 "Zeroth Term of Left Lane Equation
摄像头识别的左侧车道线方程的常数项";
CM_ BO_ 1285 "ADAS_LeftLeftLaneEquation 左左侧车道线位置";
CM_ SG_ 1285 ADAS_LeftLeftLane_C3 "Cubic Term of Left Left Lane Equation
摄像头识别的左左侧车道线方程的三次项";
CM_ SG_ 1285 ADAS_LeftLeftLane_C2 "Quadratic Term of Left Left Lane Equation
摄像头识别的左左侧车道线方程的二次项";
CM_ SG_ 1285 ADAS_LeftLeftLane_C1 "LnRGDP of Left Left Lane Equation
摄像头识别的左左侧车道线方程的一次项";
CM_ SG_ 1285 ADAS_LeftLeftLane_C0 "Zeroth Term of Left Left Lane Equation
摄像头识别的左左侧车道线方程的常数项";
CM_ BO_ 1286 "ADAS_RightLaneEquation 右侧车道线位置";
CM_ SG_ 1286 ADAS_RightLane_C3 "Cubic Term of Right Lane Equation
摄像头识别的右侧车道线方程的三次项";
CM_ SG_ 1286 ADAS_RightLane_C2 "Quadratic Term of Right Lane Equation
摄像头识别的右侧车道线方程的二次项";
CM_ SG_ 1286 ADAS_RightLane_C1 "LnRGDP of Right Lane Equation
摄像头识别的右侧车道线方程的一次项";
CM_ SG_ 1286 ADAS_RightLane_C0 "Zeroth Term of Right Lane Equation
摄像头识别的右侧车道线方程的常数项";
CM_ BO_ 1287 "ADAS_RightRightLaneEquation 右右侧车道线位置";
CM_ SG_ 1287 ADAS_RightRightLane_C3 "Cubic Term of Right Right Lane Equation
摄像头识别的右右侧车道线方程的三次项";
CM_ SG_ 1287 ADAS_RightRightLane_C2 "Quadratic Term of Right Right Lane Equation
摄像头识别的右右侧车道线方程的二次项";
CM_ SG_ 1287 ADAS_RightRightLane_C1 "LnRGDP of Right Right Lane Equation
摄像头识别的右右侧车道线方程的一次项";
CM_ SG_ 1287 ADAS_RightRightLane_C0 "Zeroth Term of Right Right Lane Equation
摄像头识别的右右侧车道线方程的常数项";
CM_ BO_ 1288 "ADAS_LaneColorandType 车道线颜色、类型；ALC状态；";
CM_ SG_ 1288 ADAS_LeftLaneColor "Left Lane Color
摄像头识别的左侧车道线颜色";
CM_ SG_ 1288 ADAS_LeftLaneType "Left Lane Type
摄像头识别的左侧车道线类型";
CM_ SG_ 1288 ADAS_LeftLeftLaneType "Left Left Lane Type
摄像头识别的左左侧车道线类型";
CM_ SG_ 1288 ADAS_RightLaneColor "Right Lane Color
摄像头识别的右侧车道线颜色";
CM_ SG_ 1288 ADAS_RightLaneType "Right Lane Type
摄像头识别的右侧车道线类型";
CM_ SG_ 1288 ADAS_RightRightLaneType "Right Right Lane Type
摄像头识别的右右侧车道线类型";
CM_ SG_ 1288 ADAS_RightRightLaneColor "Right Right Lane Color
摄像头识别的右右侧车道线颜色";
CM_ SG_ 1288 ADAS_LeftLeftLaneColor "Left Left Lane Color
摄像头识别的左左侧车道线颜色";
CM_ SG_ 1288 ADAS_ALCStatusup "ALCStatusup
ALC状态";
CM_ SG_ 1288 ADAS_ALCAvailable "ALC Avilable
ALC功能可用性";
CM_ BO_ 384 "APA与MMI交互信号1";
CM_ SG_ 384 APA_MMI_ConnectStatus "APA connect status
APA与MMI连接状态";
CM_ SG_ 384 APA_MMI_EcuStatus "Signal from APA to indicate ECU status 
APA ECU状态";
CM_ SG_ 384 APA_MMI_VideoOutputStatus "APA Ecu Video output status
APA Ecu视频输出状态";
CM_ SG_ 384 APA_MMI_3DViewModeStatus "APA 3D View Mode Status";
CM_ SG_ 384 APA_MMI_AVM3DViewSwitch "APA3D视角状态";
CM_ SG_ 384 APA_Status "APA状态";
CM_ SG_ 384 PAS_APA_Mode "APA Sensor Working Mode
泊车雷达的工作模式";
CM_ SG_ 384 PSA_APA_SensorStsLR_RL "左后长距离雷达传感器状态";
CM_ SG_ 384 PSA_APA_SensorStsLR_RR "右后长距离雷达传感器状态";
CM_ SG_ 384 PSA_APA_SensorStsSR_RL "左后短距离雷达传感器状态";
CM_ SG_ 384 PSA_APA_SensorStsSR_RML "左中后短距离雷达传感器状态";
CM_ SG_ 384 PAS_APA_SensorStsSR_RMR "右中后短距离雷达传感器状态";
CM_ SG_ 384 PAS_APA_SensorStsSR_RR "右后短距离雷达传感器状态";
CM_ SG_ 384 PSA_APA_SensorStsLR_FL "左前长距离雷达传感器状态";
CM_ SG_ 384 PSA_APA_SensorStsLR_FR "右前长距离雷达传感器状态";
CM_ SG_ 384 PSA_APA_SensorStsSR_FL "左前短距离雷达传感器状态";
CM_ SG_ 384 PSA_APA_SensorStsSR_FML "左中前短距离雷达传感器状态";
CM_ SG_ 384 PAS_APA_SensorStsSR_FMR "右中前短距离雷达传感器状态";
CM_ SG_ 384 PAS_APA_SensorStsSR_FR "右前短距离雷达传感器状态";
CM_ BO_ 386 "APA与MMI交互信号2(预留)";
CM_ SG_ 386 APA_BSDLeftWaringSeverity "BSD左侧报警严重度(预留)";
CM_ SG_ 386 APA_BSDLeftWaringValid "BSD左侧报警有效(预留)";
CM_ SG_ 386 APA_BSDRightWaringSeverity "BSD右侧报警严重度(预留)";
CM_ SG_ 386 APA_BSDRightWaringValid "BSD右侧报警有效(预留)";
CM_ SG_ 386 APA_BSDStatus "BSD状态(预留)";
CM_ SG_ 386 APA_BSDStatusValid "BSD状态位是否有效(预留)";
CM_ BO_ 387 "APA后泊车雷达信号 APA与MMI交互信号3";
CM_ SG_ 387 PAS_APA_DistanceLR_RL "obstancle detection Distance by rear left radar(long distance)
左后长距离雷达探测障碍物距离值";
CM_ SG_ 387 PAS_APA_DistanceLR_RR "obstancle detection Distance by rear right radar(long distance)
右后长距离雷达探测障碍物距离值";
CM_ SG_ 387 PAS_APA_DistanceSR_RL "obstancle detection Distance by rear left radar(short distance)
左后短距离雷达探测障碍物距离值";
CM_ SG_ 387 PAS_APA_DistanceSR_RML "obstancle detection Distance by rear middle left radar(short distance)
左中后短距离雷达探测障碍物距离值";
CM_ SG_ 387 PAS_APA_DistanceSR_RMR "obstancle detection Distance by rear middle right radar(short distance)
右中后短距离雷达探测障碍物距离值";
CM_ SG_ 387 PAS_APA_DistanceSR_RR "obstancle detection Distance by rear right radar(short distance)
右后短距离雷达探测障碍物距离值";
CM_ SG_ 387 APA_183hh_MessageCounter "counter
计数器";
CM_ SG_ 387 APA_183hh_MessageChecksum "校检和 checksum = (Byte0+Byte1 …+ Byte6) XOR 0xFF";
CM_ BO_ 388 "APA前泊车雷达信号 APA与MMI交互信号4";
CM_ SG_ 388 PAS_APA_DistanceLR_FL "obstancle detection Distance by front left radar(long distance)
左前长距离雷达探测障碍物距离值";
CM_ SG_ 388 PAS_APA_DistanceLR_FR "obstancle detection Distance by front right radar(long distance)
右前长距离雷达探测障碍物距离值";
CM_ SG_ 388 PAS_APA_DistanceSR_FL "obstancle detection Distance by front left radar(short distance)
左前短距离雷达探测障碍物距离值";
CM_ SG_ 388 PAS_APA_DistanceSR_FML "obstancle detection Distance by front middle left radar(short distance)
左中前短距离雷达探测障碍物距离值";
CM_ SG_ 388 PAS_APA_DistanceSR_FMR "obstancle detection Distance by front middle right radar(short distance)
右中前短距离雷达探测障碍物距离值";
CM_ SG_ 388 PAS_APA_DistanceSR_FR "obstancle detection Distance by front right radar(short distance)
右前短距离雷达探测障碍物距离值";
CM_ SG_ 388 APA_184hh_MessageCounter "counter
计数器";
CM_ SG_ 388 APA_184hh_MessageChecksum "校检和 checksum = (Byte0+Byte1 …+ Byte6) XOR 0xFF";
CM_ BO_ 784 "APA与MMI交互信号3";
CM_ SG_ 784 APA_AVM_MCU_Version "Signal from AVM to indicate MCU version
标识MCU版本 eg.0x030008: 3.0.8";
CM_ SG_ 784 APA_AVM_BSP_Version "Signal from AVM to indicate BSP version
标识BSP版本 eg.0x030008: 3.0.8";
CM_ BO_ 786 "APA与MMI交互信号4";
CM_ SG_ 786 APA_AVM_ZADAS_Version "Signal from AVM to indicate Zadas version
标识ZADAS版本 eg.0x030008: 3.0.8";
CM_ SG_ 786 APA_Avm3d_licenseStatus "Signal from AVM to indicate if contained avm3d license
是否包含AVM 3D授权";
CM_ SG_ 786 APA_BSD_licenseStatus "Signal from AVM to indicate if contained BSD license
是否包含BSD授权";
CM_ SG_ 512 BMS_Sys_SumVoltage "Total battery voltage
电池总电压";
CM_ SG_ 512 BMS_Sys_SumCurrent "Total Battery Current
电池总电流";
CM_ SG_ 512 BMS_battery_outside_Voltage "Battery pack External Total pressure
That is, the busbar voltage
电池包外部总压
即母线电压";
CM_ SG_ 514 BMS_Err_DischrgAnodeRelay "Main relay (discharge main connection) fault information
主接触器（放电主接）故障信息";
CM_ SG_ 514 BMS_DischargeAnodeRelay_status "Main relay State (discharge main connection)
主接触器状态（放电主接）";
CM_ SG_ 514 BMS_Boot_Detection "Boot detection
开机检测";
CM_ SG_ 514 BMS_A "A+ singnal
A+信号";
CM_ SG_ 514 BMS_Relay_HEAT "Relay Status-Heating
继电器状态-加热（预留）";
CM_ SG_ 514 BMS_Err_PrechargeAnodeRelay "Pre-charging relay fault information
预充接触器故障信息";
CM_ SG_ 514 BMS_Precharge_anode_Relay_status "Pre-recharge CONTACTOR status
预充接触器状态";
CM_ SG_ 514 BMS_ChrgHeatColEnable "Charging&Heat&cooling enable
充电、加热及冷却使能";
CM_ SG_ 514 BMS_Sys_ChgorDisChrgSts "Battery pack charging and discharging status
电池包充放电状态";
CM_ SG_ 514 BMS_FastChrgSts "BMS FastCharge Status
BMS快充充电状态";
CM_ SG_ 514 BMS_SlowChrgSts "BMS SlowCharge Status
BMS慢充充电状态";
CM_ SG_ 514 BMS_ChrgCouplesSt "Fast charge connection status
快充连接状态";
CM_ SG_ 514 BMS_req_ConnectChargeRelay "Request Connect Charge Relay
请求吸和充电继电器";
CM_ SG_ 514 BMS_request_subscribe_allow "Reservation charging allowed
预约充电允许";
CM_ SG_ 514 BMS_CC2 "CC2
直充连接信号";
CM_ SG_ 514 BMS_PauseContinueChrgStus "Pause/Continue charge status feedback
请求暂停/继续充电状态反馈";
CM_ SG_ 514 BMS_AllowedChrgMaxPower "Max Allowed Charge Power
最大允许充电电量";
CM_ SG_ 518 BMS_battery_WaterTemp_in "the temperature of inlet water
电池包进水口冷却液温度";
CM_ SG_ 518 BMS_battery_WaterTemp_out "the temperature of inlet water
电池包出水口冷却液温度";
CM_ SG_ 518 BMS_FlowRateReq "flow rate request to AC
电池热管理对流量的需求";
CM_ SG_ 518 BMS_InletWaterTempTarget "The Target temperature request
电池对冷却回路进水口目标温度请求";
CM_ SG_ 518 BMS_ThermalManageReq "BMS request AC to cooling or heating
热管理请求";
CM_ SG_ 524 BMS_Powertrain_System_fault "Battery system failure
电池系统故障";
CM_ SG_ 524 BMS_cell_Voltage_low "Battery monomer power down fault
电池单体电压低故障";
CM_ SG_ 524 BMS_cell_Voltage_High "High voltage fault of battery monomer
电池单体电压高故障";
CM_ SG_ 524 BMS_Battery_LowTemp_warning "Battery pack Temperature Low fault
电池组温度低故障";
CM_ SG_ 524 BMS_Battery_HighTemp_warning "Battery pack Temperature High fault
电池组温度高故障";
CM_ SG_ 524 BMS_SOCHigh_Warning "Soc High Alarm
SOC高报警";
CM_ SG_ 524 BMS_SOCLow_Warning "Soc Low Alarm
SOC低报警";
CM_ SG_ 524 BMS_Battery_SumVoltage_High "High total voltage of battery pack failure
电池包总电压高故障";
CM_ SG_ 524 BMS_Battery_SumVoltage_Low "Battery pack total power down fault
电池包总电压低故障";
CM_ SG_ 524 BMS_HVBatCellDiffFalt "Battery Monomer Consistency Difference failure
电池单体一致性差故障";
CM_ SG_ 524 BMS_SOCJump_Warning "Soc Jump Alarm
SOC跳变报警";
CM_ SG_ 524 BMS_BatNotMatchFlt "Battery mismatch Alarm
电池不匹配报警";
CM_ SG_ 524 BMS_Err_ISO_LOW "Insulation Low fault
绝缘低故障";
CM_ SG_ 524 BMS_Err_ChgCurrent_High "Charging current is too large fault
充电电流过大故障";
CM_ SG_ 524 BMS_Err_DchCurrent_High "Too large discharge current failure
放电电流过大故障";
CM_ SG_ 524 BMS_Err_DtT_High "The temperature difference is too big fault
温差过大故障";
CM_ SG_ 524 ThermalManage_System_fault "Thermal manage system fault
热管理系统故障";
CM_ SG_ 524 BMS_Err_comunicacion "BMS Communication failure
BMS通讯故障";
CM_ SG_ 524 BMS_Err_InterLock "BMS Interlock fault
BMS互锁故障";
CM_ SG_ 524 BMS_Circuit_Protection "Short Circuit protection
短路保护";
CM_ SG_ 524 BMS_FeedFault "BMS feed fault
蓄电池馈电故障";
CM_ SG_ 524 BMS_TotalErrNumber "Total number of BMS faults
BMS故障总个数";
CM_ SG_ 528 BMS_Sys_MinCellV "Minimum monomer voltage
最小单体电压";
CM_ SG_ 528 BMS_Sys_MaxCellV "Maximum electrical voltage
最大电体电压";
CM_ SG_ 528 BMS_Sys_MinCellV_No "Minimum monomer voltage position
最小单体电压位置";
CM_ SG_ 528 BMS_Sys_MaxCellV_No "Maximum electrical voltage position
最大电体电压位置";
CM_ SG_ 530 BMS_Sys_MinCellT "Minimum temperature
最小温度";
CM_ SG_ 530 BMS_Sys_MaxCellT "Maximum temperature
最大温度";
CM_ SG_ 530 BMS_Sys_MinCellT_No "Minimum temperature range
最小温度位置";
CM_ SG_ 530 BMS_Sys_MaxCellT_No "Maximum temperature position
最大温度位置";
CM_ SG_ 530 BMS_FastChrgTemp "Fast Charging gun surface temperature
快充电枪表面温度";
CM_ SG_ 534 BMS_PosInsulationResistance "Cathode Insulation Resistance value
正极绝缘电阻值";
CM_ SG_ 534 BMS_NegInsulationResistance "Cathode Insulation Resistance value
负极绝缘电阻值";
CM_ SG_ 534 BMS_Sys_SOC "State Of Charge
电池SOC";
CM_ SG_ 534 BMS_Sys_SOH "State Of Health
电池SOH";
CM_ SG_ 340 RCTA_warm_status_left "后方交叉路口左侧车辆报警";
CM_ SG_ 340 BSDLCA_warm_status_left "左侧有车警告";
CM_ SG_ 340 BSD_ConnectionFault_left "左雷达异常报警";
CM_ SG_ 340 BSD_RFICFault_left "左雷达RFIC异常报警";
CM_ SG_ 340 BSD_OverTempFault_left "左雷达温度异常报警";
CM_ SG_ 340 BSD_StoreFault_left "左雷达存储异常报警";
CM_ SG_ 340 BSDDOW_warm_status_left "DOW左侧有车警告";
CM_ SG_ 340 BSD_EnableStatus "开关机状态反馈";
CM_ SG_ 344 RCTA_warm_status_right "后方交叉路口右侧车辆报警";
CM_ SG_ 344 BSDLCA_warm_status_right "右侧有车警告";
CM_ SG_ 344 BSD_ConnectionFault_right "右雷达异常报警";
CM_ SG_ 344 BSD_RFICFault_right "右雷达RFIC异常报警";
CM_ SG_ 344 BSD_OverTempFault_right "右雷达温度异常报警";
CM_ SG_ 344 BSD_StoreFault_right "右雷达存储异常报警";
CM_ SG_ 344 BSDDOW_warm_status_right "DOW右侧有车警告";
CM_ BO_ 332 "EHB、EPB功能相关";
CM_ SG_ 332 WCBS_FaultStus "WCBS Fault status
WCBS失败状态";
CM_ SG_ 332 WCBS_EPB_SystemStatus "EPB System Status
EPB系统状态";
CM_ SG_ 332 WCBS_EPB_SwitchSstatus "EPB Switch Status
EPB开关状态";
CM_ SG_ 332 WCBS_CC_Cancel_Request "WCBS Cancel CC Request
WCBS退出巡航请求";
CM_ SG_ 332 WCBS_TMM_Open_Request "EPB Cancel  4-Drive Mode Request
EPB退出四驱模式请求";
CM_ SG_ 332 WCBS_EPB_WarnLampStatus "EPB Fault Lamp Status
EPB故障灯状态";
CM_ SG_ 332 WCBS_EPB_ParkLampStatus "EPB Parking Lamp Status
EPB驻车灯状态";
CM_ SG_ 332 WCBS_Brake_Lights_Request "WCBS Break Light Request
WCBS点亮制动尾灯请求";
CM_ SG_ 332 WCBS_EPB_DynamicApplyStatus "EPB Dynamic Break Status
EPB动态制动状态";
CM_ SG_ 332 WCBS_EPB_Disp_ReleaseWithoutBrake "手动释放未踩刹车仪表提示信号";
CM_ SG_ 332 WCBS_EPB_Disp_DAAWithoutDoorOrBelt "自动释放未系安全带或未关闭主驾车门仪表提示信号";
CM_ SG_ 332 WCBS_14Ch_RollingCounter "Rolling counter
循环计数器";
CM_ SG_ 332 WCBS_14Ch_CheckSUM "校验和
checksum = (Byte0+Byte1 …+ Byte6) XOR 0xFF";
CM_ SG_ 274 EPS_SteeringWheelAngVD "EPS steering wheel angle Valid Status
EPS中测量的方向盘转角信号有效性标识位";
CM_ SG_ 274 EPS_SASFailureSts "EPS SAS Failure Status
EPS中的转角传感器失效状态";
CM_ SG_ 274 EPS_TorsionBarTorqueValid "Validation bit of measured torsion bar torque.
转向杆扭矩有效位";
CM_ SG_ 274 EPS_TorsionBarTorqueDir "Direction of measured torsion bar torque
转向杆扭矩方向（左正右负）";
CM_ SG_ 274 EPS_Fault "Fault Lamp Status
故障灯状态";
CM_ SG_ 274 EPS_TorsionBarTorque "Measired torsion bar torque （Driver hand torque）
转向杆扭矩（驾驶员手力矩）";
CM_ SG_ 274 EPS_SteeringWheelAng "EPS steering wheel angle
EPS中测量的方向盘转角(左正右负)";
CM_ SG_ 274 EPS_SteerWheelRotSpd "EPS Steering wheel rotational speed
EPS中测量的方向盘转角速度";
CM_ SG_ 274 EPS_State_Mode "indicates mode
反映当前转向模式";
CM_ SG_ 274 EPS_Modesetting_Available "indicates if EPS is available
反映EPS模式设置是否可用";
CM_ SG_ 274 EPS_SteerWheelRotSpdVD "EPS Steering wheel rotational speed Valid Status
EPS中测量的方向盘转角速度有效性标识位";
CM_ SG_ 274 EPS_112h_RollingCounter "Rolling counter
循环计数器";
CM_ SG_ 274 EPS_112h_CheckSUM "校验和
checksum = (Byte0+Byte1 …+ Byte6) XOR 0xFF";
CM_ BO_ 144 "WCBS状态相关";
CM_ SG_ 144 WCBS_ESC_TCSActive "TCS work or not 
TCS是否工作";
CM_ SG_ 144 WCBS_ESC_HHC_Failure "HHC normal or not
HHC是否正常运行";
CM_ SG_ 144 WCBS_ESC_HHCActive "HHC work or not 
HHC是否工作";
CM_ SG_ 144 WCBS_ESC_EBDFailed "EBD normal or not
EBD是否正常运行";
CM_ SG_ 144 WCBS_ESC_EBDActive "EBD work or not
EBD是否工作";
CM_ SG_ 144 WCBS_ESC_ABSFailed "ABS normal or not
是否正常运行";
CM_ SG_ 144 WCBS_ESC_ABSActive "ABS work or not
ABS是否工作";
CM_ SG_ 144 WCBS_ESC_AVH_Status "Indicates AVH status
自动驻车状态";
CM_ SG_ 144 WCBS_ESC_CST_Active "CST Active Flag
CST激活标志";
CM_ SG_ 144 WCBS_ESC_Sw "ESC OFF switch
ESC OFF开关";
CM_ SG_ 144 WCBS_ESC_HBAActive "HBA work or not 
HBA是否工作";
CM_ SG_ 144 WCBS_ESC_VDCFailure "VDC normal or not
VDC是否正常运行";
CM_ SG_ 144 WCBS_ESC_VDCActive "VDC work or not 
VDC是否工作";
CM_ SG_ 144 WCBS_ESC_TCSFailure "TCS normal or not
TCS是否正常运行";
CM_ SG_ 144 WCBS_ESC_NoBrakeForce "Vehicle No Brake Force
无制动力标志位";
CM_ SG_ 144 WCBS_ESC_VehicleStandStill "Vehicle Stand Still
车辆静止标志位";
CM_ SG_ 144 WCBS_ESC_BrkPrs "Brake pressure
刹车压力";
CM_ SG_ 144 WCBS_ESC_ABP_Available "Brake Prefilled(ABP) Avaliable
预充压功能可用";
CM_ SG_ 144 WCBS_ESC_APB_Active "Brake Prefilled(ABP) Active
预充压激活";
CM_ SG_ 144 WCBS_ESC_AEB_Available "AEB Decelerate Brake Avaliable
AEB减速制动功能可用";
CM_ SG_ 144 WCBS_ESC_AEB_Active "AEB Decelerate Brake Active
AEB减速制动激活";
CM_ SG_ 144 WCBS_ESC_AWB_Available "Warnning Brake(AWB) Avaliable
警告制动功能可用";
CM_ SG_ 144 WCBS_ESC_AWB_Active "Warnning Brake(AWB) Active
警告制动激活";
CM_ SG_ 144 WCBS_ESC_Brake_Light_Control "Request Lighting Brake Lamp
请求点亮制动灯";
CM_ SG_ 144 WCBS_ESC_BrkPrsVd "Brake pressure active
刹车压力有效";
CM_ SG_ 144 WCBS_ESC_AVH_Warning1 "warming: Please close driver door ,then press AVH switch 
提醒：请关好驾驶员侧车门，再按下AVH开关";
CM_ SG_ 144 WCBS_ESC_AVH_Warning2 "warming: Please tie driver seat belt buckle,then press AVH switch 
提醒：请系好驾驶员安全带，再按下AVH开关";
CM_ SG_ 144 WCBS_ESC_AVH_Warning3 "warming: Please Ready ,then press AVH switch 
提醒：请车辆Ready，再按下AVH开关";
CM_ SG_ 144 WCBS_ESC_HazLightReq "Hazard Light Request
危险警告灯请求";
CM_ SG_ 144 WCBS_ESC_HDC_CtlSts "HDC Working Status
HDC工作状态";
CM_ SG_ 144 WCBS_ESC_HDC_Available "HDC Function Available
HDC功能可用";
CM_ SG_ 144 WCBS_90h_RollingCounter "Rolling counter
循环计数器";
CM_ SG_ 144 WCBS_ESC_ABA_Available "Brake Assist(ABA) Avaliable
辅助制动功能可用";
CM_ SG_ 144 WCBS_ESC_ABA_Active "Brake Assist(ABA) Active
辅助制动激活";
CM_ SG_ 144 WCBS_90h_CheckSUM "校验和
checksum = (Byte0+Byte1 …+ Byte6) XOR 0xFF";
CM_ BO_ 146 "车速、前轮速";
CM_ SG_ 146 WCBS_ESC_VehSpd "Speed,sending 0x7FFF when invalid
车速，当无效时发送0x7FFF";
CM_ SG_ 146 WCBS_ESC_WhlFLSpd "Left front wheel wheel speed
左前轮轮速";
CM_ SG_ 146 WCBS_ESC_WhlFRSpd "Right front wheel wheel speed
右前轮轮速";
CM_ SG_ 146 WCBS_92h_RollingCounter "Rolling counter
循环计数器";
CM_ SG_ 146 WCBS_ESC_WhlSpdFRVd "Right front wheel speed signal validity
右前轮速信号有效性";
CM_ SG_ 146 WCBS_ESC_WhlSpdFLVd "Left front wheel speed signal validity
左前轮速信号有效性";
CM_ SG_ 146 WCBS_ESC_VehSpdVd "Speed Signal validity
车速信号有效性";
CM_ SG_ 146 WCBS_92h_CheckSUM "校验和
checksum = (Byte0+Byte1 …+ Byte6) XOR 0xFF";
CM_ SG_ 594 MCU_F_FailureNum "Number of current failures
当前故障数目";
CM_ SG_ 594 MCU_F_ResolverFault "MCU spin fault
MCU旋变故障";
CM_ SG_ 594 MCU_F_Err_IGBT "IGBT fault
IGBT故障";
CM_ SG_ 594 MCU_F_CurrentOverload "Overcurrent State
过流状态";
CM_ SG_ 594 MCU_F_Controllertemp_Status "Drive Motor controller Temperature state
驱动电机控制器温度状态";
CM_ SG_ 594 MCU_F_stDischg "Active discharge Status
主动放电状态";
CM_ SG_ 594 MCU_F_SpeedOtLoopFalult "Out Speed Loop Response Failure
外部转速环响应故障";
CM_ SG_ 594 MCU_F_MdTepErr "Module temperature Detection Value exception
模块温度检测值异常";
CM_ SG_ 594 MCU_F_ControllerOverVolt_Status "Overvoltage State of Motor controller
电机控制器过压状态";
CM_ SG_ 594 MCU_F_MotorTemp_Fault "Drive Motor Temperature Alarm
驱动电机温度报警";
CM_ SG_ 594 MCU_F_MotorOverSpd "Motor Overspeed Failure
电机超速故障";
CM_ SG_ 594 MCU_F_VCUCommErr "Abnormal communication with VCU
与VCU通讯异常";
CM_ SG_ 594 MCU_F_ControllerLowUnderVolt_Status "Low pressure undervoltage State of motor controller
电机控制器低压欠压状态";
CM_ SG_ 594 MCU_F_ControllerUnderVolt_Status "Voltage State of Motor controller
电机控制器欠压状态";
CM_ SG_ 594 MCU_F_ControllerFault "Motor Controller Failure
电机控制器故障";
CM_ SG_ 594 MCU_F_unload_status "Front MCU unload Status
前电机卸载状态";
CM_ SG_ 594 FMCU_HV_Interlock_Falult "FMCU HV Interlock Falult                                              前电机高压互锁故障";
CM_ SG_ 594 FMCU_Uncap_Falult "FMCU uncap fault                                                      前电控开盖故障";
CM_ SG_ 594 MCU_F_MotTepErr "Abnormal motor temperature detection value
电机温度检测值异常";
CM_ SG_ 130 MCU_F_stMode "PEB Current operating mode
PEB当前运行模式";
CM_ SG_ 130 MCU_F_TrqCurrValid "Motor Torque Signal Failure
电机扭矩信号有效性";
CM_ SG_ 130 MCU_F_TrqCurr "Current actual Axle torque of the motor
电机当前实际扭矩(轴端)";
CM_ SG_ 130 MCU_F_NCurr "Current actual Axle speed of the motor
电机当前实际转速(轴端)";
CM_ SG_ 130 MCU_F_NCurrValid "EV Motor Speed Signal Failure
EV电机转速信号有效性";
CM_ SG_ 130 MCU_F_UdcCurr "Current actual voltage of Busbar
母线当前实际电压";
CM_ SG_ 130 MCU_F_82h_RollingCounter "Rolling counter
循环计数器";
CM_ SG_ 130 MCU_F_82h_CheckSUM "校检和 checksum = (Byte0+Byte1 …+ Byte6) XOR 0xFF";
CM_ SG_ 132 MCU_F_ControlerTemp "Front MCU Controler Temperature
前电机控制器温度";
CM_ SG_ 132 MCU_F_TempCurr "Actual temperature of front motor
前电机实际温度";
CM_ SG_ 132 MCU_F_ThreePhaseCurU "Front MCU Three Phase Current
前电机三相电流值(U)";
CM_ SG_ 132 MCU_F_ThreePhaseCurV "Front MCU Three Phase Current
前电机三相电流值(V)";
CM_ SG_ 132 MCU_F_ThreePhaseCurW "Front MCU Three Phase Current
前电机三相电流值(W)";
CM_ SG_ 580 MCU_R_ControlerTemp "Rear MCU Controler Temperature
后电机控制器温度";
CM_ SG_ 580 MCU_R_TempCurr "Actual temperature of rear motor
后电机实际温度";
CM_ SG_ 580 MCU_R_ThreePhaseCurU "Front MCU Three Phase Current
前电机三相电流值(U)";
CM_ SG_ 580 MCU_R_ThreePhaseCurV "Front MCU Three Phase Current
前电机三相电流值(V)";
CM_ SG_ 580 MCU_R_ThreePhaseCurW "Front MCU Three Phase Current
前电机三相电流值(W)";
CM_ SG_ 608 MCU_R_FailureNum "Number of current failures
当前故障数目";
CM_ SG_ 608 MCU_R_ResolverFault "MCU spin fault
MCU旋变故障";
CM_ SG_ 608 MCU_R_Err_IGBT "IGBT fault
IGBT故障";
CM_ SG_ 608 MCU_R_CurrentOverload "Overcurrent State
过流状态";
CM_ SG_ 608 MCU_R_Controllertemp_Status "Drive Motor controller Temperature state
驱动电机控制器温度状态";
CM_ SG_ 608 MCU_R_stDischg "Active discharge Status
主动放电状态";
CM_ SG_ 608 MCU_R_SpeedOtLoopFalult "Out Speed Loop Response Failure
外部转速环响应故障";
CM_ SG_ 608 MCU_R_MdTepErr "Module temperature Detection Value exception
模块温度检测值异常";
CM_ SG_ 608 MCU_R_ControllerOverVolt_Status "Overvoltage State of Motor controller
电机控制器过压状态";
CM_ SG_ 608 MCU_R_MotorTemp_Fault "Drive Motor Temperature Alarm
驱动电机温度报警";
CM_ SG_ 608 MCU_R_MotorOverSpd "Motor Overspeed Failure
电机超速故障";
CM_ SG_ 608 MCU_R_VCUCommErr "Abnormal communication with VCU
与VCU通讯异常";
CM_ SG_ 608 MCU_R_ControllerLowUnderVolt_Status "Low pressure undervoltage State of motor controller
电机控制器低压欠压状态";
CM_ SG_ 608 MCU_R_ControllerUnderVolt_Status "Voltage State of Motor controller
电机控制器欠压状态";
CM_ SG_ 608 MCU_R_ControllerFault "Motor Controller Failure
电机控制器故障";
CM_ SG_ 608 MCU_R_unload_status "Rear MCU unload Status
后电机卸载状态";
CM_ SG_ 608 RMCU_HV_Interlock_Falult "RMCU HV Interlock Falult                                              前电机高压互锁故障";
CM_ SG_ 608 RMCU_Uncap_Falult "RMCU uncap fault                                                      前电控开盖故障";
CM_ SG_ 608 MCU_R_MotTepErr "Abnormal motor temperature detection value
电机温度检测值异常";
CM_ SG_ 178 MCU_R_stMode "PEB Current operating mode
PEB当前运行模式";
CM_ SG_ 178 MCU_R_TrqCurrValid "Motor Torque Signal Failure
电机扭矩信号有效性";
CM_ SG_ 178 MCU_R_TrqCurr "Current actual Axle torque of the motor
电机当前实际扭矩(轴端)";
CM_ SG_ 178 MCU_R_Ncurr "Current actual Axle speed of the motor
电机当前实际转速(轴端)";
CM_ SG_ 178 MCU_R_NCurrValid "EV Motor Speed Signal Failure
EV电机转速信号有效性";
CM_ SG_ 178 MCU_R_UdcCurr "Current actual voltage of Busbar
母线当前实际电压";
CM_ SG_ 178 MCU_R_B2h_RollingCounter "Rolling counter
循环计数器";
CM_ SG_ 178 MCU_R_B2h_CheckSUM "校检和 checksum = (Byte0+Byte1 …+ Byte6) XOR 0xFF";
CM_ BO_ 772 "充电有关的信号2";
CM_ SG_ 772 OBC_out_Cur_over_prot "Charger Output Current Over Fault
充电机输出过流保护";
CM_ SG_ 772 OBC_out_vol_Less_prot "Charger Input Voltage Less Fault
充电机输出欠压保护";
CM_ SG_ 772 OBC_out_vol_over_prot "Charger Output Voltage Over Faul
充电机输出过压保护";
CM_ SG_ 772 OBC_In_Cur_over_prot "Charger Input Current Over Fault
充电机输入过流保护";
CM_ SG_ 772 OBC_ChargerInputVoltageLessFault "Charger Input Voltage Less Fault
充电机输入电压欠压保护";
CM_ SG_ 772 OBC_ChargerInputVoltageOverFault "Charger Input Voltage Over Fault
充电机输入电压过压保护";
CM_ SG_ 772 ChargeInterfaceOverTemp "Charger Temperature Over Fault
充电口过温";
CM_ SG_ 772 ChargeInterfacetemperature "Charger Temperature
充电口温度";
CM_ SG_ 772 OBC_ControllerTemp "OBC Controller Temperature
充电机控制器温度";
CM_ SG_ 772 OBC_ChargerOTP "Charger Over Temperature Protection
OBC过温保护状态";
CM_ SG_ 772 OBC_ChargerCoolingRequest "Request of OBC Cooling                                           充电机冷却请求";
CM_ SG_ 772 OBC_ChargerHardwareFault "Charger Hardware Fault
OBC硬件故障";
CM_ SG_ 772 OBC_Charger_CAN_Fault "CAN_Fault                                                                                              CAN故障";
CM_ SG_ 772 OBC_Charger_Fail_State "OBC Fail State                                                             充电机故障状态";
CM_ SG_ 772 OBC_Charger_NoBatt "NoBatt                                                                          充电机未检测到电池包或电池电压过低";
CM_ SG_ 772 OBC_CP_DutyCycleValue "CP DutyCycleValue                                                                                CP占空比数值";
CM_ SG_ 772 OBC_CP_Rsv "OBC_CP
外部能量状态";
CM_ SG_ 772 OBC_CC_Resistance "OBC_CC
充电连接CC状态";
CM_ SG_ 772 OBC_ChargerStatus "Charger  Status
OBC状态";
CM_ SG_ 772 KL30_UnderVolt "KL30_UnderVolt                                                                                     KL30电源过欠压";
CM_ SG_ 772 ElectronicLockSts "ElectronicLockSts                                                电子锁状态";
CM_ SG_ 772 ElectronicLockFault "ElectronicLockFault                                               电子锁故障状态";
CM_ SG_ 772 OBC_Charger_Instructions "AC Charge Indicator
交流充电指示";
CM_ SG_ 772 OBC_Charger_Request "AC Chargee Req
交流充电请求";
CM_ SG_ 770 DCDC_Voltage_Input "DCDC Input Voltage
DCDC输入电压";
CM_ SG_ 770 DCDC_Voltage_Output "DCDC Output Voltage
DCDC输出电压";
CM_ SG_ 770 DCDC_Current_Input "DCDC Input Current 
DCDC输入电流";
CM_ SG_ 770 DCDC_Current_Output "DCDC Output Current
DCDC输出电流";
CM_ BO_ 776 "DCDC有关的信号2";
CM_ SG_ 776 DCDC_Status "DCDC Controller Status
DCDC控制器状态";
CM_ SG_ 776 DCDC_IN_vol_over_prot "DCDC Input overvoltage Protection
DCDC输入过压保护";
CM_ SG_ 776 DCDC_IN_vol_Less_prot "DCDC Input undervoltage Protection
DCDC输入欠压保护";
CM_ SG_ 776 DCDC_short_err "DCDC Output Short Circuit fault
DCDC输出短路保护";
CM_ SG_ 776 DCDC_Out_Curr_Over_prot "DCDC OutputOverCurr                                   DCDC输出过流";
CM_ SG_ 776 DCDC_out_vol_over_prot "DCDC Output overvoltage Protection
DCDC输出过压保护";
CM_ SG_ 776 DCDC_out_vol_Less_prot "DCDC Output Undervoltage Protection
DCDC输出欠压保护";
CM_ SG_ 776 DCDC_out_VolSt "DCDC Output End Voltage state
DCDC输出端电压状态";
CM_ SG_ 776 DCDC_Fault "DCDC Controller Fault Alarm
DCDC控制器故障报警";
CM_ SG_ 776 DCDC_OverTemp_Fault "DCDC temperature is too high to malfunction
DCDC温度过高故障";
CM_ SG_ 776 DCDC_WorkingMode "DCDC WorkingMode                                                                               DCDC工作模式";
CM_ SG_ 776 DCDC_EnableSts "DCDC EnableStates                                                                              DCDC使能状态反馈";
CM_ SG_ 776 DCDC_CoolingReq "Request of DCDC Cooling                                DCDC冷却请求";
CM_ SG_ 776 DCDC_ControllerTemp "DCDC Controller Temperature
DCDC控制器温度";
CM_ BO_ 880 "PDU有关的信号2";
CM_ SG_ 880 PDU_AirPTC_WorkStus "风PTC工作状态";
CM_ SG_ 372 VCU_Err_AccPedal "Throttle Pedal Failure
油门踏板故障";
CM_ SG_ 372 VCU_InsuldDetcCtrl "Insulation Monitor Control
绝缘监测控制";
CM_ SG_ 372 VCU_GearPosition "Gear status (R\/N\/D/P)
档位状态（R/N/D/P）";
CM_ SG_ 372 VCU_PrechrgAnodeRelay_Status "Pre-recharge CONTACTOR status (reserved)
预充接触器状态（预留）";
CM_ SG_ 372 VCU_DischrgAnodeRelay_Control "Main CONTACTOR (discharge main connector) control
主接触器（放电主接）控制";
CM_ SG_ 372 VCU_DischrgAnodeRelay_Status "Main contactor (discharge main connection) status (reserved)
主接触器（放电主接）状态（预留）";
CM_ SG_ 372 VCU_DischrgCathodeRelay_Control "Cathode CONTACTOR Control
负极接触器控制";
CM_ SG_ 372 VCU_DischrgCathodeRelay_status "Cathode contactor Status (reserved)
负极接触器状态（预留）";
CM_ SG_ 372 VCU_PrechrgAnodeRelay_Control "Pre-recharge CONTACTOR control
预充接触器控制";
CM_ SG_ 372 VCU_PTSystem_Satus "Power system fault Status
动力系统故障状态";
CM_ SG_ 372 VCU_VehSysStatus "Full Vehicle system status
整车系统状态";
CM_ SG_ 372 VCU_ChrgRelay_Control "Charging CONTACTOR Control
充电接触器控制";
CM_ SG_ 372 VCU_GearCtrlSts "Gear Control Status
档位控制状态";
CM_ SG_ 372 VCU_Cruise_MainSwitch "Main Cruise Switch
主巡航开关";
CM_ SG_ 372 VCU_OperationMode "Running mode
运行模式";
CM_ SG_ 372 VCU_DrivingMode "Driving mode
驱动模式(两驱或四驱)";
CM_ SG_ 372 VCU_FMCU_unloadReq "Front MCU Unload Request
前电机卸载请求";
CM_ SG_ 372 VCU_RMCU_unloadReq "Rear MCU Unload Request
后电机卸载请求";
CM_ SG_ 372 VCU_AC_unloadReq "AC Unload Request
空调卸载请求";
CM_ SG_ 372 VCU_TortoiseIndicator "Turtle Speed Lamp Indication
龟速灯指示";
CM_ SG_ 372 VCU_ActiveDischargeOrder "Active Discharge Command
主动泄放命令";
CM_ SG_ 372 VCU_Cruise_Enable "Cruise enable
巡航使能";
CM_ SG_ 372 VCU_174h_RollingCounter "Rolling counter
循环计数器";
CM_ SG_ 372 VCU_UnlockSts "VCU anti-theft cancellation status
VCU防盗解除状态";
CM_ SG_ 372 VCU_StartAllow "Vehicle Start Allowed
车辆启动允许";
CM_ SG_ 372 VCU_174h_CheckSUM "校检和 checksum = (Byte0+Byte1 …+ Byte6) XOR 0xFF";
CM_ SG_ 568 VCU_AllowedMaxDisChrgPowerOfAC "AC Maximum allowable discharge power
AC最大允许放电功率(总系统功率)";
CM_ SG_ 568 VCU_AC_PasCabinAllowedPower "Passenge Cabin allowed For AC Power
乘客舱AC允许的功率";
CM_ SG_ 568 VCU_AC_Permittion "AC allowed
AC是否允许(AC使能)";
CM_ SG_ 568 FPump_Enable "前水泵使能信号";
CM_ SG_ 568 FPump_Target_Speed "Front water pump target speed
前水泵目标转速（0-100%）";
CM_ SG_ 568 VCU_VehicleMaintenanceMode "Vehicle Maintenance Mode
车辆维修模式";
CM_ SG_ 568 VCU_CoolingFanSt "Cooling Fan Status
冷却风扇状态";
CM_ SG_ 568 VCU_StartInf "Veicle Start Information                                     车辆启动提示";
CM_ SG_ 568 VCU_ChaGearInf "Change gear Information                                    换挡提示";
CM_ SG_ 568 VCU_ChgCpleInDrvInfor "Cahrger Gun Inset Information while driving
行车插枪提示";
CM_ SG_ 568 RPump_Enable "后水泵使能信号";
CM_ SG_ 568 RPump_Target_Speed "后水泵目标转速（0-100%）";
CM_ SG_ 568 VCU_ShutDwnRmdr "HV ShutDown Inf
下高压提示信息";
CM_ SG_ 568 VCU_PowerOffWarmingInfo "Power off warming information
下电提示信息";
CM_ SG_ 568 VCU_APTC_PowerGear "风PTC功率档位";
CM_ SG_ 570 VCU_FastchrgAllowedPower "Fast charge maximum allowable charging power
快充充电最大允许充电功率";
CM_ SG_ 570 VCU_SlowchrgAllowedPower "Slow charge maximum allowable charging power
慢充充电最大允许充电功率";
CM_ SG_ 570 VCU_Fastchrg_Permittion "is fast charging allowed
快充充电是否允许";
CM_ SG_ 570 VCU_Slowchrg_Permittion "Is slow charging allowed
慢充充电是否允许";
CM_ SG_ 570 VCU_AC_ChrgStatus "AC Charging Status
交流充电状态";
CM_ SG_ 570 VCU_OBC_Permittion "OBC allowed
OBC是否允许";
CM_ SG_ 570 VCU_EnergyRecoverySt "Energy Recovery Grade Status
能量回收等级状态";
CM_ SG_ 570 VCU_PwrFlowIndcr "Power flow indicator
能量流";
CM_ SG_ 570 VCU_DC_ChrgStatus "DC Charging Status
直流充电状态";
CM_ SG_ 570 VCU_V2V_ChrgStatus "V2V Charging Status
对外放电状态";
CM_ SG_ 570 VCU_ChargTotalPower "Charging Mode Total Power of Vehicle
充电整车负载功率";
CM_ SG_ 570 VCU_PowerSysRemainPower "PowerSysRemainPower
动力系统剩余功率";
CM_ SG_ 574 VCU_TbUnlockSts "VCU防盗解除状态（与TBOX之间的交互）";
CM_ SG_ 574 VCU_RCt_ModeSts "远控模式/状态";
CM_ SG_ 574 VCU_VehPowerMode "整车动力模式（国标）";
CM_ SG_ 574 VCU_Precharge_Satus "预充状态";
CM_ SG_ 574 VCU_request_subscribe_allow "预约充电允许";
CM_ SG_ 574 VCU_DCSystemDischrgAllowed "DC放电允许";
CM_ SG_ 574 VCU_EnduranceMileage "Mileage of continuous driving
续驶里程";
CM_ SG_ 574 VCU_DriveMotorNum "Number of drive motors (GB)
驱动电机个数（国标）";
CM_ SG_ 574 VCU_23Eh_RollingCounter "Rolling counter
循环计数器";
CM_ SG_ 574 VCU_MotorLockAllowed "Allow lock motor commands
允许锁电机命令";
CM_ SG_ 574 VCU_MotorLockSts "Lock Motor Status
锁电机状态";
CM_ SG_ 574 VCU_23Eh_CheckSUM "校检和 checksum = (Byte0+Byte1 …+ Byte6) XOR 0xFF";
CM_ SG_ 112 VCU_DriverLeverIntervention "Driver Gear Lever Intervention
驾驶员换挡干预";
CM_ SG_ 112 VCU_BrkSw_Sta "Brake switch signal status
刹车开关信号状态";
CM_ SG_ 112 VCU_BrkSw_V "Brake switch signal Vaild
刹车开关信号有效标识位";
CM_ SG_ 112 VCU_Acc_Validity "Accelerator Eff. Position Validity
油门踏板位置信号有效标识位";
CM_ SG_ 112 VCU_BrkPed_Pos "Brake pedal position
刹车踏板位置（预留）";
CM_ SG_ 112 VCU_Acc_pedal_position "Throttle Pedal Input Depth
油门踏板输入深度";
CM_ SG_ 112 VCU_Accel_Padel_Pos_Calc "calculated acceleration pedal position
计算的加速踏板位置";
CM_ SG_ 112 VCU_70h_RollingCounter "Rolling counter
循环计数器";
CM_ SG_ 112 VCU_DriverOverride "Driver Override Operator
驾驶员超控";
CM_ SG_ 112 VCU_70h_CheckSUM "校检和 checksum = (Byte0+Byte1 …+ Byte6) XOR 0xFF'";
CM_ SG_ 913 VSP_PermanentStsFeedback "VSP永久状态反馈";
CM_ SG_ 913 VSP_ShorterStsFeedback "VSP单次状态反馈";
CM_ SG_ 913 VSP_StopModeStsFeedback "VSP停车模式状态反馈";
CM_ SG_ 913 VSP_VoiceSourceStateFeedback "VSP声源状态反馈";
CM_ BO_ 656 "TBOX远程控制指令2";
CM_ SG_ 656 Tbox_UnlockSts "Tbox防盗解除状态";
CM_ SG_ 656 TBOX_AuthentificationRQ "防盗请求";
CM_ SG_ 656 TBOX_FuncSts "预约充电功能状态";
CM_ SG_ 656 Tbox_PELockCtl "蓝牙PKE走近解锁命令";
CM_ SG_ 656 TBOX_TimeSts "预约充电时间状态";
CM_ BO_ 645 "年月日时分秒";
CM_ SG_ 645 TBOX_Second "秒";
CM_ SG_ 645 TBOX_Minute "分";
CM_ SG_ 645 TBOX_Hour "小时";
CM_ SG_ 645 TBOX_Day "天";
CM_ SG_ 645 TBOX_Month "月";
CM_ SG_ 645 TBOX_Year "年，基础年份为2000年";
CM_ SG_ 645 TBOX_TimeCheckBit "时间校验位";
CM_ SG_ 645 TBOX_InvalidByte "无效字节";
CM_ SG_ 662 TBOX_VehiclePosition_longitude "车辆定位经度-度数";
CM_ SG_ 662 TBOX_VehiclePosition_latitude "车辆定位纬度-度数";
CM_ SG_ 664 Tbox_VehiclePosition_gradient "坡度";
CM_ SG_ 664 Tbox_VehiclePosition_altitude "海拔";
CM_ SG_ 664 Tbox_VehiclePosition_headDirection "车辆朝向(正北为0，正南为180)";
CM_ SG_ 664 Tbox_MMI_GPS_Country_Code "GPS enum code that can tell camera in which country ego car is running
GPS国家码";
CM_ SG_ 664 Tbox_MMI_FICM_Available "Indicate whether GPS national code signal is available
指示GPS国家码信号是否可用";
CM_ SG_ 148 EHB_FaultSt "EHB Fault State
EHB 故障状态";
CM_ SG_ 328 EPB_Brake_Lights_Request_L "brake lights request

点亮刹车灯请求";
CM_ SG_ 328 EPB_SwitchSta_L "EPB Switch State 

EPB开关状态";
CM_ SG_ 328 EPB_WarnLampSta_L "EPB Warning Lamp State

EPB故障灯状态";
CM_ SG_ 328 EPB_ParkLampSta_L "Park Lamp State

驻车灯状态";
CM_ SG_ 328 EPB_ActuatorSt_L "Lift EPB Actuator State

左Moc状态";
CM_ SG_ 328 EPB_DisplayMsgID_L "Display  Message ID Requested by EPB to ICU   仪表文字提示信息";
CM_ SG_ 328 EPB_148h_RollingCounter "Rolling counter
循环计数器";
CM_ SG_ 328 EPB_148h_CheckSUM "校验和
checksum = (Byte0+Byte1 …+ Byte6) XOR 0xFF";
CM_ SG_ 336 EPB_Brake_Lights_Request_R "brake lights request

点亮刹车灯请求";
CM_ SG_ 336 EPB_SwitchSta_R "EPB Switch State 

EPB开关状态";
CM_ SG_ 336 EPB_WarnLampSta_R "EPB Warning Lamp State

EPB故障灯状态";
CM_ SG_ 336 EPB_ParkLampSta_R "Park Lamp State

驻车灯状态";
CM_ SG_ 336 EPB_ActuatorSt_R "Right EPB Actuator State
右 EPD 执行器状态";
CM_ SG_ 336 EPB_DisplayMsgID_R "Display  Message ID Requested by EPB to ICU   
仪表文字提示信息";
CM_ SG_ 336 EPB_150h_RollingCounter "Rolling counter
循环计数器";
CM_ SG_ 336 EPB_150h_CheckSUM "校验和
checksum = (Byte0+Byte1 …+ Byte6) XOR 0xFF";
CM_ SG_ 336 ESC_VehSpd "Speed,sending 0x7FFF when invalid
车速，当无效时发送0x7FFF";
CM_ SG_ 336 ESC_92h_RollingCounter "Rolling counter
循环计数器";
CM_ SG_ 336 ESC_VehSpdVd "Speed Signal validity
车速信号有效性";
CM_ SG_ 336 ESC_92h_CheckSUM "校验和
checksum = (Byte0+Byte1 …+ Byte6) XOR 0xFF";
CM_ SG_ 584 AC_AutoMode "AC自动模式";
CM_ SG_ 584 AC_ActualBlowingMode "AC实际吹风模式";
CM_ SG_ 584 AC_ActualCirculationMode "AC实际内外循环模式";
CM_ SG_ 584 AC_DVDDisplayReq "大屏弹窗请求";
CM_ SG_ 584 AC_TempSetPoint "Temp set point
AC设定温度";
CM_ SG_ 584 AC_ActualAirQuantity "AC实际风量大小";
CM_ SG_ 584 AC_FwdDeforstSts "前除霜状态";
CM_ SG_ 584 AC_RearDeforstSts "后除霜状态(预留)";
CM_ SG_ 584 AC_CoolingStaus "AC制冷状态";
CM_ SG_ 584 AC_MaxCooingStaus "AC最大制冷状态";
CM_ SG_ 584 AC_OffStaus "AC关机状态";
CM_ SG_ 584 AC_PM25_Status "PM2.5 Status
PM2.5 状态";
CM_ SG_ 584 AC_RearViewMirroHeatStatus "Rear View Mirror Heat Status
后视镜加热状态反馈";
CM_ SG_ 584 AC_NegativeIconGenStus "AC Negative Icon genarator status
负离子发生器状态";
CM_ SG_ 607 AC_AmbientAirTemperature "环境温度";
CM_ SG_ 607 AC_AmbientAirTemperature_Corrected "校准后环境温度";
CM_ SG_ 607 AC_IncarTemperature "车内温度";
CM_ SG_ 607 AC_BatteryPumpState "电池回路水泵状态";
CM_ SG_ 607 AC_ACMode "空调模式";
CM_ SG_ 607 AC_BatteryPumpSpeed "电池回路水泵转速";
CM_ SG_ 607 AC_RearDeforstReq "Rear deforst request
后除霜请求";
CM_ SG_ 607 AC_AmbientAirTemperature_Validity "环境温度有效性";
CM_ SG_ 607 AC_Fan_SpeedReq "电子扇转速请求";
CM_ SG_ 607 AC_SeatHeatReq_right "副驾座椅加热请求（预留）";
CM_ SG_ 607 AC_SeatHeatReq_left "主驾座椅加热请求（预留）";
CM_ SG_ 607 AC_WorkingResponse_Status "AC反馈工作状态";
CM_ SG_ 607 AC_unload_Status "AC卸载";
CM_ BO_ 390 "AVM发给MMI的信号2(预留)";
CM_ SG_ 390 AVM_BSDLeftWaringSeverity "BSD左侧报警严重度(预留)";
CM_ SG_ 390 AVM_BSDLeftWaringValid "BSD左侧报警有效(预留)";
CM_ SG_ 390 AVM_BSDRightWaringSeverity "BSD右侧报警严重度(预留)";
CM_ SG_ 390 AVM_BSDRightWaringValid "BSD右侧报警有效(预留)";
CM_ SG_ 390 AVM_BSDStatus "BSD状态(预留)";
CM_ SG_ 390 AVM_BSDStatusValid "BSD状态位是否有效(预留)";
CM_ BO_ 392 "AVM发给MMI的信号1";
CM_ SG_ 392 AVM_MMI_ConnectStatus "AVM  connect status
AVM  与MMI连接状态";
CM_ SG_ 392 AVM_MMI_EcuStatus "Signal from AVM to indicate ECU status 
AVM ECU状态(0xF: invalid/提示用户AVM_ECU状态异常)";
CM_ SG_ 392 AVM_MMI_VideoOutputStatus "AVM Ecu Video output status
AVM Ecu视频输出状态(0x3: invalid/显示MMI画面)";
CM_ SG_ 392 AVM_MMI_AVM3DViewModeStatus "AVM3D View Mode Status";
CM_ SG_ 392 AVM_MMI_AVM3DViewSwitch "AVM3D视角状态";
CM_ BO_ 788 "AVM发给MMI的信号3";
CM_ SG_ 788 AVM_MCU_Version "Signal from AVM to indicate MCU version
标识MCU版本";
CM_ SG_ 788 AVM_BSP_Version "Signal from AVM to indicate BSP version
标识BSP版本";
CM_ BO_ 790 "AVM发给MMI的信号4";
CM_ SG_ 790 AVM_ZADAS_Version "Signal from AVM to indicate Zadas version
标识ZADAS版本";
CM_ SG_ 790 Avm3d_licenseStatus "Signal from AVM to indicate if contained avm3d license
是否包含AVM 3D授权";
CM_ SG_ 790 BSD_licenseStatus "Signal from AVM to indicate if contained BSD license
是否包含BSD授权";
CM_ SG_ 338 BCM_RFDoorSwitchSt "Right front door status signal
右前车门状态信号";
CM_ SG_ 338 BCM_LFDoorSwitchSt "Left Front door status signal
左前车门状态信号";
CM_ SG_ 338 BCM_PositionLampSt "Position lamp Status
位置灯状态";
CM_ SG_ 338 BCM_FrontFogligthSt "Front fog lamp Status
前雾灯状态(预留)";
CM_ SG_ 338 BCM_BackFogligthSt "Rear fog lamp status
后雾灯状态";
CM_ SG_ 338 BCM_HighBeamStatus "Remote Light Status
远光灯状态";
CM_ SG_ 338 BCM_LowBeamStatus "Near light status
近光灯状态";
CM_ SG_ 338 BCM_TrunkSt "Suitcase Door Status Signal
行李箱门状态信号";
CM_ SG_ 338 BCM_TurnLeverLoc "Turn Level Location
转向拨杆位置";
CM_ SG_ 338 BCM_RightligthFaultSt "Right Turn light malfunction
右转向灯故障";
CM_ SG_ 338 BCM_RightligthSt "Right steering State signal
右转向状态信号";
CM_ SG_ 338 BCM_LetfligthFaultSt "Left Turn lamp fault
左转向灯故障";
CM_ SG_ 338 BCM_LetfligthSt "Left steering State signal
左转向状态信号";
CM_ SG_ 338 BCM_LRDoorSwitchSt "Left rear door status signal
左后车门状态信号";
CM_ SG_ 338 BCM_RRDoorSwitchSt "Right rear door status signal
右后车门状态信号";
CM_ SG_ 338 BCM_CentralLockSt "Switch state of central control lock
中控锁开关状态";
CM_ SG_ 338 BCM_Reverse_Light "status of reverse lights
倒车灯状态";
CM_ SG_ 338 Bcm_OutSwitchPressCmd "Back door control command (lateral button)
后背门控制命令（外侧按键）(预留，适用PLG)";
CM_ SG_ 338 BCM_HazardwarnLampSt "Hazard Alarm Lamp Status signal
危险报警灯状态信号";
CM_ SG_ 338 BCM_PassSeatbeltBucklestatus "Passenger seat belt buckle status
副驾驶安全带状态";
CM_ SG_ 338 BCM_DrvSeatbeltBucklestatus "Driver seat belt buckle status
驾驶员安全带状态";
CM_ SG_ 338 BCM_FrontCoverSt "Front Hatch Status Signal
前舱盖状态信号(预留)";
CM_ SG_ 338 BCM_WiperMaintainFuncCtrStus "雨刮维护功能控制功能状态";
CM_ SG_ 338 BCM_HornStus "喇叭状态";
CM_ SG_ 338 BCM_PositionLampOpenWarm "位置灯未关报警";
CM_ SG_ 338 BCM_Auto_LightSwitch "Whether the far and near light switch is in 'Auto' gear
远近光灯开关是否处于AUTO挡";
CM_ SG_ 338 BCM_Brake_Light "status of brake lights
刹车灯状态";
CM_ SG_ 338 BCM_RearViewMirrorAutoFoldFucFeedback "后视镜自动折叠功能反馈";
CM_ SG_ 338 BCM_Rain_Sensor "indicate rain level
雨量等级(AUTO挡时，雨量传感器请求的雨刮状态)";
CM_ SG_ 338 BCM_DrvSeatbeltBucklevalidity "Driver seat belt buckle validity
驾驶员安全带状态信号有效性";
CM_ SG_ 338 BCM_PassSeatbeltBucklevalidity "Passenger seat belt buckle validity
副驾驶安全带状态信号有效性";
CM_ SG_ 338 BCM_PowerMode "System power supply
That is: ignition status
系统电源
即：点火状态";
CM_ SG_ 338 BCM_RearViewMirror "RearViewMirror Status
后视镜状态";
CM_ SG_ 338 BCM_ChargeCoverLockStatus "Charge Cover Lock Status
充电口盖锁状态(预留)";
CM_ SG_ 338 BCM_RearDeforstSts "Rear deforst status
后除霜状态";
CM_ SG_ 338 BCM_BkSeat_1_beltBucklevalidity "Back seat 1 belt buckle validity
后排座椅安全带1状态信号有效性";
CM_ SG_ 338 BCM_BkSeat_1_beltBucklestatus "Back seat 1 belt buckle status
后排1安全带状态";
CM_ SG_ 338 BCM_BkSeat_2_beltBucklevalidity "Back seat 2 belt buckle validity
后排座椅安全带2状态信号有效性";
CM_ SG_ 338 BCM_BkSeat_2_beltBucklestatus "Back seat 2 belt buckle status
后排2安全带状态";
CM_ SG_ 338 BCM_BkSeat_3_beltBucklevalidity "Back seat 3 belt buckle validity
后排座椅安全带3状态信号有效性";
CM_ SG_ 338 BCM_BkSeat_3_beltBucklestatus "Back seat 3 belt buckle status
后排3安全带状态";
CM_ SG_ 338 BCM_RainAutoClsWindowFuncStus "雨天自动关闭四门车窗功能状态";
CM_ SG_ 338 BCM_LockVehicleWarmingTipStus "锁车提醒方式状态(预留)";
CM_ SG_ 338 BCM_CourtesyLampStus "迎宾灯状态";
CM_ SG_ 338 BCM_VehicleCourtesyLampFuncStus "车辆迎宾灯功能状态(预留)";
CM_ SG_ 338 BCM_AccLampSetStus "伴我回家灯设置状态";
CM_ SG_ 588 PEPS_KeyInCarWarning "Failed lock warning for the key is in the car 
钥匙遗忘在车内 驾驶员提醒（IP:智能钥匙遗忘车内）";
CM_ SG_ 588 ReminderPutInP_Nposition_OFF "Display the reminder of put in P/N position or neutral when OFF.
请切换至P档提醒（IP:请切换至P档下电）";
CM_ SG_ 588 ReminderPutInP_Nposition_Lock "Display the reminder of put in P/N position or neutral when lock.
请切换至P档提醒（IP:请切换至P档）";
CM_ SG_ 588 PEPS_KeyNotInWarning "Display there is no valid key inside.
钥匙不在车内提醒（IP:智能钥匙不在车内）";
CM_ SG_ 588 BCM_FrontWiperSt "Front Wiper Switch Status
前雨刮开关状态";
CM_ SG_ 588 PEPS_PutKeyInIMMOSocket "Put Key In IMMO socket
请将遥控钥匙放置将智能钥匙放置于钥匙槽来执行IMMO启动提醒（IP:将智能钥匙放置于钥匙槽）";
CM_ SG_ 588 PEPS_PowerRelayFault "Power Relay fault
电源故障（任何一个继电器坏掉都报故障）（IP:电源故障）";
CM_ SG_ 588 PEPS_RemoteLowVoltage "Display the key battery low status
遥控钥匙电压低提醒（IP:智能钥匙电量低）";
CM_ SG_ 588 WashStatus "Wash status
洗涤状态";
CM_ SG_ 588 WipeReset "Wipe reset signal
雨刮回位信号";
CM_ SG_ 588 PEPS_ESCLFault "ESCL fault（预留）
ESCL故障（IP:ESCL故障）";
CM_ SG_ 588 PEPS_ESCLUnlockFailed "ESCL unlock failed（预留）
ESCL解锁失败（IP:请转动方向盘）";
CM_ SG_ 588 BCM_SenyClass "Sensitivity modulation class
灵敏度调节等级";
CM_ SG_ 588 FLWS_POS_VIT_FL "Left Front window position
左前车窗位置";
CM_ SG_ 588 FRWS_POS_VIT_FL "Right front window position
右前车窗位置";
CM_ SG_ 588 RLWS_POS_VIT_FL "Left rear Window position
左后车窗位置";
CM_ SG_ 588 RRWS_POS_VIT_FL "Right rear Window position
右后车窗位置";
CM_ SG_ 588 BCM_OpenDoorWarning "开门语音提醒（仅针对远控Ready模式下使用）";
CM_ SG_ 589 PEPS_LastLockType "Last lock type
上次锁类型";
CM_ SG_ 589 PEPS_RkeLockCmd "RKE按键命令";
CM_ SG_ 589 BCM_LFDoorLockStatus "Left front door door lock status
左前门门锁状态(代表4门门锁状态)";
CM_ SG_ 589 BCM_TrunkDoorLockSts "Backup Box door lock status
后备箱门锁状态";
CM_ SG_ 589 PEPS_ESCL_SteeringLockStatus "current ESCL lock status
当前 escl 锁定状态";
CM_ SG_ 589 BCM_RFDoorLockStatus "Right front door door lock status
右前门门锁状态(预留)";
CM_ SG_ 589 BCM_LRDoorLockStatus "Left Backdoor door lock status
左后门门锁状态(预留)";
CM_ SG_ 589 PEPS_DrvDoorRequestSwitchSt "Left front door request switch status
左前门请求开关状态（预留）";
CM_ SG_ 589 PEPS_StartStopButtonSt "Current Boot switch status
当前启动开关状态";
CM_ SG_ 589 PEPS_TrunkRequestSwitchSt "Backup door\/Suitcase Request switch status
后备门/行李箱请求开关状态";
CM_ SG_ 589 PEPS_VDrvDoorRequestSwitchSt "Right front door request switch status (reserved)
右前门请求开关状态（预留）";
CM_ SG_ 589 BCM_RRDoorLockStatus "Right Backdoor door lock status
右后门门锁状态(预留)";
CM_ SG_ 589 BCM_RLS_RQ_WiperSPD "The Sensor requested wiper speed 
雨量传感器请求的雨刮速度.";
CM_ SG_ 589 BCM_RLS_Fault "Rain/Light sensor fault status
雨量光照传感器故障";
CM_ SG_ 589 BCM_RLC_FWLight "Forward light前向光";
CM_ SG_ 589 BCM_RLC_Ambient_Light "Ambient light上方光";
CM_ SG_ 610 BCM_FL_TirePrs "Left Front tire pressure pressure
左前轮胎压压力";
CM_ SG_ 610 BCM_FR_TirePrs "Right Front tire pressure pressure
右前轮胎压压力";
CM_ SG_ 610 BCM_RL_TirePrs "Left rear tire pressure pressure
左后轮胎压压力";
CM_ SG_ 610 BCM_RR_TirePrs "Right rear tire pressure pressure
右后轮胎压压力";
CM_ SG_ 610 BCM_RR_TirePrsSt "Right rear tire pressure state
右后轮胎压状态";
CM_ SG_ 610 BCM_RL_TirePrsSt "Left rear tire pressure state
左后轮胎压状态";
CM_ SG_ 610 BCM_FR_TirePrsSt "Right front tire pressure state
右前轮胎右前轮胎压状态";
CM_ SG_ 610 BCM_FL_TirePrsSt "Left Front tire pressure state
左前轮胎压状态";
CM_ SG_ 612 BCM_FL_TireTpt "Left Front tire temperature
左前轮胎温";
CM_ SG_ 612 BCM_FR_TireTpt "Right front tire temperature
右前轮胎温";
CM_ SG_ 612 BCM_RL_TireTpt "Left rear tire temperature
左后轮胎温";
CM_ SG_ 612 BCM_RR_TireTpt "Right rear tire temperature
右后轮胎温";
CM_ SG_ 612 BCM_RR_TireTptSt "Right rear wheel tire temperature state
右后轮轮胎温状态";
CM_ SG_ 612 BCM_RL_TireTptSt "Left rear wheel tire temperature state
左后轮轮胎温状态";
CM_ SG_ 612 BCM_FR_TireTptSt "Right front wheel tire temperature state
右前轮轮胎温状态";
CM_ SG_ 612 BCM_FL_TireTptSt "Left front wheel tire temperature state
左前轮轮胎温状态";
CM_ SG_ 612 BCM_TPMS_MonStatus "indicate tire pressure and temperature state
反馈四轮胎压胎温整体状态";
CM_ SG_ 612 BCM_TPMS_Fault "indicate system state
进行当前胎压监测系统状态反馈";
CM_ SG_ 613 BCM_RR_TireLose "Right rear wheel sensor RF signal failure
右后轮传感器RF信号故障";
CM_ SG_ 613 BCM_RL_TireLose "Left rear wheel sensor RF signal failure
左后轮传感器RF信号故障";
CM_ SG_ 613 BCM_FR_TireLose "Right front wheel sensor RF signal failure
右前轮传感器RF信号故障";
CM_ SG_ 613 BCM_FL_TireLose "Left front wheel sensor RF signal failure
左前轮传感器RF信号故障";
CM_ SG_ 613 BCM_RR_TireLowVol "Right rear wheel sensor low voltage tips
右后轮传感器低压提示";
CM_ SG_ 613 BCM_RL_TireLowVol "Left rear wheel sensor low voltage tips
左后轮传感器低压提示";
CM_ SG_ 613 BCM_FR_TireLowVol "Right front wheel sensor low voltage tips
右前轮传感器低压提示";
CM_ SG_ 613 BCM_FL_TireLowVol "Left front wheel sensor low voltage tips
左前轮传感器低压提示";
CM_ SG_ 613 BCM_RR_TestSt "TPMS right rear wheel test status
TPMS右后轮测试状态";
CM_ SG_ 613 BCM_RL_TestSt "TPMS left rear wheel test status
TPMS左后轮测试状态";
CM_ SG_ 613 BCM_FR_TestSt "TPMS right front wheel test status
TPMS右前轮测试状态";
CM_ SG_ 613 BCM_FL_TestSt "TPMS left front wheel test status
TPMS左前轮测试状态";
CM_ SG_ 613 BCM_BatVol_ErrFlag "TPMS Supply voltage anomaly
TPMS供电电压异常";
CM_ SG_ 613 BCM_TPMS_TestSt "TPMS Test Status
TPMS 测试状态";
CM_ SG_ 613 BCM_RR_Quikleakage "Right rear wheel sensor fast leak alarm prompt
右后轮传感器快速漏气报警提示";
CM_ SG_ 613 BCM_RL_Quikleakage "Left rear wheel sensor fast leak alarm prompt
左后轮传感器快速漏气报警提示";
CM_ SG_ 613 BCM_FR_Quikleakage "Right front wheel sensor fast leak alarm Tips
右前轮传感器快速漏气报警提示";
CM_ SG_ 613 BCM_FL_Quikleakage "Left front wheel sensor fast leak alarm Tips
左前轮传感器快速漏气报警提示";
CM_ BO_ 665 "主驾座椅电机状态反馈";
CM_ SG_ 665 DSM_D_SlideDirection "主驾座椅前后调节状态";
CM_ SG_ 665 DSM_D_FrontLiftDirection "主驾座椅前升降调节状态";
CM_ SG_ 665 DSM_D_ReclinerDirection "主驾座椅靠背调角调节状态";
CM_ SG_ 665 DSM_D_AllLiftDirection "主驾座椅全升降调节状态";
CM_ SG_ 665 DSM_DrvSeatHandyEntryExitSetStus "便利进出设置状态";
CM_ SG_ 665 DSM_D_SlidePosPercentFinal "主驾座椅前后位置";
CM_ SG_ 665 DSM_D_FrontLiftPosPercentFinal "主驾座椅前升位置";
CM_ SG_ 665 DSM_D_ReclinerPosPercentFinal "主驾座椅靠背位置百分比";
CM_ SG_ 665 DSM_D_AllLiftPosPercentFinal "主驾座椅全升降位置百分比";
CM_ BO_ 667 "副驾座椅电机状态反馈";
CM_ SG_ 667 DSM_P_SlideDirection "副驾座椅前后调节状态";
CM_ SG_ 667 DSM_P_FrontLiftDirection "副驾座椅前升降调节状态";
CM_ SG_ 667 DSM_P_ReclinerDirection "副驾座椅靠背调角调节状态";
CM_ SG_ 667 DSM_P_AllLiftDirection "副驾座椅全升降调节状态";
CM_ SG_ 667 DSM_P_SlidePosPercentFinal "副驾座椅前后位置";
CM_ SG_ 667 DSM_P_FrontLiftPosPercentFinal "副驾座椅前升位置";
CM_ SG_ 667 DSM_P_ReclinerPosPercentFinal "副驾座椅靠背位置百分比";
CM_ SG_ 667 DSM_P_AllLiftPosPercentFinal "副驾座椅全升降位置百分比";
CM_ BO_ 659 "座椅加热与通风状态反馈";
CM_ SG_ 659 FSCM_DrvSeatHeat_Sts "Driver seat heat degree status
驾驶员座椅加热等级状态";
CM_ SG_ 659 FSCM_DrvSeatVentilation_Sts "Driver seat ventilation degree status
驾驶员座椅通风等级状态";
CM_ SG_ 659 FSCM_PassSeatHeat_Sts "Pass Driver seat heat degree status
驾驶员座椅加热等级状态";
CM_ SG_ 659 FSCM_PassSeatVentilation_Sts "Pass Driver seat ventilation degree status
驾驶员座椅通风等级状态";
CM_ BO_ 853 "调光玻璃状态反馈";
CM_ SG_ 853 PSR_FaultStatus "全景天窗控制器失败状态";
CM_ SG_ 853 PSR_PlatfondPellucidityStus "全景天窗透明度状态";
CM_ BO_ 856 "手机无线充电器CWC发出信号";
CM_ SG_ 856 CWC_Status_Charge "手机充电状态";
CM_ SG_ 856 CWC_Info_matter "无线充电器异物检测";
CM_ SG_ 856 CWC_Info_phoneforgotten "手机遗忘提醒";
CM_ SG_ 856 CWC_Over_Temp "充电器过温";
CM_ SG_ 856 CWC_Over_Current "充电器过流";
CM_ SG_ 856 CWC_Over_Voltage "充电器过压";
BA_DEF_ BO_  "NmMessage" ENUM "No","Yes";
BA_DEF_ BO_  "DiagState" ENUM  "No","Yes";
BA_DEF_ BO_  "DiagResponse" ENUM  "No","Yes";
BA_DEF_ BO_  "GenMsgSendType" ENUM  "NoSendType","Cycle","Event","IfActive","CE","CA";
BA_DEF_ BO_  "GenMsgCycleTime" INT 0 0;
BA_DEF_ SG_  "GenSigSendType" ENUM  "NoSendType","Cycle","OnWrite","OnWriteWithRepetition","OnChange","OnChangeWithRepetition","IfActive","IfActiveWithRepetition";
BA_DEF_ SG_  "GenSigStartValue" INT 0 0;
BA_DEF_ SG_  "GenSigInvalidValue" STRING;
BA_DEF_ BO_  "GenMsgCycleTimeFast" INT 0 0;
BA_DEF_ BO_  "GenMsgNrOfRepetition" INT 0 0;
BA_DEF_ BO_  "GenMsgDelayTime" INT 0 0;

BA_DEF_DEF_  "NmMessage" "No";
BA_DEF_DEF_  "DiagState" "No";
BA_DEF_DEF_  "DiagResponse" "No";
BA_DEF_DEF_  "GenMsgSendType" "Cycle";
BA_DEF_DEF_  "GenMsgCycleTime" 0;
BA_DEF_DEF_  "GenSigSendType" "Cycle";
BA_DEF_DEF_  "GenSigStartValue" 0;
BA_DEF_DEF_  "GenSigInvalidValue" "";
BA_DEF_DEF_  "GenMsgCycleTimeFast" 0;
BA_DEF_DEF_  "GenMsgNrOfRepetition" 0;
BA_DEF_DEF_  "GenMsgDelayTime" 0;
BA_ "GenMsgCycleTime" BO_ 342 20 ;
BA_ "GenSigInvalidValue" SG_ 342 AmphereLampMode "0x0";
BA_ "GenSigInvalidValue" SG_ 342 AmphereLampSta_Drivingmode "0x0";
BA_ "GenSigInvalidValue" SG_ 342 AmphereLampSta_SW "0x0";
BA_ "GenSigStartValue" SG_ 342 AmphereLampBrtnsVal 255;
BA_ "GenSigInvalidValue" SG_ 342 AmphereLampBrtnsVal "0xFF";
BA_ "GenMsgSendType" BO_ 586 4;
BA_ "GenMsgCycleTime" BO_ 586 100 ;
BA_ "GenMsgCycleTimeFast" BO_ 586 20 ;
BA_ "GenMsgNrOfRepetition" BO_ 586 10 ;
BA_ "GenSigInvalidValue" SG_ 586 ACU_Crashinfo "0x7";
BA_ "GenMsgCycleTime" BO_ 352 20 ;
BA_ "GenSigStartValue" SG_ 352 ACC_Set_Headway 4;
BA_ "GenSigInvalidValue" SG_ 352 ACC_Accelerate_Request "0x7FF";
BA_ "GenSigInvalidValue" SG_ 352 ADAS_TJA_HWAFuncStatus "0xA";
BA_ "GenMsgCycleTime" BO_ 354 20 ;
BA_ "GenSigInvalidValue" SG_ 354 AEB_Decelerate_Request "FFF";
BA_ "GenSigStartValue" SG_ 354 ACC_ShutDownMode 3;
BA_ "GenMsgCycleTime" BO_ 356 20 ;
BA_ "GenSigInvalidValue" SG_ 356 TSR_Targetspeed_Request "0xFF";
BA_ "GenMsgCycleTime" BO_ 1281 100 ;
BA_ "GenSigInvalidValue" SG_ 1281 ADAS_RelativeLogitudinalDistToObject1 "0x7FF";
BA_ "GenSigInvalidValue" SG_ 1281 ADAS_RelativeLateralDistToObject1 "0x7FF";
BA_ "GenSigInvalidValue" SG_ 1281 ADAS_RelativeLogitudinalDistToObject2 "0x7FF";
BA_ "GenSigInvalidValue" SG_ 1281 ADAS_RelativeLateralDistToObject2 "0x7FF";
BA_ "GenMsgCycleTime" BO_ 1282 100 ;
BA_ "GenSigInvalidValue" SG_ 1282 ADAS_RelativeLogitudinalDistToObject3 "0x7FF";
BA_ "GenSigInvalidValue" SG_ 1282 ADAS_RelativeLateralDistToObject3 "0x7FF";
BA_ "GenSigInvalidValue" SG_ 1282 ADAS_RelativeLogitudinalDistToObject4 "0x7FF";
BA_ "GenSigInvalidValue" SG_ 1282 ADAS_RelativeLateralDistToObject4 "0x7FF";
BA_ "GenMsgCycleTime" BO_ 1283 100 ;
BA_ "GenSigInvalidValue" SG_ 1283 ADAS_RelativeLogitudinalDistToObject5 "0x7FF";
BA_ "GenSigInvalidValue" SG_ 1283 ADAS_RelativeLateralDistToObject5 "0x7FF";
BA_ "GenSigInvalidValue" SG_ 1283 ADAS_RelativeLogitudinalDistToObject6 "0x7FF";
BA_ "GenSigInvalidValue" SG_ 1283 ADAS_RelativeLateralDistToObject6 "0x7FF";
BA_ "GenMsgCycleTime" BO_ 1284 100 ;
BA_ "GenSigInvalidValue" SG_ 1284 ADAS_LeftLane_C3 "0x6FFFF";
BA_ "GenSigInvalidValue" SG_ 1284 ADAS_LeftLane_C2 "0x1FFFF";
BA_ "GenSigInvalidValue" SG_ 1284 ADAS_LeftLane_C1 "0x8FF";
BA_ "GenSigInvalidValue" SG_ 1284 ADAS_LeftLane_C0 "0x9FF";
BA_ "GenMsgCycleTime" BO_ 1285 100 ;
BA_ "GenSigInvalidValue" SG_ 1285 ADAS_LeftLeftLane_C3 "0x6FFFF";
BA_ "GenSigInvalidValue" SG_ 1285 ADAS_LeftLeftLane_C2 "0x1FFFF";
BA_ "GenSigInvalidValue" SG_ 1285 ADAS_LeftLeftLane_C1 "0x8FF";
BA_ "GenSigInvalidValue" SG_ 1285 ADAS_LeftLeftLane_C0 "0x9FF";
BA_ "GenMsgCycleTime" BO_ 1286 100 ;
BA_ "GenSigInvalidValue" SG_ 1286 ADAS_RightLane_C3 "0x6FFFF";
BA_ "GenSigInvalidValue" SG_ 1286 ADAS_RightLane_C2 "0x1FFFF";
BA_ "GenSigInvalidValue" SG_ 1286 ADAS_RightLane_C1 "0x8FF";
BA_ "GenSigInvalidValue" SG_ 1286 ADAS_RightLane_C0 "0x9FF";
BA_ "GenMsgCycleTime" BO_ 1287 100 ;
BA_ "GenSigInvalidValue" SG_ 1287 ADAS_RightRightLane_C3 "0x6FFFF";
BA_ "GenSigInvalidValue" SG_ 1287 ADAS_RightRightLane_C2 "0x1FFFF";
BA_ "GenSigInvalidValue" SG_ 1287 ADAS_RightRightLane_C1 "0x8FF";
BA_ "GenSigInvalidValue" SG_ 1287 ADAS_RightRightLane_C0 "0x9FF";
BA_ "GenMsgCycleTime" BO_ 1288 100 ;
BA_ "GenSigInvalidValue" SG_ 1288 ADAS_LeftLaneColor "0x7";
BA_ "GenSigInvalidValue" SG_ 1288 ADAS_LeftLaneType "0x7";
BA_ "GenSigInvalidValue" SG_ 1288 ADAS_LeftLeftLaneType "0x7";
BA_ "GenSigInvalidValue" SG_ 1288 ADAS_RightLaneColor "0x7";
BA_ "GenSigInvalidValue" SG_ 1288 ADAS_RightLaneType "0x7";
BA_ "GenSigInvalidValue" SG_ 1288 ADAS_RightRightLaneType "0x7";
BA_ "GenSigInvalidValue" SG_ 1288 ADAS_RightRightLaneColor "0x7";
BA_ "GenSigInvalidValue" SG_ 1288 ADAS_LeftLeftLaneColor "0x7";
BA_ "GenMsgCycleTime" BO_ 384 50 ;
BA_ "GenSigInvalidValue" SG_ 384 APA_MMI_ConnectStatus "0xF";
BA_ "GenSigInvalidValue" SG_ 384 APA_MMI_3DViewModeStatus "0xF";
BA_ "GenSigInvalidValue" SG_ 384 APA_Status "0x7";
BA_ "GenMsgCycleTime" BO_ 386 50 ;
BA_ "GenSigInvalidValue" SG_ 386 APA_BSDLeftWaringSeverity "0x7F";
BA_ "GenSigInvalidValue" SG_ 386 APA_BSDLeftWaringValid "0x0";
BA_ "GenSigInvalidValue" SG_ 386 APA_BSDRightWaringSeverity "0x7F";
BA_ "GenSigInvalidValue" SG_ 386 APA_BSDRightWaringValid "0x0";
BA_ "GenSigInvalidValue" SG_ 386 APA_BSDStatusValid "0x0";
BA_ "GenMsgCycleTime" BO_ 387 50 ;
BA_ "GenSigInvalidValue" SG_ 387 PAS_APA_DistanceLR_RL "0x1FF";
BA_ "GenSigInvalidValue" SG_ 387 PAS_APA_DistanceLR_RR "0x1FF";
BA_ "GenSigInvalidValue" SG_ 387 PAS_APA_DistanceSR_RL "0xFF";
BA_ "GenSigInvalidValue" SG_ 387 PAS_APA_DistanceSR_RML "0xFF";
BA_ "GenSigInvalidValue" SG_ 387 PAS_APA_DistanceSR_RMR "0xFF";
BA_ "GenSigInvalidValue" SG_ 387 PAS_APA_DistanceSR_RR "0xFF";
BA_ "GenMsgCycleTime" BO_ 388 50 ;
BA_ "GenSigInvalidValue" SG_ 388 PAS_APA_DistanceLR_FL "0x1FF";
BA_ "GenSigInvalidValue" SG_ 388 PAS_APA_DistanceLR_FR "0x1FF";
BA_ "GenSigInvalidValue" SG_ 388 PAS_APA_DistanceSR_FL "0xFF";
BA_ "GenSigInvalidValue" SG_ 388 PAS_APA_DistanceSR_FML "0xFF";
BA_ "GenSigInvalidValue" SG_ 388 PAS_APA_DistanceSR_FMR "0xFF";
BA_ "GenSigInvalidValue" SG_ 388 PAS_APA_DistanceSR_FR "0xFF";
BA_ "GenMsgCycleTime" BO_ 784 200 ;
BA_ "GenSigInvalidValue" SG_ 784 APA_AVM_MCU_Version "0xFFFFFF";
BA_ "GenSigInvalidValue" SG_ 784 APA_AVM_BSP_Version "0xFFFFFF";
BA_ "GenMsgCycleTime" BO_ 786 2000 ;
BA_ "GenSigInvalidValue" SG_ 786 APA_AVM_ZADAS_Version "0xFFFFFF";
BA_ "GenSigInvalidValue" SG_ 786 APA_Avm3d_licenseStatus "0x3";
BA_ "GenSigInvalidValue" SG_ 786 APA_BSD_licenseStatus "0x3";
BA_ "GenMsgCycleTime" BO_ 512 100 ;
BA_ "GenSigInvalidValue" SG_ 512 BMS_battery_outside_Voltage "0xFFFF";
BA_ "GenMsgCycleTime" BO_ 514 100 ;
BA_ "GenSigInvalidValue" SG_ 514 BMS_Err_DischrgAnodeRelay "0x0";
BA_ "GenSigInvalidValue" SG_ 514 BMS_DischargeAnodeRelay_status "0x0";
BA_ "GenSigInvalidValue" SG_ 514 BMS_Err_PrechargeAnodeRelay "0x0";
BA_ "GenSigInvalidValue" SG_ 514 BMS_Precharge_anode_Relay_status "0x0";
BA_ "GenSigInvalidValue" SG_ 514 BMS_ChrgHeatColEnable "0x0";
BA_ "GenSigInvalidValue" SG_ 514 BMS_Sys_ChgorDisChrgSts "0x0";
BA_ "GenSigInvalidValue" SG_ 514 BMS_FastChrgSts "0x0";
BA_ "GenSigInvalidValue" SG_ 514 BMS_SlowChrgSts "0x0";
BA_ "GenSigInvalidValue" SG_ 514 BMS_PauseContinueChrgStus "0x0";
BA_ "GenSigInvalidValue" SG_ 514 BMS_AllowedChrgMaxPower "0x7F";
BA_ "GenMsgCycleTime" BO_ 518 100 ;
BA_ "GenSigInvalidValue" SG_ 518 BMS_battery_WaterTemp_in "0x7FF";
BA_ "GenSigInvalidValue" SG_ 518 BMS_battery_WaterTemp_out "0xFF";
BA_ "GenSigInvalidValue" SG_ 518 BMS_FlowRateReq "0xFF";
BA_ "GenSigStartValue" SG_ 518 BMS_InletWaterTempTarget 130;
BA_ "GenSigInvalidValue" SG_ 518 BMS_InletWaterTempTarget "0xFF";
BA_ "GenMsgCycleTime" BO_ 524 100 ;
BA_ "GenSigInvalidValue" SG_ 524 BMS_TotalErrNumber "0xFF";
BA_ "GenMsgCycleTime" BO_ 528 100 ;
BA_ "GenSigInvalidValue" SG_ 528 BMS_Sys_MinCellV "0xFFFF";
BA_ "GenSigInvalidValue" SG_ 528 BMS_Sys_MaxCellV "0xFFFF";
BA_ "GenMsgCycleTime" BO_ 530 100 ;
BA_ "GenSigInvalidValue" SG_ 530 BMS_Sys_MinCellT "0xFF";
BA_ "GenSigInvalidValue" SG_ 530 BMS_Sys_MaxCellT "0xFF";
BA_ "GenSigInvalidValue" SG_ 530 BMS_Sys_MinCellT_No "0xFF";
BA_ "GenSigInvalidValue" SG_ 530 BMS_Sys_MaxCellT_No "0xFF";
BA_ "GenSigInvalidValue" SG_ 530 BMS_FastChrgTemp "0xFF";
BA_ "GenMsgCycleTime" BO_ 534 100 ;
BA_ "GenSigInvalidValue" SG_ 534 BMS_PosInsulationResistance "0xFFFF";
BA_ "GenSigInvalidValue" SG_ 534 BMS_NegInsulationResistance "0xFFFF";
BA_ "GenSigInvalidValue" SG_ 534 BMS_Sys_SOC "0xFF";
BA_ "GenSigInvalidValue" SG_ 534 BMS_Sys_SOH "0xFF";
BA_ "GenMsgCycleTime" BO_ 340 50 ;
BA_ "GenSigInvalidValue" SG_ 340 RCTA_warm_status_left "0x3";
BA_ "GenSigInvalidValue" SG_ 340 BSDLCA_warm_status_left "0x3";
BA_ "GenSigInvalidValue" SG_ 340 BSDDOW_warm_status_left "0x3";
BA_ "GenSigInvalidValue" SG_ 340 BSD_EnableStatus "0x0";
BA_ "GenMsgCycleTime" BO_ 344 50 ;
BA_ "GenSigInvalidValue" SG_ 344 RCTA_warm_status_right "0x3";
BA_ "GenSigInvalidValue" SG_ 344 BSDLCA_warm_status_right "0x3";
BA_ "GenSigInvalidValue" SG_ 344 BSDDOW_warm_status_right "0x3";
BA_ "GenMsgCycleTime" BO_ 332 20 ;
BA_ "GenSigInvalidValue" SG_ 332 WCBS_EPB_SwitchSstatus "0x3";
BA_ "GenMsgCycleTime" BO_ 274 20 ;
BA_ "GenSigInvalidValue" SG_ 274 EPS_SteeringWheelAngVD "0x0";
BA_ "GenSigInvalidValue" SG_ 274 EPS_TorsionBarTorqueValid "0x0";
BA_ "GenSigInvalidValue" SG_ 274 EPS_TorsionBarTorque "0x3FF";
BA_ "GenSigInvalidValue" SG_ 274 EPS_SteeringWheelAng "0x3FFF";
BA_ "GenSigInvalidValue" SG_ 274 EPS_SteerWheelRotSpd "0xFF";
BA_ "GenSigInvalidValue" SG_ 274 EPS_State_Mode "0x0";
BA_ "GenSigInvalidValue" SG_ 274 EPS_SteerWheelRotSpdVD "0x0";
BA_ "GenMsgCycleTime" BO_ 144 10 ;
BA_ "GenMsgCycleTime" BO_ 146 10 ;
BA_ "GenMsgCycleTime" BO_ 594 100 ;
BA_ "GenSigInvalidValue" SG_ 594 MCU_F_unload_status "0x0";
BA_ "GenSigInvalidValue" SG_ 594 FMCU_HV_Interlock_Falult "0x0";
BA_ "GenSigInvalidValue" SG_ 594 FMCU_Uncap_Falult "0x0";
BA_ "GenMsgCycleTime" BO_ 130 10 ;
BA_ "GenSigInvalidValue" SG_ 130 MCU_F_UdcCurr "0x3FF";
BA_ "GenMsgCycleTime" BO_ 132 100 ;
BA_ "GenSigStartValue" SG_ 132 MCU_F_ThreePhaseCurU 32767;
BA_ "GenSigStartValue" SG_ 132 MCU_F_ThreePhaseCurV 32767;
BA_ "GenSigStartValue" SG_ 132 MCU_F_ThreePhaseCurW 32767;
BA_ "GenMsgCycleTime" BO_ 580 100 ;
BA_ "GenSigStartValue" SG_ 580 MCU_R_ThreePhaseCurU 32767;
BA_ "GenSigStartValue" SG_ 580 MCU_R_ThreePhaseCurV 32767;
BA_ "GenSigStartValue" SG_ 580 MCU_R_ThreePhaseCurW 32767;
BA_ "GenMsgCycleTime" BO_ 608 100 ;
BA_ "GenSigInvalidValue" SG_ 608 MCU_R_unload_status "0x0";
BA_ "GenSigInvalidValue" SG_ 608 RMCU_HV_Interlock_Falult "0x0";
BA_ "GenSigInvalidValue" SG_ 608 RMCU_Uncap_Falult "0x0";
BA_ "GenMsgCycleTime" BO_ 178 10 ;
BA_ "GenSigInvalidValue" SG_ 178 MCU_R_UdcCurr "0x3FF";
BA_ "GenMsgCycleTime" BO_ 772 500 ;
BA_ "GenSigInvalidValue" SG_ 772 OBC_CP_DutyCycleValue "0xFF";
BA_ "GenMsgCycleTime" BO_ 770 500 ;
BA_ "GenSigInvalidValue" SG_ 770 DCDC_Voltage_Input "0xFFFF";
BA_ "GenSigInvalidValue" SG_ 770 DCDC_Current_Input "0x3FF";
BA_ "GenMsgCycleTime" BO_ 776 500 ;
BA_ "GenMsgCycleTime" BO_ 880 1000 ;
BA_ "GenMsgCycleTime" BO_ 372 50 ;
BA_ "GenSigInvalidValue" SG_ 372 VCU_GearPosition "0x0";
BA_ "GenSigInvalidValue" SG_ 372 VCU_PrechrgAnodeRelay_Status "0x0";
BA_ "GenSigInvalidValue" SG_ 372 VCU_DischrgAnodeRelay_Status "0x0";
BA_ "GenSigInvalidValue" SG_ 372 VCU_DischrgCathodeRelay_status "0x0";
BA_ "GenSigInvalidValue" SG_ 372 VCU_VehSysStatus "0x0";
BA_ "GenSigInvalidValue" SG_ 372 VCU_UnlockSts "0x0";
BA_ "GenMsgCycleTime" BO_ 568 100 ;
BA_ "GenSigInvalidValue" SG_ 568 VCU_AllowedMaxDisChrgPowerOfAC "0xFF";
BA_ "GenSigInvalidValue" SG_ 568 VCU_AC_PasCabinAllowedPower "0xFF";
BA_ "GenSigStartValue" SG_ 568 VCU_AC_Permittion 1;
BA_ "GenSigInvalidValue" SG_ 568 FPump_Target_Speed "0xFF";
BA_ "GenSigInvalidValue" SG_ 568 VCU_CoolingFanSt "0x0";
BA_ "GenSigInvalidValue" SG_ 568 RPump_Target_Speed "0xFF";
BA_ "GenMsgCycleTime" BO_ 570 100 ;
BA_ "GenSigInvalidValue" SG_ 570 VCU_FastchrgAllowedPower "0x3FF";
BA_ "GenSigInvalidValue" SG_ 570 VCU_SlowchrgAllowedPower "0xFF";
BA_ "GenSigInvalidValue" SG_ 570 VCU_Fastchrg_Permittion "0x0";
BA_ "GenSigInvalidValue" SG_ 570 VCU_Slowchrg_Permittion "0x0";
BA_ "GenSigStartValue" SG_ 570 VCU_OBC_Permittion 1;
BA_ "GenSigInvalidValue" SG_ 570 VCU_EnergyRecoverySt "0x7";
BA_ "GenSigInvalidValue" SG_ 570 VCU_ChargTotalPower "0xFF";
BA_ "GenSigInvalidValue" SG_ 570 VCU_PowerSysRemainPower "0xFF";
BA_ "GenMsgCycleTime" BO_ 574 100 ;
BA_ "GenSigInvalidValue" SG_ 574 VCU_TbUnlockSts "0x0";
BA_ "GenSigInvalidValue" SG_ 574 VCU_EnduranceMileage "0xFFFF";
BA_ "GenSigStartValue" SG_ 574 VCU_DriveMotorNum 1;
BA_ "GenSigInvalidValue" SG_ 574 VCU_DriveMotorNum "0xFF";
BA_ "GenMsgCycleTime" BO_ 112 10 ;
BA_ "GenSigInvalidValue" SG_ 112 VCU_DriverLeverIntervention "0x1";
BA_ "GenSigInvalidValue" SG_ 112 VCU_Acc_Validity "1";
BA_ "GenSigInvalidValue" SG_ 112 VCU_BrkPed_Pos "FF";
BA_ "GenSigInvalidValue" SG_ 112 VCU_Acc_pedal_position "FF";
BA_ "GenSigInvalidValue" SG_ 112 VCU_Accel_Padel_Pos_Calc "FF";
BA_ "GenMsgCycleTime" BO_ 913 500 ;
BA_ "GenMsgCycleTime" BO_ 656 100 ;
BA_ "GenSigInvalidValue" SG_ 656 Tbox_UnlockSts "0x0";
BA_ "GenSigInvalidValue" SG_ 656 TBOX_FuncSts "0x0";
BA_ "GenSigInvalidValue" SG_ 656 Tbox_PELockCtl "0x1";
BA_ "GenSigInvalidValue" SG_ 656 TBOX_TimeSts "0x0";
BA_ "GenMsgSendType" BO_ 645 4;
BA_ "GenMsgCycleTime" BO_ 645 5000 ;
BA_ "GenMsgCycleTimeFast" BO_ 645 100 ;
BA_ "GenMsgNrOfRepetition" BO_ 645 5 ;
BA_ "GenSigStartValue" SG_ 645 TBOX_Day 1;
BA_ "GenSigStartValue" SG_ 645 TBOX_Month 1;
BA_ "GenSigInvalidValue" SG_ 645 TBOX_Year "0x3F";
BA_ "GenSigInvalidValue" SG_ 645 TBOX_TimeCheckBit "0x1";
BA_ "GenSigInvalidValue" SG_ 645 TBOX_InvalidByte "0xFF";
BA_ "GenMsgCycleTime" BO_ 662 100 ;
BA_ "GenMsgCycleTime" BO_ 664 100 ;
BA_ "GenSigInvalidValue" SG_ 664 Tbox_MMI_GPS_Country_Code "0x0";
BA_ "GenSigStartValue" SG_ 664 Tbox_MMI_FICM_Available 1;
BA_ "GenMsgCycleTime" BO_ 148 10 ;
BA_ "GenMsgCycleTime" BO_ 328 20 ;
BA_ "GenSigInvalidValue" SG_ 328 EPB_SwitchSta_L "0x3";
BA_ "GenMsgCycleTime" BO_ 336 20 ;
BA_ "GenSigInvalidValue" SG_ 336 EPB_SwitchSta_R "0x3";
BA_ "NmMessage" BO_ 1028 1 ;
BA_ "GenMsgSendType" BO_ 1028 2;
BA_ "GenSigSendType" SG_ 1028 AC_NM_Message0 2;
BA_ "GenSigSendType" SG_ 1028 AC_NM_Message1 2;
BA_ "GenSigSendType" SG_ 1028 AC_NM_Message2 2;
BA_ "GenSigSendType" SG_ 1028 AC_NM_Message3 2;
BA_ "GenSigSendType" SG_ 1028 AC_NM_Message4 2;
BA_ "GenSigSendType" SG_ 1028 AC_NM_Message5 2;
BA_ "GenSigSendType" SG_ 1028 AC_NM_Message6 2;
BA_ "GenSigSendType" SG_ 1028 AC_NM_Message7 2;
BA_ "GenMsgCycleTime" BO_ 584 100 ;
BA_ "GenSigInvalidValue" SG_ 584 AC_AutoMode "0x0";
BA_ "GenSigInvalidValue" SG_ 584 AC_ActualBlowingMode "0x0";
BA_ "GenSigInvalidValue" SG_ 584 AC_ActualCirculationMode "0x0";
BA_ "GenSigStartValue" SG_ 584 AC_TempSetPoint 31;
BA_ "GenSigInvalidValue" SG_ 584 AC_TempSetPoint "0x1F";
BA_ "GenSigInvalidValue" SG_ 584 AC_ActualAirQuantity "0x0";
BA_ "GenSigInvalidValue" SG_ 584 AC_CoolingStaus "0x0";
BA_ "GenSigInvalidValue" SG_ 584 AC_MaxCooingStaus "0x0";
BA_ "GenSigInvalidValue" SG_ 584 AC_OffStaus "0x0";
BA_ "GenSigInvalidValue" SG_ 584 AC_PM25_Status "0x0";
BA_ "GenSigInvalidValue" SG_ 584 AC_RearViewMirroHeatStatus "0x0";
BA_ "GenSigInvalidValue" SG_ 584 AC_NegativeIconGenStus "0x0";
BA_ "GenMsgCycleTime" BO_ 607 100 ;
BA_ "GenSigInvalidValue" SG_ 607 AC_BatteryPumpSpeed "0xff";
BA_ "GenSigInvalidValue" SG_ 607 AC_AmbientAirTemperature_Validity "0x1";
BA_ "GenSigInvalidValue" SG_ 607 AC_WorkingResponse_Status "0x0";
BA_ "GenSigInvalidValue" SG_ 607 AC_unload_Status "0x0";
BA_ "GenMsgCycleTime" BO_ 390 50 ;
BA_ "GenSigInvalidValue" SG_ 390 AVM_BSDLeftWaringSeverity "0x7F";
BA_ "GenSigInvalidValue" SG_ 390 AVM_BSDLeftWaringValid "0x0";
BA_ "GenSigInvalidValue" SG_ 390 AVM_BSDRightWaringSeverity "0x7F";
BA_ "GenSigInvalidValue" SG_ 390 AVM_BSDRightWaringValid "0x0";
BA_ "GenSigInvalidValue" SG_ 390 AVM_BSDStatusValid "0x0";
BA_ "GenMsgCycleTime" BO_ 392 50 ;
BA_ "GenSigInvalidValue" SG_ 392 AVM_MMI_ConnectStatus "0xf";
BA_ "GenSigInvalidValue" SG_ 392 AVM_MMI_EcuStatus "0xf";
BA_ "GenSigInvalidValue" SG_ 392 AVM_MMI_VideoOutputStatus "0x3";
BA_ "GenSigInvalidValue" SG_ 392 AVM_MMI_AVM3DViewModeStatus "0xf";
BA_ "GenMsgCycleTime" BO_ 788 2000 ;
BA_ "GenSigInvalidValue" SG_ 788 AVM_MCU_Version "0xFFFFFF";
BA_ "GenSigInvalidValue" SG_ 788 AVM_BSP_Version "0xFFFFFF";
BA_ "GenMsgCycleTime" BO_ 790 2000 ;
BA_ "GenSigInvalidValue" SG_ 790 AVM_ZADAS_Version "0xFFFFFF";
BA_ "GenSigInvalidValue" SG_ 790 Avm3d_licenseStatus "0x3";
BA_ "GenSigInvalidValue" SG_ 790 BSD_licenseStatus "0x3";
BA_ "NmMessage" BO_ 1024 1 ;
BA_ "GenMsgSendType" BO_ 1024 2;
BA_ "GenSigSendType" SG_ 1024 BCM_NM_Message0 2;
BA_ "GenSigSendType" SG_ 1024 BCM_NM_Message1 2;
BA_ "GenSigSendType" SG_ 1024 BCM_NM_Message2 2;
BA_ "GenSigSendType" SG_ 1024 BCM_NM_Message3 2;
BA_ "GenSigSendType" SG_ 1024 BCM_NM_Message4 2;
BA_ "GenSigSendType" SG_ 1024 BCM_NM_Message5 2;
BA_ "GenSigSendType" SG_ 1024 BCM_NM_Message6 2;
BA_ "GenSigSendType" SG_ 1024 BCM_NM_Message7 2;
BA_ "GenMsgCycleTime" BO_ 338 50 ;
BA_ "GenSigInvalidValue" SG_ 338 BCM_WiperMaintainFuncCtrStus "0x0";
BA_ "GenSigInvalidValue" SG_ 338 BCM_PowerMode "0x0";
BA_ "GenSigInvalidValue" SG_ 338 BCM_RearViewMirror "0x0";
BA_ "GenSigInvalidValue" SG_ 338 BCM_BkSeat_1_beltBucklevalidity "0x0";
BA_ "GenSigInvalidValue" SG_ 338 BCM_BkSeat_2_beltBucklevalidity "0x0";
BA_ "GenSigInvalidValue" SG_ 338 BCM_BkSeat_3_beltBucklevalidity "0x0";
BA_ "GenSigInvalidValue" SG_ 338 BCM_RainAutoClsWindowFuncStus "0";
BA_ "GenSigInvalidValue" SG_ 338 BCM_LockVehicleWarmingTipStus "0";
BA_ "GenSigInvalidValue" SG_ 338 BCM_VehicleCourtesyLampFuncStus "0";
BA_ "GenSigInvalidValue" SG_ 338 BCM_AccLampSetStus "0";
BA_ "GenMsgCycleTime" BO_ 588 100 ;
BA_ "GenSigInvalidValue" SG_ 588 FLWS_POS_VIT_FL "0x7F";
BA_ "GenSigInvalidValue" SG_ 588 FRWS_POS_VIT_FL "0x7F";
BA_ "GenSigInvalidValue" SG_ 588 RLWS_POS_VIT_FL "0x7F";
BA_ "GenSigInvalidValue" SG_ 588 RRWS_POS_VIT_FL "0x7F";
BA_ "GenMsgCycleTime" BO_ 589 100 ;
BA_ "GenSigInvalidValue" SG_ 589 BCM_LFDoorLockStatus "0x7";
BA_ "GenSigInvalidValue" SG_ 589 BCM_TrunkDoorLockSts "0x7";
BA_ "GenSigInvalidValue" SG_ 589 BCM_RFDoorLockStatus "0x7";
BA_ "GenSigInvalidValue" SG_ 589 BCM_LRDoorLockStatus "0x7";
BA_ "GenSigInvalidValue" SG_ 589 BCM_RRDoorLockStatus "0x7";
BA_ "GenMsgCycleTime" BO_ 610 200 ;
BA_ "GenSigInvalidValue" SG_ 610 BCM_FL_TirePrs "0xFF";
BA_ "GenSigInvalidValue" SG_ 610 BCM_FR_TirePrs "0xFF";
BA_ "GenSigInvalidValue" SG_ 610 BCM_RL_TirePrs "0xFF";
BA_ "GenSigInvalidValue" SG_ 610 BCM_RR_TirePrs "0xFF";
BA_ "GenMsgCycleTime" BO_ 612 200 ;
BA_ "GenSigInvalidValue" SG_ 612 BCM_FL_TireTpt "0xFF";
BA_ "GenSigInvalidValue" SG_ 612 BCM_FR_TireTpt "0xFF";
BA_ "GenSigInvalidValue" SG_ 612 BCM_RL_TireTpt "0xFF";
BA_ "GenSigInvalidValue" SG_ 612 BCM_RR_TireTpt "0xFF";
BA_ "GenMsgCycleTime" BO_ 613 200 ;
BA_ "GenMsgSendType" BO_ 665 2;
BA_ "GenMsgCycleTimeFast" BO_ 665 100 ;
BA_ "GenMsgNrOfRepetition" BO_ 665 3 ;
BA_ "GenSigSendType" SG_ 665 DSM_D_SlideDirection 3;
BA_ "GenSigSendType" SG_ 665 DSM_D_FrontLiftDirection 3;
BA_ "GenSigSendType" SG_ 665 DSM_D_ReclinerDirection 3;
BA_ "GenSigSendType" SG_ 665 DSM_D_AllLiftDirection 3;
BA_ "GenSigSendType" SG_ 665 DSM_DrvSeatHandyEntryExitSetStus 3;
BA_ "GenSigInvalidValue" SG_ 665 DSM_DrvSeatHandyEntryExitSetStus "0x0";
BA_ "GenSigSendType" SG_ 665 DSM_D_SlidePosPercentFinal 3;
BA_ "GenSigInvalidValue" SG_ 665 DSM_D_SlidePosPercentFinal "0x7F";
BA_ "GenSigSendType" SG_ 665 DSM_D_FrontLiftPosPercentFinal 3;
BA_ "GenSigInvalidValue" SG_ 665 DSM_D_FrontLiftPosPercentFinal "0x7F";
BA_ "GenSigSendType" SG_ 665 DSM_D_ReclinerPosPercentFinal 3;
BA_ "GenSigInvalidValue" SG_ 665 DSM_D_ReclinerPosPercentFinal "0x7F";
BA_ "GenSigSendType" SG_ 665 DSM_D_AllLiftPosPercentFinal 3;
BA_ "GenSigInvalidValue" SG_ 665 DSM_D_AllLiftPosPercentFinal "0x7F";
BA_ "GenMsgSendType" BO_ 667 2;
BA_ "GenMsgCycleTimeFast" BO_ 667 100 ;
BA_ "GenMsgNrOfRepetition" BO_ 667 3 ;
BA_ "GenSigSendType" SG_ 667 DSM_P_SlideDirection 3;
BA_ "GenSigSendType" SG_ 667 DSM_P_FrontLiftDirection 3;
BA_ "GenSigSendType" SG_ 667 DSM_P_ReclinerDirection 3;
BA_ "GenSigSendType" SG_ 667 DSM_P_AllLiftDirection 3;
BA_ "GenSigSendType" SG_ 667 DSM_P_SlidePosPercentFinal 3;
BA_ "GenSigInvalidValue" SG_ 667 DSM_P_SlidePosPercentFinal "0x7F";
BA_ "GenSigSendType" SG_ 667 DSM_P_FrontLiftPosPercentFinal 3;
BA_ "GenSigInvalidValue" SG_ 667 DSM_P_FrontLiftPosPercentFinal "0x7F";
BA_ "GenSigSendType" SG_ 667 DSM_P_ReclinerPosPercentFinal 3;
BA_ "GenSigInvalidValue" SG_ 667 DSM_P_ReclinerPosPercentFinal "0x7F";
BA_ "GenSigSendType" SG_ 667 DSM_P_AllLiftPosPercentFinal 3;
BA_ "GenSigInvalidValue" SG_ 667 DSM_P_AllLiftPosPercentFinal "0x7F";
BA_ "GenMsgCycleTime" BO_ 659 200 ;
BA_ "GenMsgCycleTime" BO_ 853 200 ;
BA_ "GenMsgCycleTimeFast" BO_ 853 100 ;
BA_ "GenMsgNrOfRepetition" BO_ 853 3 ;
BA_ "GenSigInvalidValue" SG_ 853 PSR_PlatfondPellucidityStus "0x7f";
BA_ "GenMsgCycleTime" BO_ 856 200 ;
